VERSION "created by canmatrix"

NS_ :

BS_:

BU_:

BO_ 2649702903 ParameterResponse: 8 Vector__XXX
 SG_ ParameterResponse_MUX M : 0|11@1- (1,0) [-1024|1023] "" Vector__XXX
 SG_ Meta1028 m1479 : 11|3@1+ (1,0) [0|7] "" Vector__XXX
 SG_ ReadParam_status1028 m1479 : 14|2@1+ (1,0) [0|1] "" Vector__XXX
 SG_ TempInvCurrent m1479 : 16|16@1+ (1,0) [0|3000] "A" Vector__XXX
 SG_ Meta1029 m1480 : 11|3@1+ (1,0) [0|7] "" Vector__XXX
 SG_ ReadParam_status1029 m1480 : 14|2@1+ (1,0) [0|1] "" Vector__XXX
 SG_ Mx1CycleLimit m1480 : 32|32@1+ (1,0) [0|4294967295] "" Vector__XXX
 SG_ Meta1030 m1481 : 11|3@1+ (1,0) [0|7] "" Vector__XXX
 SG_ ReadParam_status1030 m1481 : 14|2@1+ (1,0) [0|1] "" Vector__XXX
 SG_ Mx2CyclesLimit m1481 : 32|32@1+ (1,0) [0|4294967295] "" Vector__XXX
 SG_ Meta1031 m1482 : 11|3@1+ (1,0) [0|7] "" Vector__XXX
 SG_ ReadParam_status1031 m1482 : 14|2@1+ (1,0) [0|1] "" Vector__XXX
 SG_ K1CyclesLimit m1482 : 32|32@1+ (1,0) [0|4294967295] "" Vector__XXX
 SG_ Meta1032 m1483 : 11|3@1+ (1,0) [0|7] "" Vector__XXX
 SG_ ReadParam_status1032 m1483 : 14|2@1+ (1,0) [0|1] "" Vector__XXX
 SG_ K2CyclesLimit m1483 : 32|32@1+ (1,0) [0|4294967295] "" Vector__XXX
 SG_ Meta1033 m1484 : 11|3@1+ (1,0) [0|7] "" Vector__XXX
 SG_ ReadParam_status1033 m1484 : 14|2@1+ (1,0) [0|1] "" Vector__XXX
 SG_ MX1CycleCount m1484 : 32|32@1+ (1,0) [0|4294967295] "" Vector__XXX
 SG_ Meta1034 m1485 : 11|3@1+ (1,0) [0|7] "" Vector__XXX
 SG_ ReadParam_status1034 m1485 : 14|2@1+ (1,0) [0|1] "" Vector__XXX
 SG_ MX2CycleCount m1485 : 32|32@1+ (1,0) [0|4294967295] "" Vector__XXX
 SG_ Meta1035 m1486 : 11|3@1+ (1,0) [0|7] "" Vector__XXX
 SG_ ReadParam_status1035 m1486 : 14|2@1+ (1,0) [0|1] "" Vector__XXX
 SG_ K1CycleCount m1486 : 32|32@1+ (1,0) [0|4294967295] "" Vector__XXX
 SG_ Meta1036 m1487 : 11|3@1+ (1,0) [0|7] "" Vector__XXX
 SG_ ReadParam_status1036 m1487 : 14|2@1+ (1,0) [0|1] "" Vector__XXX
 SG_ K2CycleCount m1487 : 32|32@1+ (1,0) [0|4294967295] "" Vector__XXX
 SG_ Meta1037 m1488 : 11|3@1+ (1,0) [0|7] "" Vector__XXX
 SG_ ReadParam_status1037 m1488 : 14|2@1+ (1,0) [0|1] "" Vector__XXX
 SG_ MX1DIIndex m1488 : 16|8@1+ (1,0) [0|200] "" Vector__XXX
 SG_ MX2DIIndex m1488 : 24|8@1+ (1,0) [0|200] "" Vector__XXX
 SG_ K1DIIndex m1488 : 32|8@1+ (1,0) [0|200] "" Vector__XXX
 SG_ K2DIIndex m1488 : 40|8@1+ (1,0) [0|200] "" Vector__XXX
 SG_ Meta1038 m1489 : 11|3@1+ (1,0) [0|7] "" Vector__XXX
 SG_ ReadParam_status1038 m1489 : 14|2@1+ (1,0) [0|1] "" Vector__XXX
 SG_ DO5Command m1489 : 16|2@1+ (1,0) [0|1] "" Vector__XXX
 SG_ DO5Controller m1489 : 18|2@1+ (1,0) [0|1] "" Vector__XXX
 SG_ InvertDI6 m1489 : 20|2@1+ (1,0) [0|1] "" Vector__XXX
 SG_ InvertDI7 m1489 : 22|2@1+ (1,0) [0|1] "" Vector__XXX
 SG_ InvertDI8 m1489 : 24|2@1+ (1,0) [0|1] "" Vector__XXX
 SG_ InvertDI9 m1489 : 26|2@1+ (1,0) [0|1] "" Vector__XXX
 SG_ InvertDO5 m1489 : 28|2@1+ (1,0) [0|1] "" Vector__XXX
 SG_ Meta1039 m1490 : 11|3@1+ (1,0) [0|7] "" Vector__XXX
 SG_ ReadParam_status1039 m1490 : 14|2@1+ (1,0) [1|3] "" Vector__XXX
 SG_ ExternalInhibitFault m1490 : 16|2@1+ (1,0) [0|3] "" Vector__XXX
 SG_ ExternalInhibitState m1490 : 32|16@1+ (1,0) [0|65535] "" Vector__XXX
 SG_ Meta1040 m1491 : 11|3@1+ (1,0) [0|7] "" Vector__XXX
 SG_ ReadParam_status1040 m1491 : 14|2@1+ (1,0) [0|1] "" Vector__XXX
 SG_ enable3 m1491 : 16|2@1+ (1,0) [0|1] "" Vector__XXX
 SG_ forceTime m1491 : 32|16@1- (0.1,0) [0|3270] "ms" Vector__XXX
 SG_ waitTime m1491 : 48|16@1- (0.1,0) [0|3270] "ms" Vector__XXX
 SG_ Meta1041 m1492 : 11|3@1+ (1,0) [0|7] "" Vector__XXX
 SG_ ReadParam_status1041 m1492 : 14|2@1+ (1,0) [0|1] "" Vector__XXX
 SG_ inhibitTime m1492 : 16|16@1- (0.1,0) [0|3270] "ms" Vector__XXX
 SG_ enableAutoSync m1492 : 32|2@1+ (1,0) [0|1] "" Vector__XXX
 SG_ autoSyncTime m1492 : 48|16@1- (0.1,0) [0|3270] "ms" Vector__XXX
 SG_ Meta1042 m1495 : 11|3@1+ (1,0) [0|7] "" Vector__XXX
 SG_ ReadParam_status1042 m1495 : 14|2@1+ (1,0) [0|1] "" Vector__XXX
 SG_ FilterTau m1495 : 16|16@1+ (1,0) [10|15000] "ms" Vector__XXX
 SG_ Meta1043 m1497 : 11|3@1+ (1,0) [0|7] "" Vector__XXX
 SG_ ReadParam_status1043 m1497 : 14|2@1+ (1,0) [0|1] "" Vector__XXX
 SG_ ActiveInterface m1497 : 16|16@1+ (1,0) [0|1] "" Vector__XXX
 SG_ Meta1044 m1500 : 11|3@1+ (1,0) [0|7] "" Vector__XXX
 SG_ ReadParam_status1044 m1500 : 14|2@1+ (1,0) [0|1] "" Vector__XXX
 SG_ MODBUSTimeout m1500 : 16|16@1+ (0.01,0) [0|600.00] "s" Vector__XXX
 SG_ Meta1045 m1501 : 11|3@1+ (1,0) [0|7] "" Vector__XXX
 SG_ ReadParam_status1045 m1501 : 14|2@1+ (1,0) [0|1] "" Vector__XXX
 SG_ stopIRamp m1501 : 16|16@1+ (0.1,0) [0|6000] "A/s" Vector__XXX
 SG_ Meta1046 m1502 : 11|3@1+ (1,0) [0|7] "" Vector__XXX
 SG_ ReadParam_status1046 m1502 : 14|2@1+ (1,0) [0|1] "" Vector__XXX
 SG_ propGain m1502 : 16|16@1+ (0.001,0) [0|50] "V/A" Vector__XXX
 SG_ intGain m1502 : 32|16@1+ (0.001,0) [0|50] "V/A" Vector__XXX
 SG_ antiWupGain m1502 : 48|16@1+ (0.1,0) [0|5000] "V/A" Vector__XXX
 SG_ Meta1047 m1503 : 11|3@1+ (1,0) [0|7] "" Vector__XXX
 SG_ ReadParam_status1047 m1503 : 14|2@1+ (1,0) [0|1] "" Vector__XXX
 SG_ vMeasFilt_Tc m1503 : 16|16@1+ (0.001,0) [0|60] "s" Vector__XXX
 SG_ vRefFilt_Tc m1503 : 32|16@1+ (0.001,0) [0|60] "s" Vector__XXX
 SG_ Meta1048 m1504 : 11|3@1+ (1,0) [0|7] "" Vector__XXX
 SG_ ReadParam_status1048 m1504 : 14|2@1+ (1,0) [0|1] "" Vector__XXX
 SG_ slope0 m1504 : 16|16@1+ (0.1,0) [0|5000] "kVAr/V" Vector__XXX
 SG_ deadband0 m1504 : 32|16@1+ (0.1,0) [0|250] "V" Vector__XXX
 SG_ limit1 m1504 : 48|16@1+ (0.1,0) [0|1400] "kVAr" Vector__XXX
 SG_ Meta1049 m1505 : 11|3@1+ (1,0) [0|7] "" Vector__XXX
 SG_ ReadParam_status1049 m1505 : 14|2@1+ (1,0) [0|1] "" Vector__XXX
 SG_ fMeasFilt_Tc m1505 : 16|16@1+ (0.001,0) [0|60] "s" Vector__XXX
 SG_ fRefFilt_Tc m1505 : 32|16@1+ (0.001,0) [0|60] "ms" Vector__XXX
 SG_ Meta1050 m1506 : 11|3@1+ (1,0) [0|7] "" Vector__XXX
 SG_ ReadParam_status1050 m1506 : 14|2@1+ (1,0) [0|1] "" Vector__XXX
 SG_ slope1 m1506 : 16|16@1+ (0.1,0) [0|5000] "kW/Hz" Vector__XXX
 SG_ deadband1 m1506 : 32|16@1+ (0.001,0) [0|20] "Hz" Vector__XXX
 SG_ limit2 m1506 : 48|16@1+ (0.1,0) [0|1400] "kW" Vector__XXX
 SG_ Meta1051 m1507 : 11|3@1+ (1,0) [0|7] "" Vector__XXX
 SG_ ReadParam_status1051 m1507 : 14|2@1+ (1,0) [0|1] "" Vector__XXX
 SG_ fMeasDerFilt_Tc m1507 : 16|16@1+ (0.001,0) [0|60] "s" Vector__XXX
 SG_ Meta1052 m1508 : 11|3@1+ (1,0) [0|7] "" Vector__XXX
 SG_ ReadParam_status1052 m1508 : 14|2@1+ (1,0) [0|1] "" Vector__XXX
 SG_ gain m1508 : 16|16@1+ (0.01,0) [0|500] "kW/Hz/s" Vector__XXX
 SG_ deadband2 m1508 : 32|16@1+ (0.1,0) [0|5000] "Hz/s" Vector__XXX
 SG_ Meta1053 m1509 : 11|3@1+ (1,0) [0|7] "" Vector__XXX
 SG_ ReadParam_status1053 m1509 : 14|2@1+ (1,0) [0|1] "" Vector__XXX
 SG_ VI_comp_enable m1509 : 16|2@1+ (1,0) [0|1] "" Vector__XXX
 SG_ blackStartVRamp m1509 : 32|16@1+ (0.1,0) [0|5000] "V/s" Vector__XXX
 SG_ Meta1054 m1510 : 11|3@1+ (1,0) [0|7] "" Vector__XXX
 SG_ ReadParam_status1054 m1510 : 14|2@1+ (1,0) [0|1] "" Vector__XXX
 SG_ vLimMax m1510 : 16|16@1+ (0.1,0) [0|1000] "V" Vector__XXX
 SG_ vLimMin m1510 : 32|16@1+ (0.1,0) [0|1000] "V" Vector__XXX
 SG_ Meta1055 m1511 : 11|3@1+ (1,0) [0|7] "" Vector__XXX
 SG_ ReadParam_status1055 m1511 : 14|2@1+ (1,0) [0|1] "" Vector__XXX
 SG_ fLimMax m1511 : 16|16@1+ (0.01,0) [0|120] "Hz" Vector__XXX
 SG_ fLimMin m1511 : 32|16@1+ (0.01,0) [0|120] "Hz" Vector__XXX
 SG_ Meta1056 m1512 : 11|3@1+ (1,0) [0|7] "" Vector__XXX
 SG_ ReadParam_status1056 m1512 : 14|2@1+ (1,0) [0|1] "" Vector__XXX
 SG_ vDroop m1512 : 16|16@1+ (0.01,0) [0|100] "%" Vector__XXX
 SG_ fDroop m1512 : 32|16@1+ (0.01,0) [0|100] "%" Vector__XXX
 SG_ Meta1057 m1513 : 11|3@1+ (1,0) [0|7] "" Vector__XXX
 SG_ ReadParam_status1057 m1513 : 14|2@1+ (1,0) [0|1] "" Vector__XXX
 SG_ vDeadband m1513 : 16|16@1+ (0.1,0) [0|200] "V" Vector__XXX
 SG_ fDeadband m1513 : 32|16@1+ (0.001,0) [0|20] "Hz" Vector__XXX
 SG_ Meta1058 m1514 : 11|3@1+ (1,0) [0|7] "" Vector__XXX
 SG_ ReadParam_status1058 m1514 : 14|2@1+ (1,0) [0|1] "" Vector__XXX
 SG_ avr_propGain m1514 : 16|16@1+ (0.1,0) [0|500] "" Vector__XXX
 SG_ avr_intGain m1514 : 32|16@1+ (0.001,0) [0|50] "" Vector__XXX
 SG_ avr_antiWupGain m1514 : 48|16@1+ (0.1,0) [0.000|6500.000] "" Vector__XXX
 SG_ Meta1059 m1515 : 11|3@1+ (1,0) [0|7] "" Vector__XXX
 SG_ ReadParam_status1059 m1515 : 14|2@1+ (1,0) [0|1] "" Vector__XXX
 SG_ gov_propGain m1515 : 16|16@1+ (0.1,0) [0|500] "" Vector__XXX
 SG_ gov_intGain m1515 : 32|16@1+ (0.001,0) [0|50] "" Vector__XXX
 SG_ gov_antiWupGain m1515 : 48|16@1+ (0.1,0) [0.000|6500.000] "" Vector__XXX
 SG_ Meta1060 m1516 : 11|3@1+ (1,0) [0|7] "" Vector__XXX
 SG_ ReadParam_status1060 m1516 : 14|2@1+ (1,0) [0|1] "" Vector__XXX
 SG_ var_propGain m1516 : 16|16@1+ (0.001,0) [0|10] "" Vector__XXX
 SG_ var_intGain m1516 : 32|16@1+ (0.001,0) [0|50] "" Vector__XXX
 SG_ var_antiWupGain m1516 : 48|16@1+ (0.1,0) [0.000|6500.000] "" Vector__XXX
 SG_ Meta1061 m1517 : 11|3@1+ (1,0) [0|7] "" Vector__XXX
 SG_ ReadParam_status1061 m1517 : 14|2@1+ (1,0) [0|1] "" Vector__XXX
 SG_ vin_damp m1517 : 16|16@1+ (0.001,0) [0|10] "" Vector__XXX
 SG_ vin_H_sec m1517 : 32|16@1+ (0.001,0) [0.001|60] "" Vector__XXX
 SG_ vin_antiWupGain m1517 : 48|16@1+ (0.1,0) [0.000|6500.000] "" Vector__XXX
 SG_ Meta1062 m1518 : 11|3@1+ (1,0) [0|7] "" Vector__XXX
 SG_ ReadParam_status1062 m1518 : 14|2@1+ (1,0) [0|1] "" Vector__XXX
 SG_ block_vErr_pct m1518 : 16|16@1+ (0.01,0) [0.000|200.000] "" Vector__XXX
 SG_ block_qErr_pct m1518 : 32|16@1+ (0.01,0) [0.000|200.000] "" Vector__XXX
 SG_ block_onDelay_ms m1518 : 48|16@1+ (0.1,0) [0.000|6000.000] "" Vector__XXX
 SG_ Meta1063 m1519 : 11|3@1+ (1,0) [0|7] "" Vector__XXX
 SG_ ReadParam_status1063 m1519 : 14|2@1+ (1,0) [0|1] "" Vector__XXX
 SG_ ramp_power0 m1519 : 16|16@1+ (0.1,0) [0|5000] "kW" Vector__XXX
 SG_ ramp_time0 m1519 : 32|16@1+ (0.001,0) [0|60] "s" Vector__XXX
 SG_ Meta1064 m1520 : 11|3@1+ (1,0) [0|7] "" Vector__XXX
 SG_ ReadParam_status1064 m1520 : 14|2@1+ (1,0) [0|1] "" Vector__XXX
 SG_ ramp_power1 m1520 : 16|16@1+ (0.1,0) [0|5000] "kW" Vector__XXX
 SG_ ramp_time1 m1520 : 32|16@1+ (0.001,0) [0|60] "s" Vector__XXX
 SG_ Meta1065 m1521 : 11|3@1+ (1,0) [0|7] "" Vector__XXX
 SG_ ReadParam_status1065 m1521 : 14|2@1+ (1,0) [0|1] "" Vector__XXX
 SG_ vFilterTrPa m1521 : 16|16@1+ (0.001,0) [0|60] "s" Vector__XXX
 SG_ Meta1066 m1522 : 11|3@1+ (1,0) [0|7] "" Vector__XXX
 SG_ ReadParam_status1066 m1522 : 14|2@1+ (1,0) [0|1] "" Vector__XXX
 SG_ NumActivePoints24 m1522 : 48|16@1+ (1,0) [0|20] "" Vector__XXX
 SG_ Meta1067 m1523 : 11|3@1+ (1,0) [0|7] "" Vector__XXX
 SG_ ReadParam_status1067 m1523 : 14|2@1+ (1,0) [0|1] "" Vector__XXX
 SG_ _0148 m1523 : 16|16@1- (0.1,0) [-3276.8|3276.7] "% nominal Power" Vector__XXX
 SG_ _0248 m1523 : 32|16@1- (0.1,0) [-3276.8|3276.7] "% nominal Power" Vector__XXX
 SG_ _0348 m1523 : 48|16@1- (0.1,0) [-3276.8|3276.7] "% nominal Power" Vector__XXX
 SG_ Meta1068 m1524 : 11|3@1+ (1,0) [0|7] "" Vector__XXX
 SG_ ReadParam_status1068 m1524 : 14|2@1+ (1,0) [0|1] "" Vector__XXX
 SG_ _0448 m1524 : 16|16@1- (0.1,0) [-3276.8|3276.7] "% nominal Power" Vector__XXX
 SG_ _0548 m1524 : 32|16@1- (0.1,0) [-3276.8|3276.7] "% nominal Power" Vector__XXX
 SG_ _0648 m1524 : 48|16@1- (0.1,0) [-3276.8|3276.7] "% nominal Power" Vector__XXX
 SG_ Meta1069 m1525 : 11|3@1+ (1,0) [0|7] "" Vector__XXX
 SG_ ReadParam_status1069 m1525 : 14|2@1+ (1,0) [0|1] "" Vector__XXX
 SG_ _0748 m1525 : 16|16@1- (0.1,0) [-3276.8|3276.7] "% nominal Power" Vector__XXX
 SG_ _0848 m1525 : 32|16@1- (0.1,0) [-3276.8|3276.7] "% nominal Power" Vector__XXX
 SG_ _0948 m1525 : 48|16@1- (0.1,0) [-3276.8|3276.7] "% nominal Power" Vector__XXX
 SG_ Meta1070 m1526 : 11|3@1+ (1,0) [0|7] "" Vector__XXX
 SG_ ReadParam_status1070 m1526 : 14|2@1+ (1,0) [0|1] "" Vector__XXX
 SG_ _1048 m1526 : 16|16@1- (0.1,0) [-3276.8|3276.7] "% nominal Power" Vector__XXX
 SG_ _1148 m1526 : 32|16@1- (0.1,0) [-3276.8|3276.7] "% nominal Power" Vector__XXX
 SG_ _1248 m1526 : 48|16@1- (0.1,0) [-3276.8|3276.7] "% nominal Power" Vector__XXX
 SG_ Meta1071 m1527 : 11|3@1+ (1,0) [0|7] "" Vector__XXX
 SG_ ReadParam_status1071 m1527 : 14|2@1+ (1,0) [0|1] "" Vector__XXX
 SG_ _1348 m1527 : 16|16@1- (0.1,0) [-3276.8|3276.7] "% nominal Power" Vector__XXX
 SG_ _1448 m1527 : 32|16@1- (0.1,0) [-3276.8|3276.7] "% nominal Power" Vector__XXX
 SG_ _1548 m1527 : 48|16@1- (0.1,0) [-3276.8|3276.7] "% nominal Power" Vector__XXX
 SG_ Meta1072 m1528 : 11|3@1+ (1,0) [0|7] "" Vector__XXX
 SG_ ReadParam_status1072 m1528 : 14|2@1+ (1,0) [0|1] "" Vector__XXX
 SG_ _1648 m1528 : 16|16@1- (0.1,0) [-3276.8|3276.7] "% nominal Power" Vector__XXX
 SG_ _1748 m1528 : 32|16@1- (0.1,0) [-3276.8|3276.7] "% nominal Power" Vector__XXX
 SG_ _1848 m1528 : 48|16@1- (0.1,0) [-3276.8|3276.7] "% nominal Power" Vector__XXX
 SG_ Meta1073 m1529 : 11|3@1+ (1,0) [0|7] "" Vector__XXX
 SG_ ReadParam_status1073 m1529 : 14|2@1+ (1,0) [0|1] "" Vector__XXX
 SG_ _1948 m1529 : 16|16@1- (0.1,0) [-3276.8|3276.7] "% nominal Power" Vector__XXX
 SG_ _2048 m1529 : 32|16@1- (0.1,0) [-3276.8|3276.7] "% nominal Power" Vector__XXX
 SG_ Meta1074 m1530 : 11|3@1+ (1,0) [0|7] "" Vector__XXX
 SG_ ReadParam_status1074 m1530 : 14|2@1+ (1,0) [0|1] "" Vector__XXX
 SG_ _0149 m1530 : 16|16@1- (0.1,0) [-3276.8|3276.7] "% nominal VAr" Vector__XXX
 SG_ _0249 m1530 : 32|16@1- (0.1,0) [-3276.8|3276.7] "% nominal VAr" Vector__XXX
 SG_ _0349 m1530 : 48|16@1- (0.1,0) [-3276.8|3276.7] "% nominal VAr" Vector__XXX
 SG_ Meta1075 m1531 : 11|3@1+ (1,0) [0|7] "" Vector__XXX
 SG_ ReadParam_status1075 m1531 : 14|2@1+ (1,0) [0|1] "" Vector__XXX
 SG_ _0449 m1531 : 16|16@1- (0.1,0) [-3276.8|3276.7] "% nominal VAr" Vector__XXX
 SG_ _0549 m1531 : 32|16@1- (0.1,0) [-3276.8|3276.7] "% nominal VAr" Vector__XXX
 SG_ _0649 m1531 : 48|16@1- (0.1,0) [-3276.8|3276.7] "% nominal VAr" Vector__XXX
 SG_ Meta1076 m1532 : 11|3@1+ (1,0) [0|7] "" Vector__XXX
 SG_ ReadParam_status1076 m1532 : 14|2@1+ (1,0) [0|1] "" Vector__XXX
 SG_ _0749 m1532 : 16|16@1- (0.1,0) [-3276.8|3276.7] "% nominal VAr" Vector__XXX
 SG_ _0849 m1532 : 32|16@1- (0.1,0) [-3276.8|3276.7] "% nominal VAr" Vector__XXX
 SG_ _0949 m1532 : 48|16@1- (0.1,0) [-3276.8|3276.7] "% nominal VAr" Vector__XXX
 SG_ Meta1077 m1533 : 11|3@1+ (1,0) [0|7] "" Vector__XXX
 SG_ ReadParam_status1077 m1533 : 14|2@1+ (1,0) [0|1] "" Vector__XXX
 SG_ _1049 m1533 : 16|16@1- (0.1,0) [-3276.8|3276.7] "% nominal VAr" Vector__XXX
 SG_ _1149 m1533 : 32|16@1- (0.1,0) [-3276.8|3276.7] "% nominal VAr" Vector__XXX
 SG_ _1249 m1533 : 48|16@1- (0.1,0) [-3276.8|3276.7] "% nominal VAr" Vector__XXX
 SG_ Meta1078 m1534 : 11|3@1+ (1,0) [0|7] "" Vector__XXX
 SG_ ReadParam_status1078 m1534 : 14|2@1+ (1,0) [0|1] "" Vector__XXX
 SG_ _1349 m1534 : 16|16@1- (0.1,0) [-3276.8|3276.7] "% nominal VAr" Vector__XXX
 SG_ _1449 m1534 : 32|16@1- (0.1,0) [-3276.8|3276.7] "% nominal VAr" Vector__XXX
 SG_ _1549 m1534 : 48|16@1- (0.1,0) [-3276.8|3276.7] "% nominal VAr" Vector__XXX
 SG_ Meta1079 m1535 : 11|3@1+ (1,0) [0|7] "" Vector__XXX
 SG_ ReadParam_status1079 m1535 : 14|2@1+ (1,0) [0|1] "" Vector__XXX
 SG_ _1649 m1535 : 16|16@1- (0.1,0) [-3276.8|3276.7] "% nominal VAr" Vector__XXX
 SG_ _1749 m1535 : 32|16@1- (0.1,0) [-3276.8|3276.7] "% nominal VAr" Vector__XXX
 SG_ _1849 m1535 : 48|16@1- (0.1,0) [-3276.8|3276.7] "% nominal VAr" Vector__XXX
 SG_ Meta1080 m1536 : 11|3@1+ (1,0) [0|7] "" Vector__XXX
 SG_ ReadParam_status1080 m1536 : 14|2@1+ (1,0) [0|1] "" Vector__XXX
 SG_ _1949 m1536 : 16|16@1- (0.1,0) [-3276.8|3276.7] "% nominal VAr" Vector__XXX
 SG_ _2049 m1536 : 32|16@1- (0.1,0) [-3276.8|3276.7] "% nominal VAr" Vector__XXX
 SG_ Meta1081 m1537 : 11|3@1+ (1,0) [0|7] "" Vector__XXX
 SG_ ReadParam_status1081 m1537 : 14|2@1+ (1,0) [0|1] "" Vector__XXX
 SG_ RampRateDecrement8 m1537 : 32|16@1+ (1,0) [0|65535] "%/minute" Vector__XXX
 SG_ RampRateIncrement8 m1537 : 48|16@1+ (1,0) [0|65535] "%/minute" Vector__XXX
 SG_ Meta1082 m1538 : 11|3@1+ (1,0) [0|7] "" Vector__XXX
 SG_ ReadParam_status1082 m1538 : 14|2@1+ (1,0) [0|1] "" Vector__XXX
 SG_ NumActivePoints25 m1538 : 48|16@1+ (1,0) [0|20] "" Vector__XXX
 SG_ Meta1083 m1539 : 11|3@1+ (1,0) [0|7] "" Vector__XXX
 SG_ ReadParam_status1083 m1539 : 14|2@1+ (1,0) [0|1] "" Vector__XXX
 SG_ _0150 m1539 : 16|16@1- (0.1,0) [-3276.8|3276.7] "% nominal Power" Vector__XXX
 SG_ _0250 m1539 : 32|16@1- (0.1,0) [-3276.8|3276.7] "% nominal Power" Vector__XXX
 SG_ _0350 m1539 : 48|16@1- (0.1,0) [-3276.8|3276.7] "% nominal Power" Vector__XXX
 SG_ Meta1084 m1540 : 11|3@1+ (1,0) [0|7] "" Vector__XXX
 SG_ ReadParam_status1084 m1540 : 14|2@1+ (1,0) [0|1] "" Vector__XXX
 SG_ _0450 m1540 : 16|16@1- (0.1,0) [-3276.8|3276.7] "% nominal Power" Vector__XXX
 SG_ _0550 m1540 : 32|16@1- (0.1,0) [-3276.8|3276.7] "% nominal Power" Vector__XXX
 SG_ _0650 m1540 : 48|16@1- (0.1,0) [-3276.8|3276.7] "% nominal Power" Vector__XXX
 SG_ Meta1085 m1541 : 11|3@1+ (1,0) [0|7] "" Vector__XXX
 SG_ ReadParam_status1085 m1541 : 14|2@1+ (1,0) [0|1] "" Vector__XXX
 SG_ _0750 m1541 : 16|16@1- (0.1,0) [-3276.8|3276.7] "% nominal Power" Vector__XXX
 SG_ _0850 m1541 : 32|16@1- (0.1,0) [-3276.8|3276.7] "% nominal Power" Vector__XXX
 SG_ _0950 m1541 : 48|16@1- (0.1,0) [-3276.8|3276.7] "% nominal Power" Vector__XXX
 SG_ Meta1086 m1542 : 11|3@1+ (1,0) [0|7] "" Vector__XXX
 SG_ ReadParam_status1086 m1542 : 14|2@1+ (1,0) [0|1] "" Vector__XXX
 SG_ _1050 m1542 : 16|16@1- (0.1,0) [-3276.8|3276.7] "% nominal Power" Vector__XXX
 SG_ _1150 m1542 : 32|16@1- (0.1,0) [-3276.8|3276.7] "% nominal Power" Vector__XXX
 SG_ _1250 m1542 : 48|16@1- (0.1,0) [-3276.8|3276.7] "% nominal Power" Vector__XXX
 SG_ Meta1087 m1543 : 11|3@1+ (1,0) [0|7] "" Vector__XXX
 SG_ ReadParam_status1087 m1543 : 14|2@1+ (1,0) [0|1] "" Vector__XXX
 SG_ _1350 m1543 : 16|16@1- (0.1,0) [-3276.8|3276.7] "% nominal Power" Vector__XXX
 SG_ _1450 m1543 : 32|16@1- (0.1,0) [-3276.8|3276.7] "% nominal Power" Vector__XXX
 SG_ _1550 m1543 : 48|16@1- (0.1,0) [-3276.8|3276.7] "% nominal Power" Vector__XXX
 SG_ Meta1088 m1544 : 11|3@1+ (1,0) [0|7] "" Vector__XXX
 SG_ ReadParam_status1088 m1544 : 14|2@1+ (1,0) [0|1] "" Vector__XXX
 SG_ _1650 m1544 : 16|16@1- (0.1,0) [-3276.8|3276.7] "% nominal Power" Vector__XXX
 SG_ _1750 m1544 : 32|16@1- (0.1,0) [-3276.8|3276.7] "% nominal Power" Vector__XXX
 SG_ _1850 m1544 : 48|16@1- (0.1,0) [-3276.8|3276.7] "% nominal Power" Vector__XXX
 SG_ Meta1089 m1545 : 11|3@1+ (1,0) [0|7] "" Vector__XXX
 SG_ ReadParam_status1089 m1545 : 14|2@1+ (1,0) [0|1] "" Vector__XXX
 SG_ _1950 m1545 : 16|16@1- (0.1,0) [-3276.8|3276.7] "% nominal Power" Vector__XXX
 SG_ _2050 m1545 : 32|16@1- (0.1,0) [-3276.8|3276.7] "% nominal Power" Vector__XXX
 SG_ Meta1090 m1546 : 11|3@1+ (1,0) [0|7] "" Vector__XXX
 SG_ ReadParam_status1090 m1546 : 14|2@1+ (1,0) [0|1] "" Vector__XXX
 SG_ _0151 m1546 : 16|16@1- (0.1,0) [-3276.8|3276.7] "% nominal VAr" Vector__XXX
 SG_ _0251 m1546 : 32|16@1- (0.1,0) [-3276.8|3276.7] "% nominal VAr" Vector__XXX
 SG_ _0351 m1546 : 48|16@1- (0.1,0) [-3276.8|3276.7] "% nominal VAr" Vector__XXX
 SG_ Meta1091 m1547 : 11|3@1+ (1,0) [0|7] "" Vector__XXX
 SG_ ReadParam_status1091 m1547 : 14|2@1+ (1,0) [0|1] "" Vector__XXX
 SG_ _0451 m1547 : 16|16@1- (0.1,0) [-3276.8|3276.7] "% nominal VAr" Vector__XXX
 SG_ _0551 m1547 : 32|16@1- (0.1,0) [-3276.8|3276.7] "% nominal VAr" Vector__XXX
 SG_ _0651 m1547 : 48|16@1- (0.1,0) [-3276.8|3276.7] "% nominal VAr" Vector__XXX
 SG_ Meta1092 m1548 : 11|3@1+ (1,0) [0|7] "" Vector__XXX
 SG_ ReadParam_status1092 m1548 : 14|2@1+ (1,0) [0|1] "" Vector__XXX
 SG_ _0751 m1548 : 16|16@1- (0.1,0) [-3276.8|3276.7] "% nominal VAr" Vector__XXX
 SG_ _0851 m1548 : 32|16@1- (0.1,0) [-3276.8|3276.7] "% nominal VAr" Vector__XXX
 SG_ _0951 m1548 : 48|16@1- (0.1,0) [-3276.8|3276.7] "% nominal VAr" Vector__XXX
 SG_ Meta1093 m1549 : 11|3@1+ (1,0) [0|7] "" Vector__XXX
 SG_ ReadParam_status1093 m1549 : 14|2@1+ (1,0) [0|1] "" Vector__XXX
 SG_ _1051 m1549 : 16|16@1- (0.1,0) [-3276.8|3276.7] "% nominal VAr" Vector__XXX
 SG_ _1151 m1549 : 32|16@1- (0.1,0) [-3276.8|3276.7] "% nominal VAr" Vector__XXX
 SG_ _1251 m1549 : 48|16@1- (0.1,0) [-3276.8|3276.7] "% nominal VAr" Vector__XXX
 SG_ Meta1094 m1550 : 11|3@1+ (1,0) [0|7] "" Vector__XXX
 SG_ ReadParam_status1094 m1550 : 14|2@1+ (1,0) [0|1] "" Vector__XXX
 SG_ _1351 m1550 : 16|16@1- (0.1,0) [-3276.8|3276.7] "% nominal VAr" Vector__XXX
 SG_ _1451 m1550 : 32|16@1- (0.1,0) [-3276.8|3276.7] "% nominal VAr" Vector__XXX
 SG_ _1551 m1550 : 48|16@1- (0.1,0) [-3276.8|3276.7] "% nominal VAr" Vector__XXX
 SG_ Meta1095 m1551 : 11|3@1+ (1,0) [0|7] "" Vector__XXX
 SG_ ReadParam_status1095 m1551 : 14|2@1+ (1,0) [0|1] "" Vector__XXX
 SG_ _1651 m1551 : 16|16@1- (0.1,0) [-3276.8|3276.7] "% nominal VAr" Vector__XXX
 SG_ _1751 m1551 : 32|16@1- (0.1,0) [-3276.8|3276.7] "% nominal VAr" Vector__XXX
 SG_ _1851 m1551 : 48|16@1- (0.1,0) [-3276.8|3276.7] "% nominal VAr" Vector__XXX
 SG_ Meta1096 m1552 : 11|3@1+ (1,0) [0|7] "" Vector__XXX
 SG_ ReadParam_status1096 m1552 : 14|2@1+ (1,0) [0|1] "" Vector__XXX
 SG_ _1951 m1552 : 16|16@1- (0.1,0) [-3276.8|3276.7] "% nominal VAr" Vector__XXX
 SG_ _2051 m1552 : 32|16@1- (0.1,0) [-3276.8|3276.7] "% nominal VAr" Vector__XXX
 SG_ Meta1097 m1553 : 11|3@1+ (1,0) [0|7] "" Vector__XXX
 SG_ ReadParam_status1097 m1553 : 14|2@1+ (1,0) [0|1] "" Vector__XXX
 SG_ RampRateDecrement9 m1553 : 32|16@1+ (1,0) [0|65535] "%/minute" Vector__XXX
 SG_ RampRateIncrement9 m1553 : 48|16@1+ (1,0) [0|65535] "%/minute" Vector__XXX
 SG_ Meta1098 m1586 : 11|3@1+ (1,0) [0|7] "" Vector__XXX
 SG_ ReadParam_status1098 m1586 : 14|2@1+ (1,0) [0|1] "" Vector__XXX
 SG_ phiAbs3 m1586 : 16|16@1+ (0.01,0) [0|360] "deg" Vector__XXX
 SG_ Meta1099 m1587 : 11|3@1+ (1,0) [0|7] "" Vector__XXX
 SG_ ReadParam_status1099 m1587 : 14|2@1+ (1,0) [0|1] "" Vector__XXX
 SG_ phiAbs4 m1587 : 16|16@1+ (0.01,0) [0|360] "deg" Vector__XXX
 SG_ Meta1100 m1588 : 11|3@1+ (1,0) [0|7] "" Vector__XXX
 SG_ ReadParam_status1100 m1588 : 14|2@1+ (1,0) [0|1] "" Vector__XXX
 SG_ phiAbs5 m1588 : 16|16@1+ (0.01,0) [0|360] "deg" Vector__XXX
 SG_ Meta1101 m1589 : 11|3@1+ (1,0) [0|7] "" Vector__XXX
 SG_ ReadParam_status1101 m1589 : 14|2@1+ (1,0) [0|1] "" Vector__XXX
 SG_ Trigger m1589 : 16|2@1+ (1,0) [0|1] "" Vector__XXX
 SG_ allowWPhaseOV m1589 : 18|2@1+ (1,0) [0|1] "" Vector__XXX
 SG_ Delay m1589 : 32|16@1+ (1,0) [0|1000] "ms" Vector__XXX
 SG_ Duration m1589 : 48|16@1+ (1,0) [0|65500] "ms" Vector__XXX
 SG_ Meta1102 m1590 : 11|3@1+ (1,0) [0|7] "" Vector__XXX
 SG_ ReadParam_status1102 m1590 : 14|2@1+ (1,0) [0|1] "" Vector__XXX
 SG_ Enable8 m1590 : 16|2@1+ (1,0) [0|1] "" Vector__XXX
 SG_ fFiltTau m1590 : 32|16@1+ (0.01,0) [0.01|30] "s" Vector__XXX
 SG_ Meta1103 m1591 : 11|3@1+ (1,0) [0|7] "" Vector__XXX
 SG_ ReadParam_status1103 m1591 : 14|2@1+ (1,0) [0|1] "" Vector__XXX
 SG_ db_OF m1591 : 16|16@1+ (0.001,0) [0.01|0.5] "Hz" Vector__XXX
 SG_ db_UF m1591 : 32|16@1+ (0.001,0) [0.01|0.5] "Hz" Vector__XXX
 SG_ Meta1104 m1592 : 11|3@1+ (1,0) [0|7] "" Vector__XXX
 SG_ ReadParam_status1104 m1592 : 14|2@1+ (1,0) [0|1] "" Vector__XXX
 SG_ droop_OF m1592 : 16|16@1+ (0.01,0) [0|1] "" Vector__XXX
 SG_ droop_UF m1592 : 32|16@1+ (0.01,0) [0|1] "" Vector__XXX
 SG_ Meta1105 m1593 : 11|3@1+ (1,0) [0|7] "" Vector__XXX
 SG_ ReadParam_status1105 m1593 : 14|2@1+ (1,0) [0|1] "" Vector__XXX
 SG_ LogDataEnable m1593 : 16|2@1+ (1,0) [0|1] "" Vector__XXX
 SG_ Meta1106 m1596 : 11|3@1+ (1,0) [0|7] "" Vector__XXX
 SG_ ReadParam_status1106 m1596 : 14|2@1+ (1,0) [0|1] "" Vector__XXX
 SG_ RefMode m1596 : 16|16@1+ (1,0) [0|1] "" Vector__XXX
 SG_ AutoVrefFilterTimeConst m1596 : 32|16@1+ (0.1,0) [0.1|5000] "s" Vector__XXX
 SG_ FixedVref m1596 : 48|16@1+ (0.1,0) [50|150] "%" Vector__XXX
 SG_ Meta1107 m1597 : 11|3@1+ (1,0) [0|7] "" Vector__XXX
 SG_ ReadParam_status1107 m1597 : 14|2@1+ (1,0) [0|1] "" Vector__XXX
 SG_ kneePower1 m1597 : 16|16@1- (0.1,0) [-100|100] "%" Vector__XXX
 SG_ kneePower2 m1597 : 32|16@1- (0.1,0) [-100|100] "%" Vector__XXX
 SG_ Meta1108 m1599 : 11|3@1+ (1,0) [0|7] "" Vector__XXX
 SG_ ReadParam_status1108 m1599 : 14|2@1+ (1,0) [0|1] "" Vector__XXX
 SG_ PtoP_gain m1599 : 16|16@1- (0.001,0) [-1|1] "kW/kW" Vector__XXX
 SG_ PtoQ_gain m1599 : 32|16@1- (0.001,0) [-1|1] "kVar/kW" Vector__XXX
 SG_ Meta1109 m1600 : 11|3@1+ (1,0) [0|7] "" Vector__XXX
 SG_ ReadParam_status1109 m1600 : 14|2@1+ (1,0) [0|1] "" Vector__XXX
 SG_ QtoP_gain m1600 : 16|16@1- (0.001,0) [-1|1] "kW/kVar" Vector__XXX
 SG_ QtoQ_gain m1600 : 32|16@1- (0.001,0) [-1|1] "kVar/kVar" Vector__XXX
 SG_ Meta1110 m1601 : 11|3@1+ (1,0) [0|7] "" Vector__XXX
 SG_ ReadParam_status1110 m1601 : 14|2@1+ (1,0) [0|1] "" Vector__XXX
 SG_ Pneg_Qpos0 m1601 : 16|16@1- (0.1,0) [-1000|1000] "kW" Vector__XXX
 SG_ Pneg_Q00 m1601 : 32|16@1- (0.1,0) [-1000|1000] "kW" Vector__XXX
 SG_ Pneg_Qneg0 m1601 : 48|16@1- (0.1,0) [-1000|1000] "kW" Vector__XXX
 SG_ Meta1111 m1602 : 11|3@1+ (1,0) [0|7] "" Vector__XXX
 SG_ ReadParam_status1111 m1602 : 14|2@1+ (1,0) [0|1] "" Vector__XXX
 SG_ P0_Qpos0 m1602 : 16|16@1- (0.1,0) [-1000|1000] "kW" Vector__XXX
 SG_ P0_Qneg0 m1602 : 32|16@1- (0.1,0) [-1000|1000] "kW" Vector__XXX
 SG_ MeaspointPref m1602 : 48|16@1- (0.1,0) [1|2000] "kW" Vector__XXX
 SG_ Meta1112 m1603 : 11|3@1+ (1,0) [0|7] "" Vector__XXX
 SG_ ReadParam_status1112 m1603 : 14|2@1+ (1,0) [0|1] "" Vector__XXX
 SG_ Ppos_Qpos0 m1603 : 16|16@1- (0.1,0) [-1000|1000] "kW" Vector__XXX
 SG_ Ppos_Q00 m1603 : 32|16@1- (0.1,0) [-1000|1000] "kW" Vector__XXX
 SG_ Ppos_Qneg0 m1603 : 48|16@1- (0.1,0) [-1000|1000] "kW" Vector__XXX
 SG_ Meta1113 m1604 : 11|3@1+ (1,0) [0|7] "" Vector__XXX
 SG_ ReadParam_status1113 m1604 : 14|2@1+ (1,0) [0|1] "" Vector__XXX
 SG_ Pneg_Qpos1 m1604 : 16|16@1- (0.1,0) [-1000|1000] "kVar" Vector__XXX
 SG_ Pneg_Q01 m1604 : 32|16@1- (0.1,0) [-1000|1000] "kVar" Vector__XXX
 SG_ Pneg_Qneg1 m1604 : 48|16@1- (0.1,0) [-1000|1000] "kVar" Vector__XXX
 SG_ Meta1114 m1605 : 11|3@1+ (1,0) [0|7] "" Vector__XXX
 SG_ ReadParam_status1114 m1605 : 14|2@1+ (1,0) [0|1] "" Vector__XXX
 SG_ P0_Qpos1 m1605 : 16|16@1- (0.1,0) [-1000|1000] "kVar" Vector__XXX
 SG_ P0_Qneg1 m1605 : 32|16@1- (0.1,0) [-1000|1000] "kVar" Vector__XXX
 SG_ MeaspointQref m1605 : 48|16@1- (0.1,0) [1|2000] "kVar" Vector__XXX
 SG_ Meta1115 m1606 : 11|3@1+ (1,0) [0|7] "" Vector__XXX
 SG_ ReadParam_status1115 m1606 : 14|2@1+ (1,0) [0|1] "" Vector__XXX
 SG_ Ppos_Qpos1 m1606 : 16|16@1- (0.1,0) [-1000|1000] "kVar" Vector__XXX
 SG_ Ppos_Q01 m1606 : 32|16@1- (0.1,0) [-1000|1000] "kVar" Vector__XXX
 SG_ Ppos_Qneg1 m1606 : 48|16@1- (0.1,0) [-1000|1000] "kVar" Vector__XXX

BO_ 2582594039 CCPResponse: 8 Vector__XXX
 SG_ CCPResponse_MUX M : 0|8@1- (1,0) [-128|127] "" Vector__XXX
 SG_ CommandCounter0 m0 : 16|8@1+ (1,0) [0|255] "" Vector__XXX
 SG_ CommandReturnCode0 m0 : 8|8@1+ (1,0) [0|255] "" Vector__XXX
 SG_ CommandCounter1 m1 : 16|8@1+ (1,0) [0|255] "" Vector__XXX
 SG_ CommandReturnCode1 m1 : 8|8@1+ (1,0) [0|255] "" Vector__XXX
 SG_ CommandCounter2 m2 : 16|8@1+ (1,0) [0|255] "" Vector__XXX
 SG_ CommandReturnCode2 m2 : 8|8@1+ (1,0) [0|255] "" Vector__XXX
 SG_ CommandCounter3 m4 : 16|8@1+ (1,0) [0|255] "" Vector__XXX
 SG_ CommandReturnCode3 m4 : 8|8@1+ (1,0) [0|255] "" Vector__XXX
 SG_ Byte0 m4 : 24|8@1+ (1,0) [0|255] "" Vector__XXX
 SG_ Byte1 m4 : 32|8@1+ (1,0) [0|255] "" Vector__XXX
 SG_ Byte2 m4 : 40|8@1+ (1,0) [0|255] "" Vector__XXX
 SG_ Byte3 m4 : 48|8@1+ (1,0) [0|255] "" Vector__XXX
 SG_ Byte4 m4 : 56|8@1+ (1,0) [0|255] "" Vector__XXX
 SG_ CommandCounter4 m7 : 16|8@1+ (1,0) [0|255] "" Vector__XXX
 SG_ CommandReturnCode4 m7 : 8|8@1+ (1,0) [0|255] "" Vector__XXX

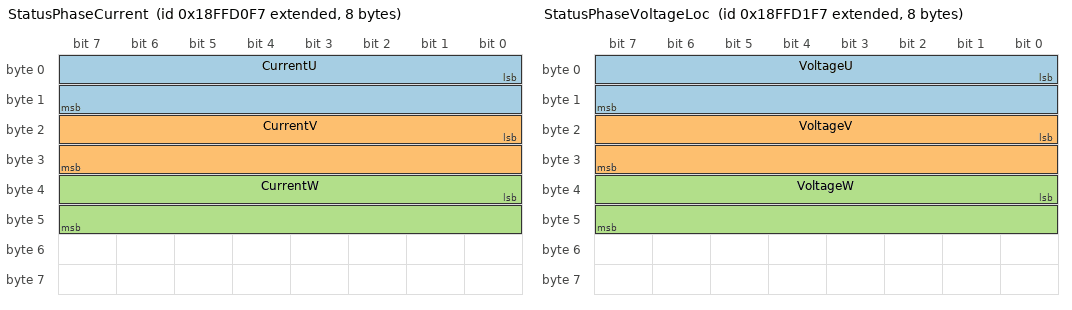
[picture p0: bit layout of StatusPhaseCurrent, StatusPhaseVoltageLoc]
BO_ 2566902007 StatusPhaseCurrent: 8 Vector__XXX
 SG_ CurrentU : 0|16@1+ (1,0) [0|65535] "A" Vector__XXX
 SG_ CurrentV : 16|16@1+ (1,0) [0|65535] "A" Vector__XXX
 SG_ CurrentW : 32|16@1+ (1,0) [0|65535] "A" Vector__XXX

BO_ 2566902263 StatusPhaseVoltageLoc: 8 Vector__XXX
 SG_ VoltageU : 0|16@1+ (0.1,0) [0|6553.5] "V" Vector__XXX
 SG_ VoltageV : 16|16@1+ (0.1,0) [0|6553.5] "V" Vector__XXX
 SG_ VoltageW : 32|16@1+ (0.1,0) [0|6553.5] "V" Vector__XXX

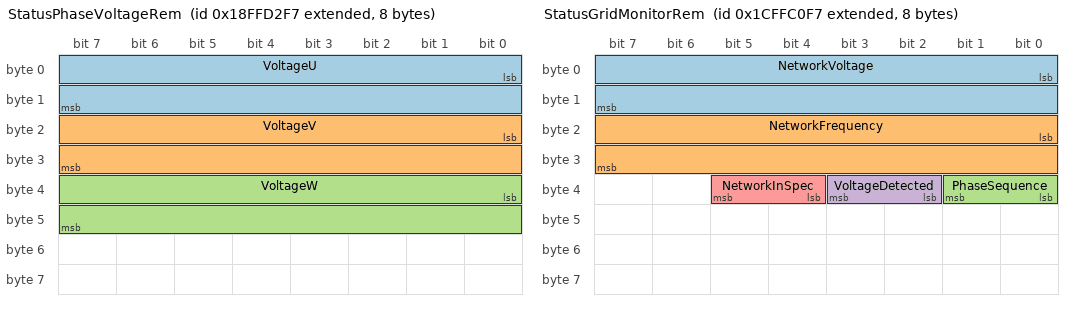
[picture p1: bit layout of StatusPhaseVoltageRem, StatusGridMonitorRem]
BO_ 2566902519 StatusPhaseVoltageRem: 8 Vector__XXX
 SG_ VoltageU : 0|16@1+ (0.1,0) [0|6553.5] "V" Vector__XXX
 SG_ VoltageV : 16|16@1+ (0.1,0) [0|6553.5] "V" Vector__XXX
 SG_ VoltageW : 32|16@1+ (0.1,0) [0|6553.5] "V" Vector__XXX

BO_ 2634006775 StatusGridMonitorRem: 8 Vector__XXX
 SG_ NetworkVoltage : 0|16@1- (0.1,0) [0|1200] "V" Vector__XXX
 SG_ NetworkFrequency : 16|16@1- (0.01,0) [0|1200] "V" Vector__XXX
 SG_ PhaseSequence : 32|2@1+ (1,0) [0|3] "" Vector__XXX
 SG_ VoltageDetected : 34|2@1+ (1,0) [0|1] "" Vector__XXX
 SG_ NetworkInSpec : 36|2@1+ (1,0) [0|3] "" Vector__XXX

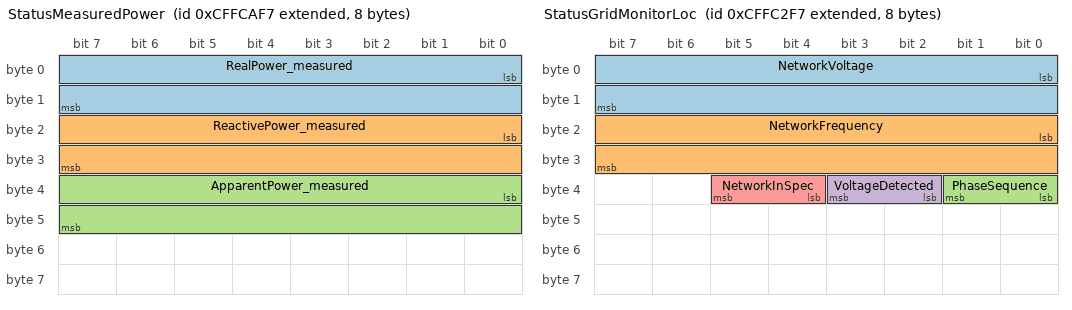
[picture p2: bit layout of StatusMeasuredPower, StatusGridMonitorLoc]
BO_ 2365573879 StatusMeasuredPower: 8 Vector__XXX
 SG_ RealPower_measured : 0|16@1- (0.1,0) [-500|500] "kW" Vector__XXX
 SG_ ReactivePower_measured : 16|16@1- (0.1,0) [-500|500] "kVAr" Vector__XXX
 SG_ ApparentPower_measured : 32|16@1- (0.1,0) [-2000|2000] "kVA" Vector__XXX

BO_ 2566898935 StatusCommandedPower: 8 Vector__XXX
 SG_ RealPower_echo : 0|16@1- (0.1,0) [-500|500] "kW" Vector__XXX
 SG_ ReactivePower_echo : 16|16@1- (0.1,0) [-500|500] "kVAr" Vector__XXX

BO_ 2365572087 StatusBits: 8 Vector__XXX
 SG_ WarningClr_echo : 10|2@1+ (1,0) [0|3] "" Vector__XXX
 SG_ IslandReconnect_echo : 8|2@1+ (1,0) [0|3] "" Vector__XXX
 SG_ ProtBusSequence : 4|4@1+ (1,0) [0|15] "" Vector__XXX
 SG_ FaultClr_echo : 12|2@1+ (1,0) [0|3] "" Vector__XXX
 SG_ Enable_echo : 14|2@1+ (1,0) [0|3] "" Vector__XXX
 SG_ State : 0|4@1+ (1,0) [0|7] "" Vector__XXX
 SG_ PowerCircuitEnabled : 22|2@1+ (1,0) [0|3] "" Vector__XXX
 SG_ PowerAvailDC : 20|2@1+ (1,0) [0|3] "" Vector__XXX
 SG_ Warning : 16|2@1+ (1,0) [0|3] "" Vector__XXX
 SG_ HardwareEnable : 18|2@1+ (1,0) [0|3] "" Vector__XXX
 SG_ K2DCRunPermissive : 24|2@1+ (1,0) [0|3] "" Vector__XXX
 SG_ K1PrechargePermissive : 26|2@1+ (1,0) [0|3] "" Vector__XXX
 SG_ MX2Permissive : 28|2@1+ (1,0) [0|3] "" Vector__XXX
 SG_ MX1Permissive : 30|2@1+ (1,0) [0|3] "" Vector__XXX
 SG_ DI4 : 32|2@1+ (1,0) [0|1] "" Vector__XXX
 SG_ DI3 : 34|2@1+ (1,0) [0|1] "" Vector__XXX
 SG_ DI2 : 36|2@1+ (1,0) [0|1] "" Vector__XXX
 SG_ DI1 : 38|2@1+ (1,0) [0|1] "" Vector__XXX
 SG_ MessageValidPowerCMD : 46|2@1+ (1,0) [0|3] "" Vector__XXX
 SG_ MessageValidModeControl : 44|2@1+ (1,0) [0|3] "" Vector__XXX
 SG_ MessageValidDcControl : 50|2@1+ (1,0) [0|3] "" Vector__XXX
 SG_ MessageValidCurrentCMD : 48|2@1+ (1,0) [0|3] "" Vector__XXX
 SG_ PumpFault : 40|2@1+ (1,0) [0|1] "" Vector__XXX
 SG_ PumpRun : 42|2@1+ (1,0) [0|1] "" Vector__XXX

BO_ 2566893815 StatusTemps: 8 Vector__XXX
 SG_ FanSpeed : 0|8@1+ (1,0) [0|100] "%" Vector__XXX

BO_ 2365571831 StatusGridMonitorLoc: 8 Vector__XXX
 SG_ NetworkVoltage : 0|16@1- (0.1,0) [0|600] "V" Vector__XXX
 SG_ NetworkFrequency : 16|16@1- (0.01,0) [45|65] "Hz" Vector__XXX
 SG_ PhaseSequence : 32|2@1+ (1,0) [0|1] "" Vector__XXX
 SG_ VoltageDetected : 34|2@1+ (1,0) [0|1] "" Vector__XXX
 SG_ NetworkInSpec : 36|2@1+ (1,0) [0|3] "" Vector__XXX

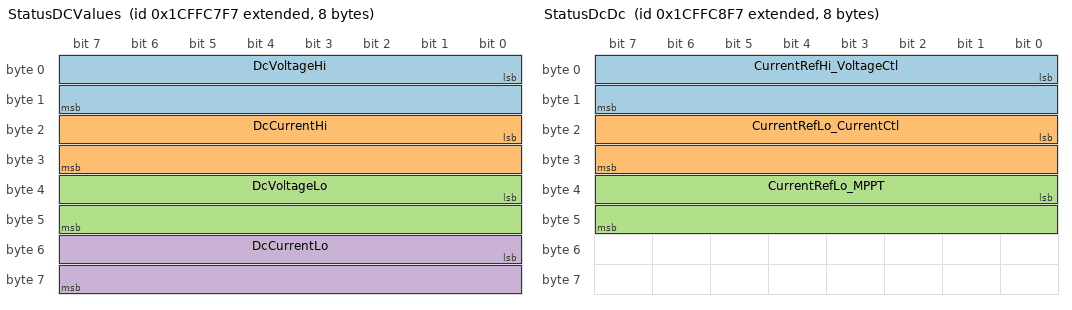
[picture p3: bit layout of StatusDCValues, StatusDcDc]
BO_ 2634008567 StatusDCValues: 8 Vector__XXX
 SG_ DcVoltageHi : 0|16@1- (0.1,0) [0|1500] "V" Vector__XXX
 SG_ DcCurrentHi : 16|16@1- (1,0) [-3000|3000] "A" Vector__XXX
 SG_ DcVoltageLo : 32|16@1- (0.1,0) [0|1500] "V" Vector__XXX
 SG_ DcCurrentLo : 48|16@1- (1,0) [-3000|3000] "A" Vector__XXX

BO_ 2634008823 StatusDcDc: 8 Vector__XXX
 SG_ CurrentRefHi_VoltageCtl : 0|16@1- (0.1,0) [-3000|3000] "A" Vector__XXX
 SG_ CurrentRefLo_CurrentCtl : 16|16@1- (0.1,0) [-3000|3000] "A" Vector__XXX
 SG_ CurrentRefLo_MPPT : 32|16@1- (0.1,0) [-3000|3000] "A" Vector__XXX

BO_ 2634009335 StatusDCVoltage3L: 8 Vector__XXX
 SG_ DcMidpointOffset : 0|16@1- (1,0) [-32768|32767] "V" Vector__XXX
 SG_ DcMidpointRipple : 16|16@1- (1,0) [-32768|32767] "V" Vector__XXX

BO_ 2634009847 StatusCommandedCurrent: 8 Vector__XXX
 SG_ RealCurrent_echo : 0|16@1- (1,0) [-800|800] "A" Vector__XXX
 SG_ ReactiveCurrent_echo : 16|16@1- (1,0) [-800|800] "A" Vector__XXX

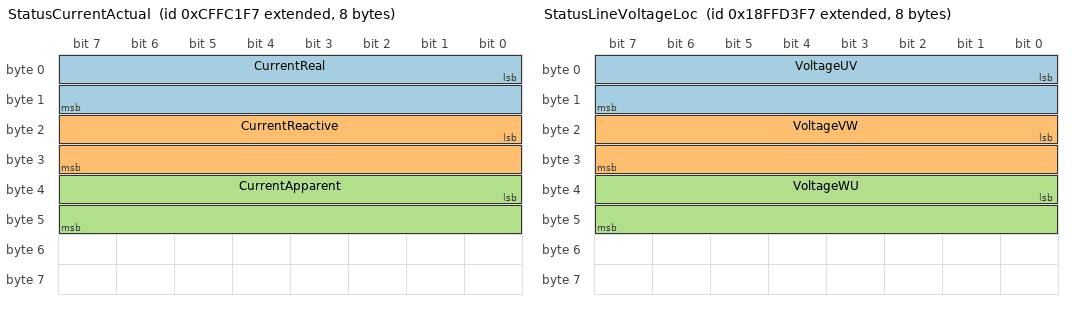
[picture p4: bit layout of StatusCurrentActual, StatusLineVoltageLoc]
BO_ 2365571575 StatusCurrentActual: 8 Vector__XXX
 SG_ CurrentReal : 0|16@1- (1,0) [-1200|1200] "A" Vector__XXX
 SG_ CurrentReactive : 16|16@1- (1,0) [-1200|1200] "A" Vector__XXX
 SG_ CurrentApparent : 32|16@1- (1,0) [-1200|1200] "A" Vector__XXX

BO_ 2566902775 StatusLineVoltageLoc: 8 Vector__XXX
 SG_ VoltageUV : 0|16@1+ (0.1,0) [0|6553.5] "V" Vector__XXX
 SG_ VoltageVW : 16|16@1+ (0.1,0) [0|6553.5] "V" Vector__XXX
 SG_ VoltageWU : 32|16@1+ (0.1,0) [0|6553.5] "V" Vector__XXX

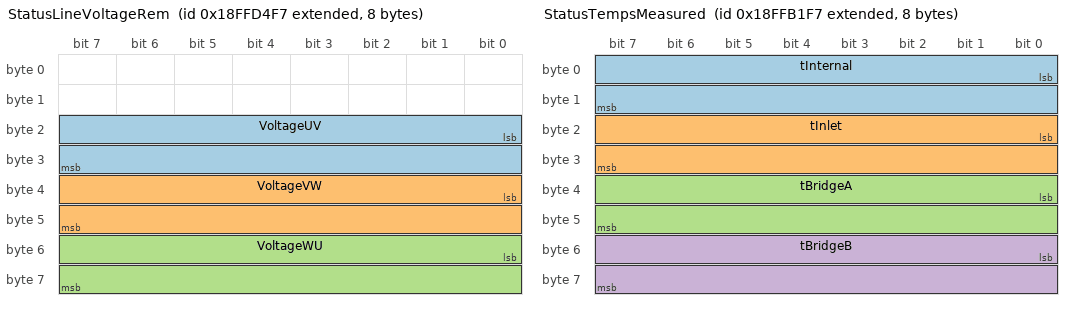
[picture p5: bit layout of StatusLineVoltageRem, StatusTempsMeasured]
BO_ 2566903031 StatusLineVoltageRem: 8 Vector__XXX
 SG_ VoltageUV : 16|16@1+ (0.1,0) [0|6553.5] "V" Vector__XXX
 SG_ VoltageVW : 32|16@1+ (0.1,0) [0|6553.5] "V" Vector__XXX
 SG_ VoltageWU : 48|16@1+ (0.1,0) [0|6553.5] "V" Vector__XXX

BO_ 2566903287 StatusCommandedDcControl: 8 Vector__XXX
 SG_ dcVoltageLimit_echo : 16|16@1+ (1,0) [0|1500] "V" Vector__XXX

BO_ 2566894071 StatusTempsMeasured: 8 Vector__XXX
 SG_ tInternal : 0|16@1- (0.1,0) [-40|100] "C" Vector__XXX
 SG_ tInlet : 16|16@1- (0.1,0) [-40|100] "C" Vector__XXX
 SG_ tBridgeA : 32|16@1- (0.1,0) [-40|200] "C" Vector__XXX
 SG_ tBridgeB : 48|16@1- (0.1,0) [-40|200] "C" Vector__XXX

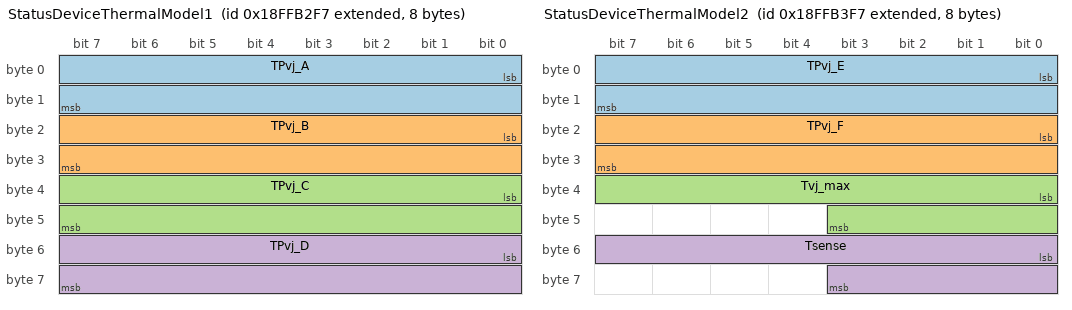
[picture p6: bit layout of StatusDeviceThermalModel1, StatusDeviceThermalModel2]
BO_ 2566894327 StatusDeviceThermalModel1: 8 Vector__XXX
 SG_ TPvj_A : 0|16@1- (0.1,0) [-40|10000] "C|W" Vector__XXX
 SG_ TPvj_B : 16|16@1- (0.1,0) [-40|10000] "C|W" Vector__XXX
 SG_ TPvj_C : 32|16@1- (0.1,0) [-40|10000] "C|W" Vector__XXX
 SG_ TPvj_D : 48|16@1- (0.1,0) [-40|10000] "C|W" Vector__XXX

BO_ 2566894583 StatusDeviceThermalModel2: 8 Vector__XXX
 SG_ TPvj_E : 0|16@1- (0.1,0) [-40|10000] "C|W" Vector__XXX
 SG_ TPvj_F : 16|16@1- (0.1,0) [-40|10000] "C|W" Vector__XXX
 SG_ Tvj_max : 32|12@1- (0.1,0) [-40|200] "C" Vector__XXX
 SG_ Tsense : 48|12@1- (0.1,0) [-40|200] "C" Vector__XXX

BO_ 2566894839 StatusDeviceThermalModel3: 8 Vector__XXX
 SG_ Pl_tot : 0|16@1+ (1,0) [0|65000] "W" Vector__XXX

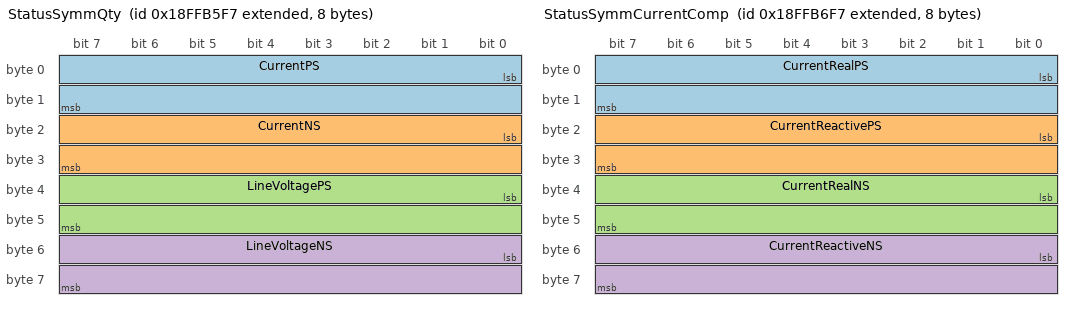
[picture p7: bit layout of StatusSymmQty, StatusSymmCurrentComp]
BO_ 2566895095 StatusSymmQty: 8 Vector__XXX
 SG_ CurrentPS : 0|16@1- (0.1,0) [-3276.8|3276.7] "A" Vector__XXX
 SG_ CurrentNS : 16|16@1- (0.1,0) [-3276.8|3276.7] "A" Vector__XXX
 SG_ LineVoltagePS : 32|16@1+ (0.1,0) [0|6553.5] "V" Vector__XXX
 SG_ LineVoltageNS : 48|16@1+ (0.1,0) [0|6553.5] "V" Vector__XXX

BO_ 2566895351 StatusSymmCurrentComp: 8 Vector__XXX
 SG_ CurrentRealPS : 0|16@1- (0.1,0) [-3276.8|3276.7] "A" Vector__XXX
 SG_ CurrentReactivePS : 16|16@1- (0.1,0) [-3276.8|3276.7] "A" Vector__XXX
 SG_ CurrentRealNS : 32|16@1- (0.1,0) [-3276.8|3276.7] "A" Vector__XXX
 SG_ CurrentReactiveNS : 48|16@1- (0.1,0) [-3276.8|3276.7] "A" Vector__XXX

BO_ 2566895607 StatusCommandedMpptPowerDcdc: 8 Vector__XXX
 SG_ Power : 16|16@1+ (0.1,0) [1000|6553.5] "kW" Vector__XXX

CM_ BO_ 2566902007  "Measured phase currents.";
CM_ BO_ 2566902263  "Measured phase voltages.";
CM_ BO_ 2566902519  "Measured remote phase voltages.";
CM_ BO_ 2634006775  "Status of the remote network grid monitor.";
CM_ BO_ 2365573879  "Returns the actual power.";
CM_ BO_ 2566898935  "Echoes the commanded power (P&Q) as received in CommandPower.";
CM_ BO_ 2365572087  "Bits representing the status of the power module.";
CM_ BO_ 2365571831  "Status of the local network grid monitor.";
CM_ BO_ 2634008567  "Measured DC values.";
CM_ BO_ 2634008823  "battery/solar voltage/current.";
CM_ BO_ 2634009335  "DC midpoint information, relevant to 3L topology power stages.";
CM_ BO_ 2634009847  "Echo of reference currents.";
CM_ BO_ 2365571575  "Actual synchronous currents.";
CM_ BO_ 2566902775  "Measured local line voltages.";
CM_ BO_ 2566903031  "Measured remote line voltages.";
CM_ BO_ 2566903287  "DC control command echos.";
CM_ SG_ 2649702903 Meta1028 "<rw:1:1>  <uuid:3bd185b1-eaeb-4893-afa4-e985c553853f>";
CM_ SG_ 2649702903 ReadParam_status1028 "<rw:1:1>  <uuid:a1904f40-bb8e-47a9-aa08-6dedc474e23a>";
CM_ SG_ 2649702903 TempInvCurrent "Inverter side inductor RMS current limit that is temporarily allowed <rw:1:1>  <InterfaceItem:interfaceItem_e25da5b6_8470_4d4d_9449_9e9b251e90a7:items_getMeta:items_setMeta:>  <uuid:e25da5b6-8470-4d4d-9449-9e9b251e90a7>";
CM_ SG_ 2649702903 Meta1029 "<rw:1:1>  <uuid:3bd185b1-eaeb-4893-afa4-e985c553853f>";
CM_ SG_ 2649702903 ReadParam_status1029 "<rw:1:1>  <uuid:a1904f40-bb8e-47a9-aa08-6dedc474e23a>";
CM_ SG_ 2649702903 Mx1CycleLimit "Cycle count limit.  If exceeded, maintenance warning will occur.  0 disables warning. <rw:1:1>  <InterfaceItem:interfaceItem_bcd97b22_5319_4f8d_bdc1_8f864f419e8f:items_getMeta:items_setMeta:>  <uuid:bcd97b22-5319-4f8d-bdc1-8f864f419e8f>";
CM_ SG_ 2649702903 Meta1030 "<rw:1:1>  <uuid:3bd185b1-eaeb-4893-afa4-e985c553853f>";
CM_ SG_ 2649702903 ReadParam_status1030 "<rw:1:1>  <uuid:a1904f40-bb8e-47a9-aa08-6dedc474e23a>";
CM_ SG_ 2649702903 Mx2CyclesLimit "Cycle count limit.  If exceeded, maintenance warning will occur.  0 disables warning. <rw:1:1>  <InterfaceItem:interfaceItem_4874764a_e8dc_427e_a0b4_260983c6d89e:items_getMeta:items_setMeta:>  <uuid:4874764a-e8dc-427e-a0b4-260983c6d89e>";
CM_ SG_ 2649702903 Meta1031 "<rw:1:1>  <uuid:3bd185b1-eaeb-4893-afa4-e985c553853f>";
CM_ SG_ 2649702903 ReadParam_status1031 "<rw:1:1>  <uuid:a1904f40-bb8e-47a9-aa08-6dedc474e23a>";
CM_ SG_ 2649702903 K1CyclesLimit "Cycle count limit.  If exceeded, maintenance warning will occur.  0 disables warning. <rw:1:1>  <InterfaceItem:interfaceItem_971a0fb6_f539_4656_ad1d_f90caf73c067:items_getMeta:items_setMeta:>  <uuid:971a0fb6-f539-4656-ad1d-f90caf73c067>";
CM_ SG_ 2649702903 Meta1032 "<rw:1:1>  <uuid:3bd185b1-eaeb-4893-afa4-e985c553853f>";
CM_ SG_ 2649702903 ReadParam_status1032 "<rw:1:1>  <uuid:a1904f40-bb8e-47a9-aa08-6dedc474e23a>";
CM_ SG_ 2649702903 K2CyclesLimit "Cycle count limit.  If exceeded, maintenance warning will occur.  0 disables warning. <rw:1:1>  <InterfaceItem:interfaceItem_8ca0297b_d46f_4e64_8963_a2e6a86174da:items_getMeta:items_setMeta:>  <uuid:8ca0297b-d46f-4e64-8963-a2e6a86174da>";
CM_ SG_ 2649702903 Meta1033 "<rw:1:1>  <uuid:3bd185b1-eaeb-4893-afa4-e985c553853f>";
CM_ SG_ 2649702903 ReadParam_status1033 "<rw:1:1>  <uuid:a1904f40-bb8e-47a9-aa08-6dedc474e23a>";
CM_ SG_ 2649702903 MX1CycleCount "Number of MX1 relay close-open cycles <rw:1:1>  <InterfaceItem:interfaceItem_c6dad2e4_6534_422c_a66e_e72e96dcf9ba:items_getMeta:items_setMeta:>  <uuid:c6dad2e4-6534-422c-a66e-e72e96dcf9ba>";
CM_ SG_ 2649702903 Meta1034 "<rw:1:1>  <uuid:3bd185b1-eaeb-4893-afa4-e985c553853f>";
CM_ SG_ 2649702903 ReadParam_status1034 "<rw:1:1>  <uuid:a1904f40-bb8e-47a9-aa08-6dedc474e23a>";
CM_ SG_ 2649702903 MX2CycleCount "Number of MX2 relay close-open cycles <rw:1:1>  <InterfaceItem:interfaceItem_62235ed5_083a_4edd_86eb_3f606816a942:items_getMeta:items_setMeta:>  <uuid:62235ed5-083a-4edd-86eb-3f606816a942>";
CM_ SG_ 2649702903 Meta1035 "<rw:1:1>  <uuid:3bd185b1-eaeb-4893-afa4-e985c553853f>";
CM_ SG_ 2649702903 ReadParam_status1035 "<rw:1:1>  <uuid:a1904f40-bb8e-47a9-aa08-6dedc474e23a>";
CM_ SG_ 2649702903 K1CycleCount "Number of K1 relay close-open cycles <rw:1:1>  <InterfaceItem:interfaceItem_bc755d81_8f33_499d_b80e_b329b84ab4fc:items_getMeta:items_setMeta:>  <uuid:bc755d81-8f33-499d-b80e-b329b84ab4fc>";
CM_ SG_ 2649702903 Meta1036 "<rw:1:1>  <uuid:3bd185b1-eaeb-4893-afa4-e985c553853f>";
CM_ SG_ 2649702903 ReadParam_status1036 "<rw:1:1>  <uuid:a1904f40-bb8e-47a9-aa08-6dedc474e23a>";
CM_ SG_ 2649702903 K2CycleCount "Number of K2 relay close-open cycles <rw:1:1>  <InterfaceItem:interfaceItem_b1c94eb4_9d25_4488_acef_6e7cc6d30eed:items_getMeta:items_setMeta:>  <uuid:b1c94eb4-9d25-4488-acef-6e7cc6d30eed>";
CM_ SG_ 2649702903 Meta1037 "<rw:1:1>  <uuid:3bd185b1-eaeb-4893-afa4-e985c553853f>";
CM_ SG_ 2649702903 ReadParam_status1037 "<rw:1:1>  <uuid:a1904f40-bb8e-47a9-aa08-6dedc474e23a>";
CM_ SG_ 2649702903 MX1DIIndex "Digital Input feedback source for MX1 (e.g. 1 for DI1) <rw:1:1>  <InterfaceItem:interfaceItem_dff56a1d_7041_4a5e_a96b_f5cadfd57b0f:items_getMeta:items_setMeta:>  <uuid:dff56a1d-7041-4a5e-a96b-f5cadfd57b0f>";
CM_ SG_ 2649702903 MX2DIIndex "Digital Input feedback source for MX2 (e.g. 1 for DI1) <rw:1:1>  <InterfaceItem:interfaceItem_7594bb5d_77a4_4330_aadb_8010e31218a4:items_getMeta:items_setMeta:>  <uuid:7594bb5d-77a4-4330-aadb-8010e31218a4>";
CM_ SG_ 2649702903 K1DIIndex "Digital Input feedback source for K1 (e.g. 1 for DI1) <rw:1:1>  <InterfaceItem:interfaceItem_2be4cbd3_e057_4faf_a257_cb8083acff30:items_getMeta:items_setMeta:>  <uuid:2be4cbd3-e057-4faf-a257-cb8083acff30>";
CM_ SG_ 2649702903 K2DIIndex "Digital Input feedback source for K2 (e.g. 1 for DI1) <rw:1:1>  <InterfaceItem:interfaceItem_5a07af66_d0c9_4822_a14f_bc063b637c9b:items_getMeta:items_setMeta:>  <uuid:5a07af66-d0c9-4822-a14f-bc063b637c9b>";
CM_ SG_ 2649702903 Meta1038 "<rw:1:1>  <uuid:3bd185b1-eaeb-4893-afa4-e985c553853f>";
CM_ SG_ 2649702903 ReadParam_status1038 "<rw:1:1>  <uuid:a1904f40-bb8e-47a9-aa08-6dedc474e23a>";
CM_ SG_ 2649702903 DO5Command "Output command for DO5 if CAN is selected as controller <rw:1:1>  <InterfaceItem:interfaceItem_70d295e5_22d2_4946_ac23_7a4c6e4dce5b:items_getMeta:items_setMeta:>  <uuid:70d295e5-22d2-4946-ac23-7a4c6e4dce5b>";
CM_ SG_ 2649702903 DO5Controller "control source for DO5 <rw:1:1>  <InterfaceItem:interfaceItem_5f7b77eb_7a5f_4377_80b2_06d28b05e0dd:items_getMeta:items_setMeta:>  <uuid:5f7b77eb-7a5f-4377-80b2-06d28b05e0dd>";
CM_ SG_ 2649702903 InvertDI6 "Invert DI6 polarity <rw:1:1>  <InterfaceItem:interfaceItem_ab3e210d_71bd_4a4b_acef_84362f62c3e0:items_getMeta:items_setMeta:>  <uuid:ab3e210d-71bd-4a4b-acef-84362f62c3e0>";
CM_ SG_ 2649702903 InvertDI7 "Invert DI7 polarity <rw:1:1>  <InterfaceItem:interfaceItem_ea6573dd_9e30_43de_8519_b730981c7313:items_getMeta:items_setMeta:>  <uuid:ea6573dd-9e30-43de-8519-b730981c7313>";
CM_ SG_ 2649702903 InvertDI8 "Invert DI8 polarity <rw:1:1>  <InterfaceItem:interfaceItem_46ea6012_0c45_4944_8c1b_58415e2c1de6:items_getMeta:items_setMeta:>  <uuid:46ea6012-0c45-4944-8c1b-58415e2c1de6>";
CM_ SG_ 2649702903 InvertDI9 "Invert DI9 polarity <rw:1:1>  <InterfaceItem:interfaceItem_038b2081_5a31_4e68_a3ca_3ce5afc299c2:items_getMeta:items_setMeta:>  <uuid:038b2081-5a31-4e68-a3ca-3ce5afc299c2>";
CM_ SG_ 2649702903 InvertDO5 "Invert DO5 polarity <rw:1:1>  <InterfaceItem:interfaceItem_51a1f9a8_b6f0_43b3_ac0f_6dc9c105cb6d:items_getMeta:items_setMeta:>  <uuid:51a1f9a8-b6f0-43b3-ac0f-6dc9c105cb6d>";
CM_ SG_ 2649702903 Meta1039 "<rw:1:1>  <uuid:3bd185b1-eaeb-4893-afa4-e985c553853f>";
CM_ SG_ 2649702903 ReadParam_status1039 "<rw:1:1>  <uuid:a1904f40-bb8e-47a9-aa08-6dedc474e23a>";
CM_ SG_ 2649702903 ExternalInhibitFault "Indicates of external inhibit occured. <rw:1:0>  <InterfaceItem:interfaceItem_e1ad4324_4466_4583_9cec_22706b920d20:items_getMeta:items_setMeta:>  <uuid:e1ad4324-4466-4583-9cec-22706b920d20>";
CM_ SG_ 2649702903 ExternalInhibitState "State of external inhibit state machine. <rw:1:0>  <InterfaceItem:interfaceItem_f2e310a4_9621_4abe_977a_f90d264ba191:items_getMeta:items_setMeta:>  <uuid:f2e310a4-9621-4abe-977a-f90d264ba191>";
CM_ SG_ 2649702903 Meta1040 "<rw:1:1>  <uuid:3bd185b1-eaeb-4893-afa4-e985c553853f>";
CM_ SG_ 2649702903 ReadParam_status1040 "<rw:1:1>  <uuid:a1904f40-bb8e-47a9-aa08-6dedc474e23a>";
CM_ SG_ 2649702903 enable3 "When external inhibit is enabled, inverter will propigate high [enable] signal from neighboring inverter, and stop modulating when signal is lost [inhibit]. <rw:1:1>  <InterfaceItem:interfaceItem_4e730708_03f0_49ef_8121_bfd81a9a4c83:items_getMeta:items_setMeta:>  <uuid:4e730708-03f0-49ef-8121-bfd81a9a4c83>";
CM_ SG_ 2649702903 forceTime "Time to set enable/inhibit output high when starting. <rw:1:1>  <InterfaceItem:interfaceItem_e494bfbf_47eb_48a1_bdc9_fffce70f2f96:items_getMeta:items_setMeta:>  <uuid:e494bfbf-47eb-48a1-bdc9-fffce70f2f96>";
CM_ SG_ 2649702903 waitTime "Time to wait after a high enable/inhibit signal is received before enabling <rw:1:1>  <InterfaceItem:interfaceItem_846e1805_980a_45a7_bb62_55f6885c1d75:items_getMeta:items_setMeta:>  <uuid:846e1805-980a-45a7-bb62-55f6885c1d75>";
CM_ SG_ 2649702903 Meta1041 "<rw:1:1>  <uuid:3bd185b1-eaeb-4893-afa4-e985c553853f>";
CM_ SG_ 2649702903 ReadParam_status1041 "<rw:1:1>  <uuid:a1904f40-bb8e-47a9-aa08-6dedc474e23a>";
CM_ SG_ 2649702903 inhibitTime "Time to wait after a fault occurs to resync enable/inhibit signal [by forcing enable/inhibit high]. <rw:1:1>  <InterfaceItem:interfaceItem_77932eed_8c50_452b_88fe_60865af948e6:items_getMeta:items_setMeta:>  <uuid:77932eed-8c50-452b-88fe-60865af948e6>";
CM_ SG_ 2649702903 enableAutoSync "When enabled, the inverter with attempt to synchronize periodically based on the auto sync time parameter. <rw:1:1>  <InterfaceItem:interfaceItem_31cdf1d4_0dc6_4223_8d4d_930aa0f27e45:items_getMeta:items_setMeta:>  <uuid:31cdf1d4-0dc6-4223-8d4d-930aa0f27e45>";
CM_ SG_ 2649702903 autoSyncTime "Time between attempted auto sync tries. Only used when auto synchronize is enabled. <rw:1:1>  <InterfaceItem:interfaceItem_f98bf3dd_1343_41d4_8eda_2fe7420a06da:items_getMeta:items_setMeta:>  <uuid:f98bf3dd-1343-41d4-8eda-2fe7420a06da>";
CM_ SG_ 2649702903 Meta1042 "<rw:1:1>  <uuid:3bd185b1-eaeb-4893-afa4-e985c553853f>";
CM_ SG_ 2649702903 ReadParam_status1042 "<rw:1:1>  <uuid:a1904f40-bb8e-47a9-aa08-6dedc474e23a>";
CM_ SG_ 2649702903 FilterTau "Filter time constant for watt-var measured real power <rw:1:1>  <InterfaceItem:interfaceItem_838b54ce_b6e7_434f_a3bf_2696cf796e57:items_getMeta:items_setMeta:>  <uuid:838b54ce-b6e7-434f-a3bf-2696cf796e57>";
CM_ SG_ 2649702903 Meta1043 "<rw:1:1>  <uuid:3bd185b1-eaeb-4893-afa4-e985c553853f>";
CM_ SG_ 2649702903 ReadParam_status1043 "<rw:1:1>  <uuid:a1904f40-bb8e-47a9-aa08-6dedc474e23a>";
CM_ SG_ 2649702903 ActiveInterface "Select which SunSpec interface is discoverable by scanning tools.: sunspec1 (with 100 series models) or sunspec2 (with 700 series models). <rw:1:1>  <InterfaceItem:interfaceItem_f4899259_e256_43c8_b1d6_1eedfb8d50fa:items_getMeta:items_setMeta:>  <uuid:f4899259-e256-43c8-b1d6-1eedfb8d50fa>";
CM_ SG_ 2649702903 Meta1044 "<rw:1:1>  <uuid:3bd185b1-eaeb-4893-afa4-e985c553853f>";
CM_ SG_ 2649702903 ReadParam_status1044 "<rw:1:1>  <uuid:a1904f40-bb8e-47a9-aa08-6dedc474e23a>";
CM_ SG_ 2649702903 MODBUSTimeout "<rw:1:1>  <InterfaceItem:interfaceItem_96518e2d_ba23_4f80_970c_606e0ff9274e:items_getMeta:items_setMeta:>  <uuid:96518e2d-ba23-4f80-970c-606e0ff9274e>";
CM_ SG_ 2649702903 Meta1045 "<rw:1:1>  <uuid:3bd185b1-eaeb-4893-afa4-e985c553853f>";
CM_ SG_ 2649702903 ReadParam_status1045 "<rw:1:1>  <uuid:a1904f40-bb8e-47a9-aa08-6dedc474e23a>";
CM_ SG_ 2649702903 stopIRamp "<rw:1:1>  <InterfaceItem:interfaceItem_e44723bc_194f_40df_83e1_30c0f8b245ec:items_getMeta:items_setMeta:>  <uuid:e44723bc-194f-40df-83e1-30c0f8b245ec>";
CM_ SG_ 2649702903 Meta1046 "<rw:1:1>  <uuid:3bd185b1-eaeb-4893-afa4-e985c553853f>";
CM_ SG_ 2649702903 ReadParam_status1046 "<rw:1:1>  <uuid:a1904f40-bb8e-47a9-aa08-6dedc474e23a>";
CM_ SG_ 2649702903 propGain "<rw:1:1>  <InterfaceItem:interfaceItem_8e7e3389_375b_4b36_a2bf_475173532a63:items_getMeta:items_setMeta:>  <uuid:8e7e3389-375b-4b36-a2bf-475173532a63>";
CM_ SG_ 2649702903 intGain "<rw:1:1>  <InterfaceItem:interfaceItem_575e89f4_8c76_45e9_be8a_d4094711c39f:items_getMeta:items_setMeta:>  <uuid:575e89f4-8c76-45e9-be8a-d4094711c39f>";
CM_ SG_ 2649702903 antiWupGain "<rw:1:1>  <InterfaceItem:interfaceItem_07f24d10_0ec3_4ac1_a4f4_d927e04a0127:items_getMeta:items_setMeta:>  <uuid:07f24d10-0ec3-4ac1-a4f4-d927e04a0127>";
CM_ SG_ 2649702903 Meta1047 "<rw:1:1>  <uuid:3bd185b1-eaeb-4893-afa4-e985c553853f>";
CM_ SG_ 2649702903 ReadParam_status1047 "<rw:1:1>  <uuid:a1904f40-bb8e-47a9-aa08-6dedc474e23a>";
CM_ SG_ 2649702903 vMeasFilt_Tc "<rw:1:1>  <InterfaceItem:interfaceItem_099a7511_ea5e_4d33_8514_d4a828a5d2ce:items_getMeta:items_setMeta:>  <uuid:099a7511-ea5e-4d33-8514-d4a828a5d2ce>";
CM_ SG_ 2649702903 vRefFilt_Tc "<rw:1:1>  <InterfaceItem:interfaceItem_480b9f4e_f844_4030_80fb_f72c857afd29:items_getMeta:items_setMeta:>  <uuid:480b9f4e-f844-4030-80fb-f72c857afd29>";
CM_ SG_ 2649702903 Meta1048 "<rw:1:1>  <uuid:3bd185b1-eaeb-4893-afa4-e985c553853f>";
CM_ SG_ 2649702903 ReadParam_status1048 "<rw:1:1>  <uuid:a1904f40-bb8e-47a9-aa08-6dedc474e23a>";
CM_ SG_ 2649702903 slope0 "<rw:1:1>  <InterfaceItem:interfaceItem_d8b02c5d_49fa_4361_a656_07a1fb0fca17:items_getMeta:items_setMeta:>  <uuid:d8b02c5d-49fa-4361-a656-07a1fb0fca17>";
CM_ SG_ 2649702903 deadband0 "<rw:1:1>  <InterfaceItem:interfaceItem_48a55f0f_62dd_48bf_9135_0582c880d116:items_getMeta:items_setMeta:>  <uuid:48a55f0f-62dd-48bf-9135-0582c880d116>";
CM_ SG_ 2649702903 limit1 "<rw:1:1>  <InterfaceItem:interfaceItem_a23e18d7_3ad5_4f55_bc59_79a7f63df5f9:items_getMeta:items_setMeta:>  <uuid:a23e18d7-3ad5-4f55-bc59-79a7f63df5f9>";
CM_ SG_ 2649702903 Meta1049 "<rw:1:1>  <uuid:3bd185b1-eaeb-4893-afa4-e985c553853f>";
CM_ SG_ 2649702903 ReadParam_status1049 "<rw:1:1>  <uuid:a1904f40-bb8e-47a9-aa08-6dedc474e23a>";
CM_ SG_ 2649702903 fMeasFilt_Tc "<rw:1:1>  <InterfaceItem:interfaceItem_3a621ade_4d46_4674_ab3d_6d61cc60f7a1:items_getMeta:items_setMeta:>  <uuid:3a621ade-4d46-4674-ab3d-6d61cc60f7a1>";
CM_ SG_ 2649702903 fRefFilt_Tc "<rw:1:1>  <InterfaceItem:interfaceItem_79e0bf18_0efb_4e16_8bfa_777d9762b31f:items_getMeta:items_setMeta:>  <uuid:79e0bf18-0efb-4e16-8bfa-777d9762b31f>";
CM_ SG_ 2649702903 Meta1050 "<rw:1:1>  <uuid:3bd185b1-eaeb-4893-afa4-e985c553853f>";
CM_ SG_ 2649702903 ReadParam_status1050 "<rw:1:1>  <uuid:a1904f40-bb8e-47a9-aa08-6dedc474e23a>";
CM_ SG_ 2649702903 slope1 "<rw:1:1>  <InterfaceItem:interfaceItem_02995897_3356_4696_b263_f079c420cd33:items_getMeta:items_setMeta:>  <uuid:02995897-3356-4696-b263-f079c420cd33>";
CM_ SG_ 2649702903 deadband1 "<rw:1:1>  <InterfaceItem:interfaceItem_b9f450e9_331d_4058_96cc_27d58cfd3004:items_getMeta:items_setMeta:>  <uuid:b9f450e9-331d-4058-96cc-27d58cfd3004>";
CM_ SG_ 2649702903 limit2 "<rw:1:1>  <InterfaceItem:interfaceItem_e4f072bb_e4ff_4a0c_97bf_68b0287e88a4:items_getMeta:items_setMeta:>  <uuid:e4f072bb-e4ff-4a0c-97bf-68b0287e88a4>";
CM_ SG_ 2649702903 Meta1051 "<rw:1:1>  <uuid:3bd185b1-eaeb-4893-afa4-e985c553853f>";
CM_ SG_ 2649702903 ReadParam_status1051 "<rw:1:1>  <uuid:a1904f40-bb8e-47a9-aa08-6dedc474e23a>";
CM_ SG_ 2649702903 fMeasDerFilt_Tc "<rw:1:1>  <InterfaceItem:interfaceItem_37b51558_7cda_4a42_926c_2ce8af3bf6be:items_getMeta:items_setMeta:>  <uuid:37b51558-7cda-4a42-926c-2ce8af3bf6be>";
CM_ SG_ 2649702903 Meta1052 "<rw:1:1>  <uuid:3bd185b1-eaeb-4893-afa4-e985c553853f>";
CM_ SG_ 2649702903 ReadParam_status1052 "<rw:1:1>  <uuid:a1904f40-bb8e-47a9-aa08-6dedc474e23a>";
CM_ SG_ 2649702903 gain "<rw:1:1>  <InterfaceItem:interfaceItem_30111a60_fdb2_4cd0_91db_e6f773c6032b:items_getMeta:items_setMeta:>  <uuid:30111a60-fdb2-4cd0-91db-e6f773c6032b>";
CM_ SG_ 2649702903 deadband2 "<rw:1:1>  <InterfaceItem:interfaceItem_a7309eba_1250_4860_8953_f5283ed8c103:items_getMeta:items_setMeta:>  <uuid:a7309eba-1250-4860-8953-f5283ed8c103>";
CM_ SG_ 2649702903 Meta1053 "<rw:1:1>  <uuid:3bd185b1-eaeb-4893-afa4-e985c553853f>";
CM_ SG_ 2649702903 ReadParam_status1053 "<rw:1:1>  <uuid:a1904f40-bb8e-47a9-aa08-6dedc474e23a>";
CM_ SG_ 2649702903 VI_comp_enable "<rw:1:1>  <InterfaceItem:interfaceItem_0cec4d62_6497_4db4_a0c7_af48e60ac4e8:items_getMeta:items_setMeta:>  <uuid:0cec4d62-6497-4db4-a0c7-af48e60ac4e8>";
CM_ SG_ 2649702903 blackStartVRamp "<rw:1:1>  <InterfaceItem:interfaceItem_ea52774c_aefe_44cc_bc2e_1460cbb6a04b:items_getMeta:items_setMeta:>  <uuid:ea52774c-aefe-44cc-bc2e-1460cbb6a04b>";
CM_ SG_ 2649702903 Meta1054 "<rw:1:1>  <uuid:3bd185b1-eaeb-4893-afa4-e985c553853f>";
CM_ SG_ 2649702903 ReadParam_status1054 "<rw:1:1>  <uuid:a1904f40-bb8e-47a9-aa08-6dedc474e23a>";
CM_ SG_ 2649702903 vLimMax "<rw:1:1>  <InterfaceItem:interfaceItem_ae99ab35_eaed_451f_b7f0_392dce697ad9:items_getMeta:items_setMeta:>  <uuid:ae99ab35-eaed-451f-b7f0-392dce697ad9>";
CM_ SG_ 2649702903 vLimMin "<rw:1:1>  <InterfaceItem:interfaceItem_fafa3280_6d5a_4a5b_a641_debcefafc5ed:items_getMeta:items_setMeta:>  <uuid:fafa3280-6d5a-4a5b-a641-debcefafc5ed>";
CM_ SG_ 2649702903 Meta1055 "<rw:1:1>  <uuid:3bd185b1-eaeb-4893-afa4-e985c553853f>";
CM_ SG_ 2649702903 ReadParam_status1055 "<rw:1:1>  <uuid:a1904f40-bb8e-47a9-aa08-6dedc474e23a>";
CM_ SG_ 2649702903 fLimMax "<rw:1:1>  <InterfaceItem:interfaceItem_9307f91d_ce0d_47d7_abbe_2a1989a6010a:items_getMeta:items_setMeta:>  <uuid:9307f91d-ce0d-47d7-abbe-2a1989a6010a>";
CM_ SG_ 2649702903 fLimMin "<rw:1:1>  <InterfaceItem:interfaceItem_1b3a180f_6486_490a_86a6_8de20cd409fe:items_getMeta:items_setMeta:>  <uuid:1b3a180f-6486-490a-86a6-8de20cd409fe>";
CM_ SG_ 2649702903 Meta1056 "<rw:1:1>  <uuid:3bd185b1-eaeb-4893-afa4-e985c553853f>";
CM_ SG_ 2649702903 ReadParam_status1056 "<rw:1:1>  <uuid:a1904f40-bb8e-47a9-aa08-6dedc474e23a>";
CM_ SG_ 2649702903 vDroop "<rw:1:1>  <InterfaceItem:interfaceItem_a93bb3d6_3aa9_41ca_b7a6_0c625eb5df2f:items_getMeta:items_setMeta:>  <uuid:a93bb3d6-3aa9-41ca-b7a6-0c625eb5df2f>";
CM_ SG_ 2649702903 fDroop "<rw:1:1>  <InterfaceItem:interfaceItem_39996620_3809_4e72_9ab6_8f4f7df9f4b7:items_getMeta:items_setMeta:>  <uuid:39996620-3809-4e72-9ab6-8f4f7df9f4b7>";
CM_ SG_ 2649702903 Meta1057 "<rw:1:1>  <uuid:3bd185b1-eaeb-4893-afa4-e985c553853f>";
CM_ SG_ 2649702903 ReadParam_status1057 "<rw:1:1>  <uuid:a1904f40-bb8e-47a9-aa08-6dedc474e23a>";
CM_ SG_ 2649702903 vDeadband "<rw:1:1>  <InterfaceItem:interfaceItem_0c4edc2a_8df2_41f6_848f_96296265dd51:items_getMeta:items_setMeta:>  <uuid:0c4edc2a-8df2-41f6-848f-96296265dd51>";
CM_ SG_ 2649702903 fDeadband "<rw:1:1>  <InterfaceItem:interfaceItem_3bea4b2b_a06e_410b_9102_09fe2a460135:items_getMeta:items_setMeta:>  <uuid:3bea4b2b-a06e-410b-9102-09fe2a460135>";
CM_ SG_ 2649702903 Meta1058 "<rw:1:1>  <uuid:3bd185b1-eaeb-4893-afa4-e985c553853f>";
CM_ SG_ 2649702903 ReadParam_status1058 "<rw:1:1>  <uuid:a1904f40-bb8e-47a9-aa08-6dedc474e23a>";
CM_ SG_ 2649702903 avr_propGain "<rw:1:1>  <InterfaceItem:interfaceItem_cfc12957_9aea_4604_8344_6fe1dd29ef30:items_getMeta:items_setMeta:>  <uuid:cfc12957-9aea-4604-8344-6fe1dd29ef30>";
CM_ SG_ 2649702903 avr_intGain "<rw:1:1>  <InterfaceItem:interfaceItem_5631db4f_475d_4f60_a4c1_31329af9a5b5:items_getMeta:items_setMeta:>  <uuid:5631db4f-475d-4f60-a4c1-31329af9a5b5>";
CM_ SG_ 2649702903 avr_antiWupGain "<rw:1:1>  <InterfaceItem:interfaceItem_2c21cfb2_5545_41ae_a297_2680d9c264e6:items_getMeta:items_setMeta:>  <uuid:2c21cfb2-5545-41ae-a297-2680d9c264e6>";
CM_ SG_ 2649702903 Meta1059 "<rw:1:1>  <uuid:3bd185b1-eaeb-4893-afa4-e985c553853f>";
CM_ SG_ 2649702903 ReadParam_status1059 "<rw:1:1>  <uuid:a1904f40-bb8e-47a9-aa08-6dedc474e23a>";
CM_ SG_ 2649702903 gov_propGain "<rw:1:1>  <InterfaceItem:interfaceItem_d2ea9405_4f18_4c40_8d54_d048bdce27fb:items_getMeta:items_setMeta:>  <uuid:d2ea9405-4f18-4c40-8d54-d048bdce27fb>";
CM_ SG_ 2649702903 gov_intGain "<rw:1:1>  <InterfaceItem:interfaceItem_4db17aa4_5441_4fc6_b35e_096dac997cef:items_getMeta:items_setMeta:>  <uuid:4db17aa4-5441-4fc6-b35e-096dac997cef>";
CM_ SG_ 2649702903 gov_antiWupGain "<rw:1:1>  <InterfaceItem:interfaceItem_65670a70_4805_43f3_8a46_bda57d90fcd7:items_getMeta:items_setMeta:>  <uuid:65670a70-4805-43f3-8a46-bda57d90fcd7>";
CM_ SG_ 2649702903 Meta1060 "<rw:1:1>  <uuid:3bd185b1-eaeb-4893-afa4-e985c553853f>";
CM_ SG_ 2649702903 ReadParam_status1060 "<rw:1:1>  <uuid:a1904f40-bb8e-47a9-aa08-6dedc474e23a>";
CM_ SG_ 2649702903 var_propGain "<rw:1:1>  <InterfaceItem:interfaceItem_39aafd86_c940_4f1c_91ed_61a359a92ee1:items_getMeta:items_setMeta:>  <uuid:39aafd86-c940-4f1c-91ed-61a359a92ee1>";
CM_ SG_ 2649702903 var_intGain "<rw:1:1>  <InterfaceItem:interfaceItem_a807de5b_1ee8_4d32_92fd_c787e8a692e7:items_getMeta:items_setMeta:>  <uuid:a807de5b-1ee8-4d32-92fd-c787e8a692e7>";
CM_ SG_ 2649702903 var_antiWupGain "<rw:1:1>  <InterfaceItem:interfaceItem_f5fe6bee_0e2e_482a_9d6f_513f8ddad9fc:items_getMeta:items_setMeta:>  <uuid:f5fe6bee-0e2e-482a-9d6f-513f8ddad9fc>";
CM_ SG_ 2649702903 Meta1061 "<rw:1:1>  <uuid:3bd185b1-eaeb-4893-afa4-e985c553853f>";
CM_ SG_ 2649702903 ReadParam_status1061 "<rw:1:1>  <uuid:a1904f40-bb8e-47a9-aa08-6dedc474e23a>";
CM_ SG_ 2649702903 vin_damp "<rw:1:1>  <InterfaceItem:interfaceItem_d4d68d6d_369e_40e0_9316_876eea37003b:items_getMeta:items_setMeta:>  <uuid:d4d68d6d-369e-40e0-9316-876eea37003b>";
CM_ SG_ 2649702903 vin_H_sec "<rw:1:1>  <InterfaceItem:interfaceItem_2a6517d7_86b0_4a39_87e6_1598d20c901f:items_getMeta:items_setMeta:>  <uuid:2a6517d7-86b0-4a39-87e6-1598d20c901f>";
CM_ SG_ 2649702903 vin_antiWupGain "<rw:1:1>  <InterfaceItem:interfaceItem_4eb64c24_5a50_422b_914b_437276cbda3d:items_getMeta:items_setMeta:>  <uuid:4eb64c24-5a50-422b-914b-437276cbda3d>";
CM_ SG_ 2649702903 Meta1062 "<rw:1:1>  <uuid:3bd185b1-eaeb-4893-afa4-e985c553853f>";
CM_ SG_ 2649702903 ReadParam_status1062 "<rw:1:1>  <uuid:a1904f40-bb8e-47a9-aa08-6dedc474e23a>";
CM_ SG_ 2649702903 block_vErr_pct "<rw:1:1>  <InterfaceItem:interfaceItem_ab56331e_4d81_4c64_867d_570163008137:items_getMeta:items_setMeta:>  <uuid:ab56331e-4d81-4c64-867d-570163008137>";
CM_ SG_ 2649702903 block_qErr_pct "<rw:1:1>  <InterfaceItem:interfaceItem_a5612a0f_0253_4a5d_b4f9_e23393ddab1f:items_getMeta:items_setMeta:>  <uuid:a5612a0f-0253-4a5d-b4f9-e23393ddab1f>";
CM_ SG_ 2649702903 block_onDelay_ms "<rw:1:1>  <InterfaceItem:interfaceItem_02133c8f_c12a_4d99_bb93_575720c6d7e7:items_getMeta:items_setMeta:>  <uuid:02133c8f-c12a-4d99-bb93-575720c6d7e7>";
CM_ SG_ 2649702903 Meta1063 "<rw:1:1>  <uuid:3bd185b1-eaeb-4893-afa4-e985c553853f>";
CM_ SG_ 2649702903 ReadParam_status1063 "<rw:1:1>  <uuid:a1904f40-bb8e-47a9-aa08-6dedc474e23a>";
CM_ SG_ 2649702903 ramp_power0 "<rw:1:1>  <InterfaceItem:interfaceItem_580acdb9_6882_4903_bec8_0d0117f53e00:items_getMeta:items_setMeta:>  <uuid:580acdb9-6882-4903-bec8-0d0117f53e00>";
CM_ SG_ 2649702903 ramp_time0 "<rw:1:1>  <InterfaceItem:interfaceItem_c5f3771f_1e5a_4e72_ab42_71ceb6552d39:items_getMeta:items_setMeta:>  <uuid:c5f3771f-1e5a-4e72-ab42-71ceb6552d39>";
CM_ SG_ 2649702903 Meta1064 "<rw:1:1>  <uuid:3bd185b1-eaeb-4893-afa4-e985c553853f>";
CM_ SG_ 2649702903 ReadParam_status1064 "<rw:1:1>  <uuid:a1904f40-bb8e-47a9-aa08-6dedc474e23a>";
CM_ SG_ 2649702903 ramp_power1 "<rw:1:1>  <InterfaceItem:interfaceItem_1c6328d5_632c_40af_b19c_dc4ccd943ebc:items_getMeta:items_setMeta:>  <uuid:1c6328d5-632c-40af-b19c-dc4ccd943ebc>";
CM_ SG_ 2649702903 ramp_time1 "<rw:1:1>  <InterfaceItem:interfaceItem_505fe19e_b593_40ab_8c1e_052dc787d175:items_getMeta:items_setMeta:>  <uuid:505fe19e-b593-40ab-8c1e-052dc787d175>";
CM_ SG_ 2649702903 Meta1065 "<rw:1:1>  <uuid:3bd185b1-eaeb-4893-afa4-e985c553853f>";
CM_ SG_ 2649702903 ReadParam_status1065 "<rw:1:1>  <uuid:a1904f40-bb8e-47a9-aa08-6dedc474e23a>";
CM_ SG_ 2649702903 vFilterTrPa "<rw:1:1>  <InterfaceItem:interfaceItem_20f766f0_d6eb_4053_90f3_742b8a385291:items_getMeta:items_setMeta:>  <uuid:20f766f0-d6eb-4053-90f3-742b8a385291>";
CM_ SG_ 2649702903 Meta1066 "<rw:1:1>  <uuid:3bd185b1-eaeb-4893-afa4-e985c553853f>";
CM_ SG_ 2649702903 ReadParam_status1066 "<rw:1:1>  <uuid:a1904f40-bb8e-47a9-aa08-6dedc474e23a>";
CM_ SG_ 2649702903 NumActivePoints24 "Index of active curve. 0=no active curve. <rw:1:1>  <InterfaceItem:interfaceItem_afb66fea_83bc_469c_9ae1_a644078469b2:table_items_getMeta:table_items_setMeta:>  <uuid:afb66fea-83bc-469c-9ae1-a644078469b2>";
CM_ SG_ 2649702903 Meta1067 "<rw:1:1>  <uuid:3bd185b1-eaeb-4893-afa4-e985c553853f>";
CM_ SG_ 2649702903 ReadParam_status1067 "<rw:1:1>  <uuid:a1904f40-bb8e-47a9-aa08-6dedc474e23a>";
CM_ SG_ 2649702903 _0148 "<rw:1:1>  <InterfaceItem:interfaceItem_cd9f6640_74fd_4876_9517_90324bc9a793:table_items_getMeta:table_items_setMeta:>  <uuid:cd9f6640-74fd-4876-9517-90324bc9a793>";
CM_ SG_ 2649702903 _0248 "<rw:1:1>  <InterfaceItem:interfaceItem_7f3b240c_b1a1_4a13_926c_ded73f0b4fc4:table_items_getMeta:table_items_setMeta:>  <uuid:7f3b240c-b1a1-4a13-926c-ded73f0b4fc4>";
CM_ SG_ 2649702903 _0348 "<rw:1:1>  <InterfaceItem:interfaceItem_6719c728_1fc0_4847_a4a9_337b2e2d0931:table_items_getMeta:table_items_setMeta:>  <uuid:6719c728-1fc0-4847-a4a9-337b2e2d0931>";
CM_ SG_ 2649702903 Meta1068 "<rw:1:1>  <uuid:3bd185b1-eaeb-4893-afa4-e985c553853f>";
CM_ SG_ 2649702903 ReadParam_status1068 "<rw:1:1>  <uuid:a1904f40-bb8e-47a9-aa08-6dedc474e23a>";
CM_ SG_ 2649702903 _0448 "<rw:1:1>  <InterfaceItem:interfaceItem_1df36809_81a7_44bd_b4b4_e2004d687296:table_items_getMeta:table_items_setMeta:>  <uuid:1df36809-81a7-44bd-b4b4-e2004d687296>";
CM_ SG_ 2649702903 _0548 "<rw:1:1>  <InterfaceItem:interfaceItem_26df02f6_e603_4cfe_aee7_62f0785037d1:table_items_getMeta:table_items_setMeta:>  <uuid:26df02f6-e603-4cfe-aee7-62f0785037d1>";
CM_ SG_ 2649702903 _0648 "<rw:1:1>  <InterfaceItem:interfaceItem_13411b7f_1a2f_44d6_95d2_7f577beac0d8:table_items_getMeta:table_items_setMeta:>  <uuid:13411b7f-1a2f-44d6-95d2-7f577beac0d8>";
CM_ SG_ 2649702903 Meta1069 "<rw:1:1>  <uuid:3bd185b1-eaeb-4893-afa4-e985c553853f>";
CM_ SG_ 2649702903 ReadParam_status1069 "<rw:1:1>  <uuid:a1904f40-bb8e-47a9-aa08-6dedc474e23a>";
CM_ SG_ 2649702903 _0748 "<rw:1:1>  <InterfaceItem:interfaceItem_653df591_d64f_47ff_b606_cf46321940c7:table_items_getMeta:table_items_setMeta:>  <uuid:653df591-d64f-47ff-b606-cf46321940c7>";
CM_ SG_ 2649702903 _0848 "<rw:1:1>  <InterfaceItem:interfaceItem_714ec706_13cc_4920_a105_7c23518e2b77:table_items_getMeta:table_items_setMeta:>  <uuid:714ec706-13cc-4920-a105-7c23518e2b77>";
CM_ SG_ 2649702903 _0948 "<rw:1:1>  <InterfaceItem:interfaceItem_db053dff_d126_4cfe_86ce_a9090ea2679b:table_items_getMeta:table_items_setMeta:>  <uuid:db053dff-d126-4cfe-86ce-a9090ea2679b>";
CM_ SG_ 2649702903 Meta1070 "<rw:1:1>  <uuid:3bd185b1-eaeb-4893-afa4-e985c553853f>";
CM_ SG_ 2649702903 ReadParam_status1070 "<rw:1:1>  <uuid:a1904f40-bb8e-47a9-aa08-6dedc474e23a>";
CM_ SG_ 2649702903 _1048 "<rw:1:1>  <InterfaceItem:interfaceItem_b2318123_78be_439b_a691_baa57d0a9b52:table_items_getMeta:table_items_setMeta:>  <uuid:b2318123-78be-439b-a691-baa57d0a9b52>";
CM_ SG_ 2649702903 _1148 "<rw:1:1>  <InterfaceItem:interfaceItem_1c898ada_2aaf_4a28_a3e4_16acb83d6483:table_items_getMeta:table_items_setMeta:>  <uuid:1c898ada-2aaf-4a28-a3e4-16acb83d6483>";
CM_ SG_ 2649702903 _1248 "<rw:1:1>  <InterfaceItem:interfaceItem_2c95ed44_b3a1_4538_b417_8007ed1cef62:table_items_getMeta:table_items_setMeta:>  <uuid:2c95ed44-b3a1-4538-b417-8007ed1cef62>";
CM_ SG_ 2649702903 Meta1071 "<rw:1:1>  <uuid:3bd185b1-eaeb-4893-afa4-e985c553853f>";
CM_ SG_ 2649702903 ReadParam_status1071 "<rw:1:1>  <uuid:a1904f40-bb8e-47a9-aa08-6dedc474e23a>";
CM_ SG_ 2649702903 _1348 "<rw:1:1>  <InterfaceItem:interfaceItem_3822c685_d34f_4a28_85fc_060a89523aa0:table_items_getMeta:table_items_setMeta:>  <uuid:3822c685-d34f-4a28-85fc-060a89523aa0>";
CM_ SG_ 2649702903 _1448 "<rw:1:1>  <InterfaceItem:interfaceItem_53585c15_7460_4f40_9aa7_c59784b71d7a:table_items_getMeta:table_items_setMeta:>  <uuid:53585c15-7460-4f40-9aa7-c59784b71d7a>";
CM_ SG_ 2649702903 _1548 "<rw:1:1>  <InterfaceItem:interfaceItem_094847c7_24c2_421f_975b_27c7f86c9794:table_items_getMeta:table_items_setMeta:>  <uuid:094847c7-24c2-421f-975b-27c7f86c9794>";
CM_ SG_ 2649702903 Meta1072 "<rw:1:1>  <uuid:3bd185b1-eaeb-4893-afa4-e985c553853f>";
CM_ SG_ 2649702903 ReadParam_status1072 "<rw:1:1>  <uuid:a1904f40-bb8e-47a9-aa08-6dedc474e23a>";
CM_ SG_ 2649702903 _1648 "<rw:1:1>  <InterfaceItem:interfaceItem_b301e7e5_eb76_4fd3_8cba_e81015bc81ad:table_items_getMeta:table_items_setMeta:>  <uuid:b301e7e5-eb76-4fd3-8cba-e81015bc81ad>";
CM_ SG_ 2649702903 _1748 "<rw:1:1>  <InterfaceItem:interfaceItem_29ed2869_1e42_40f7_aadb_f4bd1cb10e9b:table_items_getMeta:table_items_setMeta:>  <uuid:29ed2869-1e42-40f7-aadb-f4bd1cb10e9b>";
CM_ SG_ 2649702903 _1848 "<rw:1:1>  <InterfaceItem:interfaceItem_beb5cd30_1128_460d_a4c3_b74eb43c2a5d:table_items_getMeta:table_items_setMeta:>  <uuid:beb5cd30-1128-460d-a4c3-b74eb43c2a5d>";
CM_ SG_ 2649702903 Meta1073 "<rw:1:1>  <uuid:3bd185b1-eaeb-4893-afa4-e985c553853f>";
CM_ SG_ 2649702903 ReadParam_status1073 "<rw:1:1>  <uuid:a1904f40-bb8e-47a9-aa08-6dedc474e23a>";
CM_ SG_ 2649702903 _1948 "<rw:1:1>  <InterfaceItem:interfaceItem_fd2460b4_6e10_43b8_9477_04045c97bea8:table_items_getMeta:table_items_setMeta:>  <uuid:fd2460b4-6e10-43b8-9477-04045c97bea8>";
CM_ SG_ 2649702903 _2048 "<rw:1:1>  <InterfaceItem:interfaceItem_1721eb45_839e_4e70_9e2e_fb965eb39a43:table_items_getMeta:table_items_setMeta:>  <uuid:1721eb45-839e-4e70-9e2e-fb965eb39a43>";
CM_ SG_ 2649702903 Meta1074 "<rw:1:1>  <uuid:3bd185b1-eaeb-4893-afa4-e985c553853f>";
CM_ SG_ 2649702903 ReadParam_status1074 "<rw:1:1>  <uuid:a1904f40-bb8e-47a9-aa08-6dedc474e23a>";
CM_ SG_ 2649702903 _0149 "<rw:1:1>  <InterfaceItem:interfaceItem_96274405_2ed8_4d10_91dd_a9563f36233c:table_items_getMeta:table_items_setMeta:>  <uuid:96274405-2ed8-4d10-91dd-a9563f36233c>";
CM_ SG_ 2649702903 _0249 "<rw:1:1>  <InterfaceItem:interfaceItem_257bb576_bb20_4fe3_8c96_040996d01f1d:table_items_getMeta:table_items_setMeta:>  <uuid:257bb576-bb20-4fe3-8c96-040996d01f1d>";
CM_ SG_ 2649702903 _0349 "<rw:1:1>  <InterfaceItem:interfaceItem_632e8464_1b93_48f1_99a8_598e3caa58b5:table_items_getMeta:table_items_setMeta:>  <uuid:632e8464-1b93-48f1-99a8-598e3caa58b5>";
CM_ SG_ 2649702903 Meta1075 "<rw:1:1>  <uuid:3bd185b1-eaeb-4893-afa4-e985c553853f>";
CM_ SG_ 2649702903 ReadParam_status1075 "<rw:1:1>  <uuid:a1904f40-bb8e-47a9-aa08-6dedc474e23a>";
CM_ SG_ 2649702903 _0449 "<rw:1:1>  <InterfaceItem:interfaceItem_941cdf74_42cb_4e6b_8748_bd3bb394b014:table_items_getMeta:table_items_setMeta:>  <uuid:941cdf74-42cb-4e6b-8748-bd3bb394b014>";
CM_ SG_ 2649702903 _0549 "<rw:1:1>  <InterfaceItem:interfaceItem_f56969ed_dbb8_4e72_8130_abb5e0ae6f4b:table_items_getMeta:table_items_setMeta:>  <uuid:f56969ed-dbb8-4e72-8130-abb5e0ae6f4b>";
CM_ SG_ 2649702903 _0649 "<rw:1:1>  <InterfaceItem:interfaceItem_f8023281_3371_4462_a259_c85c89e3a296:table_items_getMeta:table_items_setMeta:>  <uuid:f8023281-3371-4462-a259-c85c89e3a296>";
CM_ SG_ 2649702903 Meta1076 "<rw:1:1>  <uuid:3bd185b1-eaeb-4893-afa4-e985c553853f>";
CM_ SG_ 2649702903 ReadParam_status1076 "<rw:1:1>  <uuid:a1904f40-bb8e-47a9-aa08-6dedc474e23a>";
CM_ SG_ 2649702903 _0749 "<rw:1:1>  <InterfaceItem:interfaceItem_c0521116_91b9_4a07_b3e2_98955d8b1955:table_items_getMeta:table_items_setMeta:>  <uuid:c0521116-91b9-4a07-b3e2-98955d8b1955>";
CM_ SG_ 2649702903 _0849 "<rw:1:1>  <InterfaceItem:interfaceItem_41725d35_3a8f_4a20_9985_b1dc70cc35a7:table_items_getMeta:table_items_setMeta:>  <uuid:41725d35-3a8f-4a20-9985-b1dc70cc35a7>";
CM_ SG_ 2649702903 _0949 "<rw:1:1>  <InterfaceItem:interfaceItem_8286c390_0aa6_483d_b93f_cfab20a12b8f:table_items_getMeta:table_items_setMeta:>  <uuid:8286c390-0aa6-483d-b93f-cfab20a12b8f>";
CM_ SG_ 2649702903 Meta1077 "<rw:1:1>  <uuid:3bd185b1-eaeb-4893-afa4-e985c553853f>";
CM_ SG_ 2649702903 ReadParam_status1077 "<rw:1:1>  <uuid:a1904f40-bb8e-47a9-aa08-6dedc474e23a>";
CM_ SG_ 2649702903 _1049 "<rw:1:1>  <InterfaceItem:interfaceItem_d637ebe4_b907_4617_bf09_9c78c7b3cf88:table_items_getMeta:table_items_setMeta:>  <uuid:d637ebe4-b907-4617-bf09-9c78c7b3cf88>";
CM_ SG_ 2649702903 _1149 "<rw:1:1>  <InterfaceItem:interfaceItem_fd5fb453_ee2a_4d45_834e_0958e2407e58:table_items_getMeta:table_items_setMeta:>  <uuid:fd5fb453-ee2a-4d45-834e-0958e2407e58>";
CM_ SG_ 2649702903 _1249 "<rw:1:1>  <InterfaceItem:interfaceItem_d3b1c7c1_a6fb_4276_9617_1086c23e6494:table_items_getMeta:table_items_setMeta:>  <uuid:d3b1c7c1-a6fb-4276-9617-1086c23e6494>";
CM_ SG_ 2649702903 Meta1078 "<rw:1:1>  <uuid:3bd185b1-eaeb-4893-afa4-e985c553853f>";
CM_ SG_ 2649702903 ReadParam_status1078 "<rw:1:1>  <uuid:a1904f40-bb8e-47a9-aa08-6dedc474e23a>";
CM_ SG_ 2649702903 _1349 "<rw:1:1>  <InterfaceItem:interfaceItem_f8e2c0fe_0523_4c6a_bf2c_c245a4f9b065:table_items_getMeta:table_items_setMeta:>  <uuid:f8e2c0fe-0523-4c6a-bf2c-c245a4f9b065>";
CM_ SG_ 2649702903 _1449 "<rw:1:1>  <InterfaceItem:interfaceItem_0b6a5921_e5af_4a28_b907_525d4ff5be96:table_items_getMeta:table_items_setMeta:>  <uuid:0b6a5921-e5af-4a28-b907-525d4ff5be96>";
CM_ SG_ 2649702903 _1549 "<rw:1:1>  <InterfaceItem:interfaceItem_e0205643_38b5_489f_bdc9_751a58a59ea7:table_items_getMeta:table_items_setMeta:>  <uuid:e0205643-38b5-489f-bdc9-751a58a59ea7>";
CM_ SG_ 2649702903 Meta1079 "<rw:1:1>  <uuid:3bd185b1-eaeb-4893-afa4-e985c553853f>";
CM_ SG_ 2649702903 ReadParam_status1079 "<rw:1:1>  <uuid:a1904f40-bb8e-47a9-aa08-6dedc474e23a>";
CM_ SG_ 2649702903 _1649 "<rw:1:1>  <InterfaceItem:interfaceItem_4b39c164_e441_4107_9be2_99191aef75e3:table_items_getMeta:table_items_setMeta:>  <uuid:4b39c164-e441-4107-9be2-99191aef75e3>";
CM_ SG_ 2649702903 _1749 "<rw:1:1>  <InterfaceItem:interfaceItem_2f01b66d_b068_4c55_8a4d_04b19021be50:table_items_getMeta:table_items_setMeta:>  <uuid:2f01b66d-b068-4c55-8a4d-04b19021be50>";
CM_ SG_ 2649702903 _1849 "<rw:1:1>  <InterfaceItem:interfaceItem_219c44ee_461d_4dd4_ba5d_0d89a0260a96:table_items_getMeta:table_items_setMeta:>  <uuid:219c44ee-461d-4dd4-ba5d-0d89a0260a96>";
CM_ SG_ 2649702903 Meta1080 "<rw:1:1>  <uuid:3bd185b1-eaeb-4893-afa4-e985c553853f>";
CM_ SG_ 2649702903 ReadParam_status1080 "<rw:1:1>  <uuid:a1904f40-bb8e-47a9-aa08-6dedc474e23a>";
CM_ SG_ 2649702903 _1949 "<rw:1:1>  <InterfaceItem:interfaceItem_ceedf8e7_7319_4344_930e_29bb3bc38f57:table_items_getMeta:table_items_setMeta:>  <uuid:ceedf8e7-7319-4344-930e-29bb3bc38f57>";
CM_ SG_ 2649702903 _2049 "<rw:1:1>  <InterfaceItem:interfaceItem_7a407979_c133_4fbb_ba80_0bd01ba459e8:table_items_getMeta:table_items_setMeta:>  <uuid:7a407979-c133-4fbb-ba80-0bd01ba459e8>";
CM_ SG_ 2649702903 Meta1081 "<rw:1:1>  <uuid:3bd185b1-eaeb-4893-afa4-e985c553853f>";
CM_ SG_ 2649702903 ReadParam_status1081 "<rw:1:1>  <uuid:a1904f40-bb8e-47a9-aa08-6dedc474e23a>";
CM_ SG_ 2649702903 RampRateDecrement8 "<rw:1:1>  <InterfaceItem:interfaceItem_cfaaa0bc_ddaa_4192_bfc0_b0c91cbc0c63:table_items_getMeta:table_items_setMeta:>  <uuid:cfaaa0bc-ddaa-4192-bfc0-b0c91cbc0c63>";
CM_ SG_ 2649702903 RampRateIncrement8 "<rw:1:1>  <InterfaceItem:interfaceItem_9da437a4_f75d_4d18_9e62_f7d159eaef5e:table_items_getMeta:table_items_setMeta:>  <uuid:9da437a4-f75d-4d18-9e62-f7d159eaef5e>";
CM_ SG_ 2649702903 Meta1082 "<rw:1:1>  <uuid:3bd185b1-eaeb-4893-afa4-e985c553853f>";
CM_ SG_ 2649702903 ReadParam_status1082 "<rw:1:1>  <uuid:a1904f40-bb8e-47a9-aa08-6dedc474e23a>";
CM_ SG_ 2649702903 NumActivePoints25 "Index of active curve. 0=no active curve. <rw:1:1>  <InterfaceItem:interfaceItem_eaae9695_ae5f_4652_add1_13a3d9465af1:table_items_getMeta:table_items_setMeta:>  <uuid:eaae9695-ae5f-4652-add1-13a3d9465af1>";
CM_ SG_ 2649702903 Meta1083 "<rw:1:1>  <uuid:3bd185b1-eaeb-4893-afa4-e985c553853f>";
CM_ SG_ 2649702903 ReadParam_status1083 "<rw:1:1>  <uuid:a1904f40-bb8e-47a9-aa08-6dedc474e23a>";
CM_ SG_ 2649702903 _0150 "<rw:1:1>  <InterfaceItem:interfaceItem_3bfa154c_b168_4d9f_abf6_a28b8e0d62f9:table_items_getMeta:table_items_setMeta:>  <uuid:3bfa154c-b168-4d9f-abf6-a28b8e0d62f9>";
CM_ SG_ 2649702903 _0250 "<rw:1:1>  <InterfaceItem:interfaceItem_d156bec4_a2d1_40db_8760_d7006d051bc4:table_items_getMeta:table_items_setMeta:>  <uuid:d156bec4-a2d1-40db-8760-d7006d051bc4>";
CM_ SG_ 2649702903 _0350 "<rw:1:1>  <InterfaceItem:interfaceItem_aea577a5_ff70_4d08_b964_0371bb253eb9:table_items_getMeta:table_items_setMeta:>  <uuid:aea577a5-ff70-4d08-b964-0371bb253eb9>";
CM_ SG_ 2649702903 Meta1084 "<rw:1:1>  <uuid:3bd185b1-eaeb-4893-afa4-e985c553853f>";
CM_ SG_ 2649702903 ReadParam_status1084 "<rw:1:1>  <uuid:a1904f40-bb8e-47a9-aa08-6dedc474e23a>";
CM_ SG_ 2649702903 _0450 "<rw:1:1>  <InterfaceItem:interfaceItem_0d3a476a_ff51_4ad9_9a79_ed2d2eb806fb:table_items_getMeta:table_items_setMeta:>  <uuid:0d3a476a-ff51-4ad9-9a79-ed2d2eb806fb>";
CM_ SG_ 2649702903 _0550 "<rw:1:1>  <InterfaceItem:interfaceItem_40ed00e6_81f8_42d8_928a_666685746676:table_items_getMeta:table_items_setMeta:>  <uuid:40ed00e6-81f8-42d8-928a-666685746676>";
CM_ SG_ 2649702903 _0650 "<rw:1:1>  <InterfaceItem:interfaceItem_ba8ade1b_701a_4e00_9f3d_22cecb9ef8cf:table_items_getMeta:table_items_setMeta:>  <uuid:ba8ade1b-701a-4e00-9f3d-22cecb9ef8cf>";
CM_ SG_ 2649702903 Meta1085 "<rw:1:1>  <uuid:3bd185b1-eaeb-4893-afa4-e985c553853f>";
CM_ SG_ 2649702903 ReadParam_status1085 "<rw:1:1>  <uuid:a1904f40-bb8e-47a9-aa08-6dedc474e23a>";
CM_ SG_ 2649702903 _0750 "<rw:1:1>  <InterfaceItem:interfaceItem_5c2dd6f1_1aca_4799_815e_a1aa4bd74d64:table_items_getMeta:table_items_setMeta:>  <uuid:5c2dd6f1-1aca-4799-815e-a1aa4bd74d64>";
CM_ SG_ 2649702903 _0850 "<rw:1:1>  <InterfaceItem:interfaceItem_042a84f7_5867_46a1_8eb3_f202ad7a7837:table_items_getMeta:table_items_setMeta:>  <uuid:042a84f7-5867-46a1-8eb3-f202ad7a7837>";
CM_ SG_ 2649702903 _0950 "<rw:1:1>  <InterfaceItem:interfaceItem_e5523d70_1238_4393_9348_888b3a92c2a0:table_items_getMeta:table_items_setMeta:>  <uuid:e5523d70-1238-4393-9348-888b3a92c2a0>";
CM_ SG_ 2649702903 Meta1086 "<rw:1:1>  <uuid:3bd185b1-eaeb-4893-afa4-e985c553853f>";
CM_ SG_ 2649702903 ReadParam_status1086 "<rw:1:1>  <uuid:a1904f40-bb8e-47a9-aa08-6dedc474e23a>";
CM_ SG_ 2649702903 _1050 "<rw:1:1>  <InterfaceItem:interfaceItem_3bc969dc_68eb_4ffd_a01a_fa09063f58b5:table_items_getMeta:table_items_setMeta:>  <uuid:3bc969dc-68eb-4ffd-a01a-fa09063f58b5>";
CM_ SG_ 2649702903 _1150 "<rw:1:1>  <InterfaceItem:interfaceItem_65f969db_d46c_4466_b635_d68495571717:table_items_getMeta:table_items_setMeta:>  <uuid:65f969db-d46c-4466-b635-d68495571717>";
CM_ SG_ 2649702903 _1250 "<rw:1:1>  <InterfaceItem:interfaceItem_e3bbc1b3_18b1_4139_ba6a_9f108da0604f:table_items_getMeta:table_items_setMeta:>  <uuid:e3bbc1b3-18b1-4139-ba6a-9f108da0604f>";
CM_ SG_ 2649702903 Meta1087 "<rw:1:1>  <uuid:3bd185b1-eaeb-4893-afa4-e985c553853f>";
CM_ SG_ 2649702903 ReadParam_status1087 "<rw:1:1>  <uuid:a1904f40-bb8e-47a9-aa08-6dedc474e23a>";
CM_ SG_ 2649702903 _1350 "<rw:1:1>  <InterfaceItem:interfaceItem_5d88681f_51a8_4d10_847d_b1d283ac89b4:table_items_getMeta:table_items_setMeta:>  <uuid:5d88681f-51a8-4d10-847d-b1d283ac89b4>";
CM_ SG_ 2649702903 _1450 "<rw:1:1>  <InterfaceItem:interfaceItem_2e3573c9_9ba7_4f05_ad72_0dfa6b9aa27d:table_items_getMeta:table_items_setMeta:>  <uuid:2e3573c9-9ba7-4f05-ad72-0dfa6b9aa27d>";
CM_ SG_ 2649702903 _1550 "<rw:1:1>  <InterfaceItem:interfaceItem_6dfc9332_4e52_49cc_856f_0e2274202e63:table_items_getMeta:table_items_setMeta:>  <uuid:6dfc9332-4e52-49cc-856f-0e2274202e63>";
CM_ SG_ 2649702903 Meta1088 "<rw:1:1>  <uuid:3bd185b1-eaeb-4893-afa4-e985c553853f>";
CM_ SG_ 2649702903 ReadParam_status1088 "<rw:1:1>  <uuid:a1904f40-bb8e-47a9-aa08-6dedc474e23a>";
CM_ SG_ 2649702903 _1650 "<rw:1:1>  <InterfaceItem:interfaceItem_8b997357_626e_46a4_baa1_af252e97f90d:table_items_getMeta:table_items_setMeta:>  <uuid:8b997357-626e-46a4-baa1-af252e97f90d>";
CM_ SG_ 2649702903 _1750 "<rw:1:1>  <InterfaceItem:interfaceItem_a19b0da1_1804_4c94_bd5c_95045805698b:table_items_getMeta:table_items_setMeta:>  <uuid:a19b0da1-1804-4c94-bd5c-95045805698b>";
CM_ SG_ 2649702903 _1850 "<rw:1:1>  <InterfaceItem:interfaceItem_b852cc8c_1a06_4efb_9148_425fa1262e22:table_items_getMeta:table_items_setMeta:>  <uuid:b852cc8c-1a06-4efb-9148-425fa1262e22>";
CM_ SG_ 2649702903 Meta1089 "<rw:1:1>  <uuid:3bd185b1-eaeb-4893-afa4-e985c553853f>";
CM_ SG_ 2649702903 ReadParam_status1089 "<rw:1:1>  <uuid:a1904f40-bb8e-47a9-aa08-6dedc474e23a>";
CM_ SG_ 2649702903 _1950 "<rw:1:1>  <InterfaceItem:interfaceItem_fa932d4a_a52d_4fda_bab3_31710572585c:table_items_getMeta:table_items_setMeta:>  <uuid:fa932d4a-a52d-4fda-bab3-31710572585c>";
CM_ SG_ 2649702903 _2050 "<rw:1:1>  <InterfaceItem:interfaceItem_ca75d339_51fa_4d7f_992d_59b1e70bb2b9:table_items_getMeta:table_items_setMeta:>  <uuid:ca75d339-51fa-4d7f-992d-59b1e70bb2b9>";
CM_ SG_ 2649702903 Meta1090 "<rw:1:1>  <uuid:3bd185b1-eaeb-4893-afa4-e985c553853f>";
CM_ SG_ 2649702903 ReadParam_status1090 "<rw:1:1>  <uuid:a1904f40-bb8e-47a9-aa08-6dedc474e23a>";
CM_ SG_ 2649702903 _0151 "<rw:1:1>  <InterfaceItem:interfaceItem_ce4e8f88_dff0_45a7_abdd_ddbedf3da959:table_items_getMeta:table_items_setMeta:>  <uuid:ce4e8f88-dff0-45a7-abdd-ddbedf3da959>";
CM_ SG_ 2649702903 _0251 "<rw:1:1>  <InterfaceItem:interfaceItem_c1e2c118_c297_4a02_9cbb_4d5b81a23b6b:table_items_getMeta:table_items_setMeta:>  <uuid:c1e2c118-c297-4a02-9cbb-4d5b81a23b6b>";
CM_ SG_ 2649702903 _0351 "<rw:1:1>  <InterfaceItem:interfaceItem_5a94541d_7d3c_4012_8078_b8570e2083dd:table_items_getMeta:table_items_setMeta:>  <uuid:5a94541d-7d3c-4012-8078-b8570e2083dd>";
CM_ SG_ 2649702903 Meta1091 "<rw:1:1>  <uuid:3bd185b1-eaeb-4893-afa4-e985c553853f>";
CM_ SG_ 2649702903 ReadParam_status1091 "<rw:1:1>  <uuid:a1904f40-bb8e-47a9-aa08-6dedc474e23a>";
CM_ SG_ 2649702903 _0451 "<rw:1:1>  <InterfaceItem:interfaceItem_28239aa8_685b_4b0c_a65e_3600359cca92:table_items_getMeta:table_items_setMeta:>  <uuid:28239aa8-685b-4b0c-a65e-3600359cca92>";
CM_ SG_ 2649702903 _0551 "<rw:1:1>  <InterfaceItem:interfaceItem_8f0a4c6e_91f0_4708_ab94_85180ea0b78c:table_items_getMeta:table_items_setMeta:>  <uuid:8f0a4c6e-91f0-4708-ab94-85180ea0b78c>";
CM_ SG_ 2649702903 _0651 "<rw:1:1>  <InterfaceItem:interfaceItem_ac2005bb_b2ff_4932_92ba_fb9c08f526b1:table_items_getMeta:table_items_setMeta:>  <uuid:ac2005bb-b2ff-4932-92ba-fb9c08f526b1>";
CM_ SG_ 2649702903 Meta1092 "<rw:1:1>  <uuid:3bd185b1-eaeb-4893-afa4-e985c553853f>";
CM_ SG_ 2649702903 ReadParam_status1092 "<rw:1:1>  <uuid:a1904f40-bb8e-47a9-aa08-6dedc474e23a>";
CM_ SG_ 2649702903 _0751 "<rw:1:1>  <InterfaceItem:interfaceItem_7bd10def_50cb_4957_a87c_ee22d3605f83:table_items_getMeta:table_items_setMeta:>  <uuid:7bd10def-50cb-4957-a87c-ee22d3605f83>";
CM_ SG_ 2649702903 _0851 "<rw:1:1>  <InterfaceItem:interfaceItem_4609d42a_1b39_4f9f_a41c_2dc6926d24f1:table_items_getMeta:table_items_setMeta:>  <uuid:4609d42a-1b39-4f9f-a41c-2dc6926d24f1>";
CM_ SG_ 2649702903 _0951 "<rw:1:1>  <InterfaceItem:interfaceItem_ed361641_8295_4a1e_820b_641fde36ba4f:table_items_getMeta:table_items_setMeta:>  <uuid:ed361641-8295-4a1e-820b-641fde36ba4f>";
CM_ SG_ 2649702903 Meta1093 "<rw:1:1>  <uuid:3bd185b1-eaeb-4893-afa4-e985c553853f>";
CM_ SG_ 2649702903 ReadParam_status1093 "<rw:1:1>  <uuid:a1904f40-bb8e-47a9-aa08-6dedc474e23a>";
CM_ SG_ 2649702903 _1051 "<rw:1:1>  <InterfaceItem:interfaceItem_b4193d6d_e887_4e83_be62_585a4c7dd5cb:table_items_getMeta:table_items_setMeta:>  <uuid:b4193d6d-e887-4e83-be62-585a4c7dd5cb>";
CM_ SG_ 2649702903 _1151 "<rw:1:1>  <InterfaceItem:interfaceItem_eda9ae16_e06d_42e6_bf59_4041e930b98c:table_items_getMeta:table_items_setMeta:>  <uuid:eda9ae16-e06d-42e6-bf59-4041e930b98c>";
CM_ SG_ 2649702903 _1251 "<rw:1:1>  <InterfaceItem:interfaceItem_075ee998_2c3c_4457_885e_e7722baab2e1:table_items_getMeta:table_items_setMeta:>  <uuid:075ee998-2c3c-4457-885e-e7722baab2e1>";
CM_ SG_ 2649702903 Meta1094 "<rw:1:1>  <uuid:3bd185b1-eaeb-4893-afa4-e985c553853f>";
CM_ SG_ 2649702903 ReadParam_status1094 "<rw:1:1>  <uuid:a1904f40-bb8e-47a9-aa08-6dedc474e23a>";
CM_ SG_ 2649702903 _1351 "<rw:1:1>  <InterfaceItem:interfaceItem_992a5b65_1876_466d_93d0_5f2da06b9a61:table_items_getMeta:table_items_setMeta:>  <uuid:992a5b65-1876-466d-93d0-5f2da06b9a61>";
CM_ SG_ 2649702903 _1451 "<rw:1:1>  <InterfaceItem:interfaceItem_c1696683_f657_41ec_84cc_387ebb2363f0:table_items_getMeta:table_items_setMeta:>  <uuid:c1696683-f657-41ec-84cc-387ebb2363f0>";
CM_ SG_ 2649702903 _1551 "<rw:1:1>  <InterfaceItem:interfaceItem_29d7c91c_0510_489b_80c1_c5d9b41fc3db:table_items_getMeta:table_items_setMeta:>  <uuid:29d7c91c-0510-489b-80c1-c5d9b41fc3db>";
CM_ SG_ 2649702903 Meta1095 "<rw:1:1>  <uuid:3bd185b1-eaeb-4893-afa4-e985c553853f>";
CM_ SG_ 2649702903 ReadParam_status1095 "<rw:1:1>  <uuid:a1904f40-bb8e-47a9-aa08-6dedc474e23a>";
CM_ SG_ 2649702903 _1651 "<rw:1:1>  <InterfaceItem:interfaceItem_f66000cd_42ca_4a2e_959b_e2e5d5c435cd:table_items_getMeta:table_items_setMeta:>  <uuid:f66000cd-42ca-4a2e-959b-e2e5d5c435cd>";
CM_ SG_ 2649702903 _1751 "<rw:1:1>  <InterfaceItem:interfaceItem_e7f597ce_acb4_49c1_a09f_33d6915fd85c:table_items_getMeta:table_items_setMeta:>  <uuid:e7f597ce-acb4-49c1-a09f-33d6915fd85c>";
CM_ SG_ 2649702903 _1851 "<rw:1:1>  <InterfaceItem:interfaceItem_b7a62ede_90a8_49e4_8e3e_14f276f88201:table_items_getMeta:table_items_setMeta:>  <uuid:b7a62ede-90a8-49e4-8e3e-14f276f88201>";
CM_ SG_ 2649702903 Meta1096 "<rw:1:1>  <uuid:3bd185b1-eaeb-4893-afa4-e985c553853f>";
CM_ SG_ 2649702903 ReadParam_status1096 "<rw:1:1>  <uuid:a1904f40-bb8e-47a9-aa08-6dedc474e23a>";
CM_ SG_ 2649702903 _1951 "<rw:1:1>  <InterfaceItem:interfaceItem_e9ad13b6_1217_4fa6_932d_944eb7b0600a:table_items_getMeta:table_items_setMeta:>  <uuid:e9ad13b6-1217-4fa6-932d-944eb7b0600a>";
CM_ SG_ 2649702903 _2051 "<rw:1:1>  <InterfaceItem:interfaceItem_182feb20_d5cb_4841_8014_03ed19b8eb8a:table_items_getMeta:table_items_setMeta:>  <uuid:182feb20-d5cb-4841-8014-03ed19b8eb8a>";
CM_ SG_ 2649702903 Meta1097 "<rw:1:1>  <uuid:3bd185b1-eaeb-4893-afa4-e985c553853f>";
CM_ SG_ 2649702903 ReadParam_status1097 "<rw:1:1>  <uuid:a1904f40-bb8e-47a9-aa08-6dedc474e23a>";
CM_ SG_ 2649702903 RampRateDecrement9 "<rw:1:1>  <InterfaceItem:interfaceItem_96cbfe89_6b26_4f26_94f9_ff6c5bc4392b:table_items_getMeta:table_items_setMeta:>  <uuid:96cbfe89-6b26-4f26-94f9-ff6c5bc4392b>";
CM_ SG_ 2649702903 RampRateIncrement9 "<rw:1:1>  <InterfaceItem:interfaceItem_ed23a30d_64b0_47ff_b0e6_0b7daa2d278a:table_items_getMeta:table_items_setMeta:>  <uuid:ed23a30d-64b0-47ff-b0e6-0b7daa2d278a>";
CM_ SG_ 2649702903 Meta1098 "<rw:1:1>  <uuid:3bd185b1-eaeb-4893-afa4-e985c553853f>";
CM_ SG_ 2649702903 ReadParam_status1098 "<rw:1:1>  <uuid:a1904f40-bb8e-47a9-aa08-6dedc474e23a>";
CM_ SG_ 2649702903 phiAbs3 "<rw:1:1>  <InterfaceItem:interfaceItem_39f81b02_441d_44ee_ab3f_7cef5170732c:items_getMeta:items_setMeta:>  <uuid:39f81b02-441d-44ee-ab3f-7cef5170732c>";
CM_ SG_ 2649702903 Meta1099 "<rw:1:1>  <uuid:3bd185b1-eaeb-4893-afa4-e985c553853f>";
CM_ SG_ 2649702903 ReadParam_status1099 "<rw:1:1>  <uuid:a1904f40-bb8e-47a9-aa08-6dedc474e23a>";
CM_ SG_ 2649702903 phiAbs4 "<rw:1:1>  <InterfaceItem:interfaceItem_45c6663d_7487_4d52_ac8d_e1c8b9095849:items_getMeta:items_setMeta:>  <uuid:45c6663d-7487-4d52-ac8d-e1c8b9095849>";
CM_ SG_ 2649702903 Meta1100 "<rw:1:1>  <uuid:3bd185b1-eaeb-4893-afa4-e985c553853f>";
CM_ SG_ 2649702903 ReadParam_status1100 "<rw:1:1>  <uuid:a1904f40-bb8e-47a9-aa08-6dedc474e23a>";
CM_ SG_ 2649702903 phiAbs5 "<rw:1:1>  <InterfaceItem:interfaceItem_37fe5d03_0c09_4c31_9988_6997a7d5cd69:items_getMeta:items_setMeta:>  <uuid:37fe5d03-0c09-4c31-9988-6997a7d5cd69>";
CM_ SG_ 2649702903 Meta1101 "<rw:1:1>  <uuid:3bd185b1-eaeb-4893-afa4-e985c553853f>";
CM_ SG_ 2649702903 ReadParam_status1101 "<rw:1:1>  <uuid:a1904f40-bb8e-47a9-aa08-6dedc474e23a>";
CM_ SG_ 2649702903 Trigger "<rw:1:1>  <InterfaceItem:interfaceItem_b11f0088_e855_4f12_9f68_a486ab6dba6b:items_getMeta:items_setMeta:>  <uuid:b11f0088-e855-4f12-9f68-a486ab6dba6b>";
CM_ SG_ 2649702903 allowWPhaseOV "<rw:1:1>  <InterfaceItem:interfaceItem_6456e9a9_1c04_4187_b267_edd6444c2652:items_getMeta:items_setMeta:>  <uuid:6456e9a9-1c04-4187-b267-edd6444c2652>";
CM_ SG_ 2649702903 Delay "<rw:1:1>  <InterfaceItem:interfaceItem_d0ed1407_6281_4b9a_a879_4b0d945a1065:items_getMeta:items_setMeta:>  <uuid:d0ed1407-6281-4b9a-a879-4b0d945a1065>";
CM_ SG_ 2649702903 Duration "<rw:1:1>  <InterfaceItem:interfaceItem_61e69470_da69_4447_9c20_bd000ab9b791:items_getMeta:items_setMeta:>  <uuid:61e69470-da69-4447-9c20-bd000ab9b791>";
CM_ SG_ 2649702903 Meta1102 "<rw:1:1>  <uuid:3bd185b1-eaeb-4893-afa4-e985c553853f>";
CM_ SG_ 2649702903 ReadParam_status1102 "<rw:1:1>  <uuid:a1904f40-bb8e-47a9-aa08-6dedc474e23a>";
CM_ SG_ 2649702903 Enable8 "Enables HzWattLimit <rw:1:1>  <InterfaceItem:interfaceItem_acad3a47_74e2_4459_98e1_457eded4c019:items_getMeta:items_setMeta:>  <uuid:acad3a47-74e2-4459-98e1-457eded4c019>";
CM_ SG_ 2649702903 fFiltTau "Input frequency filter time constant <rw:1:1>  <InterfaceItem:interfaceItem_621a49d2_a396_4f2c_a43e_4a8e1102472e:items_getMeta:items_setMeta:>  <uuid:621a49d2-a396-4f2c-a43e-4a8e1102472e>";
CM_ SG_ 2649702903 Meta1103 "<rw:1:1>  <uuid:3bd185b1-eaeb-4893-afa4-e985c553853f>";
CM_ SG_ 2649702903 ReadParam_status1103 "<rw:1:1>  <uuid:a1904f40-bb8e-47a9-aa08-6dedc474e23a>";
CM_ SG_ 2649702903 db_OF "Single-sided deadband for high-frequency disturbances <rw:1:1>  <InterfaceItem:interfaceItem_8bec7ce4_3e24_4b86_a444_6a9359d94176:items_getMeta:items_setMeta:>  <uuid:8bec7ce4-3e24-4b86-a444-6a9359d94176>";
CM_ SG_ 2649702903 db_UF "Single-sided deadband for low-frequency disturbances <rw:1:1>  <InterfaceItem:interfaceItem_3a23bd66_6790_4443_b1c3_d79649feb723:items_getMeta:items_setMeta:>  <uuid:3a23bd66-6790-4443-b1c3-d79649feb723>";
CM_ SG_ 2649702903 Meta1104 "<rw:1:1>  <uuid:3bd185b1-eaeb-4893-afa4-e985c553853f>";
CM_ SG_ 2649702903 ReadParam_status1104 "<rw:1:1>  <uuid:a1904f40-bb8e-47a9-aa08-6dedc474e23a>";
CM_ SG_ 2649702903 droop_OF "Frequency change corresponding to 1 p.u. power output change in high-frequency disturbances <rw:1:1>  <InterfaceItem:interfaceItem_a0c0731c_2f1d_4116_9e0a_024f48957521:items_getMeta:items_setMeta:>  <uuid:a0c0731c-2f1d-4116-9e0a-024f48957521>";
CM_ SG_ 2649702903 droop_UF "Frequency change corresponding to 1 p.u. power output change in low-frequency disturbances <rw:1:1>  <InterfaceItem:interfaceItem_1c0b9491_8dc1_4e43_abaa_18d2b42f4d09:items_getMeta:items_setMeta:>  <uuid:1c0b9491-8dc1-4e43-abaa-18d2b42f4d09>";
CM_ SG_ 2649702903 Meta1105 "<rw:1:1>  <uuid:3bd185b1-eaeb-4893-afa4-e985c553853f>";
CM_ SG_ 2649702903 ReadParam_status1105 "<rw:1:1>  <uuid:a1904f40-bb8e-47a9-aa08-6dedc474e23a>";
CM_ SG_ 2649702903 LogDataEnable "Enables/Disables log data functions. <rw:1:1>  <InterfaceItem:interfaceItem_fa5f13a9_247c_4833_b5bd_05ddfde59687:items_getMeta:items_setMeta:>  <uuid:fa5f13a9-247c-4833-b5bd-05ddfde59687>";
CM_ SG_ 2649702903 Meta1106 "<rw:1:1>  <uuid:3bd185b1-eaeb-4893-afa4-e985c553853f>";
CM_ SG_ 2649702903 ReadParam_status1106 "<rw:1:1>  <uuid:a1904f40-bb8e-47a9-aa08-6dedc474e23a>";
CM_ SG_ 2649702903 RefMode "Selects voltage reference mode for volt-var <rw:1:1>  <InterfaceItem:interfaceItem_637517fa_5141_4b0a_ad9f_3145c0110b6d:items_getMeta:items_setMeta:>  <uuid:637517fa-5141-4b0a-ad9f-3145c0110b6d>";
CM_ SG_ 2649702903 AutoVrefFilterTimeConst "Time constant for filtering autonomous volt-var reference voltage <rw:1:1>  <InterfaceItem:interfaceItem_220cce59_a640_4285_84a1_9898c65ad587:items_getMeta:items_setMeta:>  <uuid:220cce59-a640-4285-84a1-9898c65ad587>";
CM_ SG_ 2649702903 FixedVref "Fixed reference voltage for volt-var <rw:1:1>  <InterfaceItem:interfaceItem_610521ba_e61c_4391_95cd_09d480ab1913:items_getMeta:items_setMeta:>  <uuid:610521ba-e61c-4391-95cd-09d480ab1913>";
CM_ SG_ 2649702903 Meta1107 "<rw:1:1>  <uuid:3bd185b1-eaeb-4893-afa4-e985c553853f>";
CM_ SG_ 2649702903 ReadParam_status1107 "<rw:1:1>  <uuid:a1904f40-bb8e-47a9-aa08-6dedc474e23a>";
CM_ SG_ 2649702903 kneePower1 "Upper knee power for VoltWatt limit curve <rw:1:1>  <InterfaceItem:interfaceItem_65aaf226_79ec_4333_bf7f_bbaf1e1f739f:items_getMeta:items_setMeta:>  <uuid:65aaf226-79ec-4333-bf7f-bbaf1e1f739f>";
CM_ SG_ 2649702903 kneePower2 "Lower knee power for VoltWatt limit curve <rw:1:1>  <InterfaceItem:interfaceItem_635ae703_8f05_42ac_add6_062dff63e11c:items_getMeta:items_setMeta:>  <uuid:635ae703-8f05-42ac-add6-062dff63e11c>";
CM_ SG_ 2649702903 Meta1108 "<rw:1:1>  <uuid:3bd185b1-eaeb-4893-afa4-e985c553853f>";
CM_ SG_ 2649702903 ReadParam_status1108 "<rw:1:1>  <uuid:a1904f40-bb8e-47a9-aa08-6dedc474e23a>";
CM_ SG_ 2649702903 PtoP_gain "Active power reference to active power offset gain <rw:1:1>  <InterfaceItem:interfaceItem_b81cb213_8011_4c21_ad80_a8c2a7905a02:items_getMeta:items_setMeta:>  <uuid:b81cb213-8011-4c21-ad80-a8c2a7905a02>";
CM_ SG_ 2649702903 PtoQ_gain "Active power reference to reactive power offset gain <rw:1:1>  <InterfaceItem:interfaceItem_54725e6e_c358_4518_b9f1_dff71ed29bff:items_getMeta:items_setMeta:>  <uuid:54725e6e-c358-4518-b9f1-dff71ed29bff>";
CM_ SG_ 2649702903 Meta1109 "<rw:1:1>  <uuid:3bd185b1-eaeb-4893-afa4-e985c553853f>";
CM_ SG_ 2649702903 ReadParam_status1109 "<rw:1:1>  <uuid:a1904f40-bb8e-47a9-aa08-6dedc474e23a>";
CM_ SG_ 2649702903 QtoP_gain "Reactive power reference to active power offset gain <rw:1:1>  <InterfaceItem:interfaceItem_e55013a9_1d58_4ecd_978c_375d8ed840b2:items_getMeta:items_setMeta:>  <uuid:e55013a9-1d58-4ecd-978c-375d8ed840b2>";
CM_ SG_ 2649702903 QtoQ_gain "Reactive power reference to reactive power offset gain <rw:1:1>  <InterfaceItem:interfaceItem_2a38ccef_4842_49b8_b18f_d973c5a2882b:items_getMeta:items_setMeta:>  <uuid:2a38ccef-4842-49b8-b18f-d973c5a2882b>";
CM_ SG_ 2649702903 Meta1110 "<rw:1:1>  <uuid:3bd185b1-eaeb-4893-afa4-e985c553853f>";
CM_ SG_ 2649702903 ReadParam_status1110 "<rw:1:1>  <uuid:a1904f40-bb8e-47a9-aa08-6dedc474e23a>";
CM_ SG_ 2649702903 Pneg_Qpos0 "P offset with negative P and positive Q ref <rw:1:1>  <InterfaceItem:interfaceItem_29f831e7_b232_4d35_9011_97a4e273df01:items_getMeta:items_setMeta:>  <uuid:29f831e7-b232-4d35-9011-97a4e273df01>";
CM_ SG_ 2649702903 Pneg_Q00 "P offset with negative P and zero Q ref <rw:1:1>  <InterfaceItem:interfaceItem_e180cf2f_7d24_41b0_a64d_d09ceb39b60a:items_getMeta:items_setMeta:>  <uuid:e180cf2f-7d24-41b0-a64d-d09ceb39b60a>";
CM_ SG_ 2649702903 Pneg_Qneg0 "P offset with negative P and negative Q ref <rw:1:1>  <InterfaceItem:interfaceItem_c9a94897_83c7_4bd8_8b22_819ac7b47301:items_getMeta:items_setMeta:>  <uuid:c9a94897-83c7-4bd8-8b22-819ac7b47301>";
CM_ SG_ 2649702903 Meta1111 "<rw:1:1>  <uuid:3bd185b1-eaeb-4893-afa4-e985c553853f>";
CM_ SG_ 2649702903 ReadParam_status1111 "<rw:1:1>  <uuid:a1904f40-bb8e-47a9-aa08-6dedc474e23a>";
CM_ SG_ 2649702903 P0_Qpos0 "P offset with zero P and positive Q ref <rw:1:1>  <InterfaceItem:interfaceItem_663c4f8f_5d5b_46ec_b2cb_c0bb1614fdd7:items_getMeta:items_setMeta:>  <uuid:663c4f8f-5d5b-46ec-b2cb-c0bb1614fdd7>";
CM_ SG_ 2649702903 P0_Qneg0 "P offset with zero P and negative Q ref <rw:1:1>  <InterfaceItem:interfaceItem_ba3a70a8_ee25_4841_ae9f_3335b59cdcba:items_getMeta:items_setMeta:>  <uuid:ba3a70a8-ee25-4841-ae9f-3335b59cdcba>";
CM_ SG_ 2649702903 MeaspointPref "Active power reference at measurement point for power offset compensation <rw:1:1>  <InterfaceItem:interfaceItem_4f42e61d_4445_47cd_a991_8d9132bb3c23:items_getMeta:items_setMeta:>  <uuid:4f42e61d-4445-47cd-a991-8d9132bb3c23>";
CM_ SG_ 2649702903 Meta1112 "<rw:1:1>  <uuid:3bd185b1-eaeb-4893-afa4-e985c553853f>";
CM_ SG_ 2649702903 ReadParam_status1112 "<rw:1:1>  <uuid:a1904f40-bb8e-47a9-aa08-6dedc474e23a>";
CM_ SG_ 2649702903 Ppos_Qpos0 "P offset with positive P and positive Q ref <rw:1:1>  <InterfaceItem:interfaceItem_f8666e1a_b4bf_4d21_914b_92ee1e079852:items_getMeta:items_setMeta:>  <uuid:f8666e1a-b4bf-4d21-914b-92ee1e079852>";
CM_ SG_ 2649702903 Ppos_Q00 "P offset with positive P and zero Q ref <rw:1:1>  <InterfaceItem:interfaceItem_e53217c7_ec7d_43e2_ae9a_0c443cf0cad3:items_getMeta:items_setMeta:>  <uuid:e53217c7-ec7d-43e2-ae9a-0c443cf0cad3>";
CM_ SG_ 2649702903 Ppos_Qneg0 "P offset with positive P and negative Q ref <rw:1:1>  <InterfaceItem:interfaceItem_c4e7037c_14fd_4946_bb1b_7201dbe0a117:items_getMeta:items_setMeta:>  <uuid:c4e7037c-14fd-4946-bb1b-7201dbe0a117>";
CM_ SG_ 2649702903 Meta1113 "<rw:1:1>  <uuid:3bd185b1-eaeb-4893-afa4-e985c553853f>";
CM_ SG_ 2649702903 ReadParam_status1113 "<rw:1:1>  <uuid:a1904f40-bb8e-47a9-aa08-6dedc474e23a>";
CM_ SG_ 2649702903 Pneg_Qpos1 "Q offset with negative P and positive Q ref <rw:1:1>  <InterfaceItem:interfaceItem_fcb0c5ad_24c7_4efc_b83d_b625a5c58201:items_getMeta:items_setMeta:>  <uuid:fcb0c5ad-24c7-4efc-b83d-b625a5c58201>";
CM_ SG_ 2649702903 Pneg_Q01 "Q offset with negative P and zero Q ref <rw:1:1>  <InterfaceItem:interfaceItem_764fa2ee_07a5_4972_9004_edf06ebd1e12:items_getMeta:items_setMeta:>  <uuid:764fa2ee-07a5-4972-9004-edf06ebd1e12>";
CM_ SG_ 2649702903 Pneg_Qneg1 "Q offset with negative P and negative Q ref <rw:1:1>  <InterfaceItem:interfaceItem_826f62a1_e972_4c17_83fe_12e6d285ebff:items_getMeta:items_setMeta:>  <uuid:826f62a1-e972-4c17-83fe-12e6d285ebff>";
CM_ SG_ 2649702903 Meta1114 "<rw:1:1>  <uuid:3bd185b1-eaeb-4893-afa4-e985c553853f>";
CM_ SG_ 2649702903 ReadParam_status1114 "<rw:1:1>  <uuid:a1904f40-bb8e-47a9-aa08-6dedc474e23a>";
CM_ SG_ 2649702903 P0_Qpos1 "Q offset with zero P and positive Q ref <rw:1:1>  <InterfaceItem:interfaceItem_cf3a70a0_5f28_46f9_ba34_bdf28d28edb7:items_getMeta:items_setMeta:>  <uuid:cf3a70a0-5f28-46f9-ba34-bdf28d28edb7>";
CM_ SG_ 2649702903 P0_Qneg1 "Q offset with zero P and negative Q ref <rw:1:1>  <InterfaceItem:interfaceItem_138a84d1_19cb_4da5_994b_57687018759e:items_getMeta:items_setMeta:>  <uuid:138a84d1-19cb-4da5-994b-57687018759e>";
CM_ SG_ 2649702903 MeaspointQref "Reactive power reference at measurement point for power offset compensation <rw:1:1>  <InterfaceItem:interfaceItem_88aeecc7_9e96_4477_9bad_5595f5b62685:items_getMeta:items_setMeta:>  <uuid:88aeecc7-9e96-4477-9bad-5595f5b62685>";
CM_ SG_ 2649702903 Meta1115 "<rw:1:1>  <uuid:3bd185b1-eaeb-4893-afa4-e985c553853f>";
CM_ SG_ 2649702903 ReadParam_status1115 "<rw:1:1>  <uuid:a1904f40-bb8e-47a9-aa08-6dedc474e23a>";
CM_ SG_ 2649702903 Ppos_Qpos1 "Q offset with positive P and positive Q ref <rw:1:1>  <InterfaceItem:interfaceItem_9f428c36_20c3_4ec2_a030_b17239c9a71f:items_getMeta:items_setMeta:>  <uuid:9f428c36-20c3-4ec2-a030-b17239c9a71f>";
CM_ SG_ 2649702903 Ppos_Q01 "Q offset with positive P and zero Q ref <rw:1:1>  <InterfaceItem:interfaceItem_89a71a78_438a_458f_8b99_8793aa157b26:items_getMeta:items_setMeta:>  <uuid:89a71a78-438a-458f-8b99-8793aa157b26>";
CM_ SG_ 2649702903 Ppos_Qneg1 "Q offset with positive P and negative Q ref <rw:1:1>  <InterfaceItem:interfaceItem_c2d51dce_fc36_4b79_be7d_83a391078111:items_getMeta:items_setMeta:>  <uuid:c2d51dce-fc36-4b79-be7d-83a391078111>";
CM_ SG_ 2582594039 CommandCounter0 "<rw:1:1>  <uuid:2d4eeab6-daf0-4976-8fde-4f521bc92093>";
CM_ SG_ 2582594039 CommandReturnCode0 "<rw:1:1>  <uuid:32b59f16-b138-4952-bd1e-839ed179b7f9>";
CM_ SG_ 2582594039 CommandCounter1 "<rw:1:1>  <uuid:5179aa67-893e-45aa-8a57-af2fbc339c15>";
CM_ SG_ 2582594039 CommandReturnCode1 "<rw:1:1>  <uuid:41f83720-7beb-4f22-932f-d1fc8f2bd3b8>";
CM_ SG_ 2582594039 CommandCounter2 "<rw:1:1>  <uuid:69f29f67-156d-4627-9347-8b07fc99a559>";
CM_ SG_ 2582594039 CommandReturnCode2 "<rw:1:1>  <uuid:928eb49e-e46c-4e82-9ed2-ba79c0f6f865>";
CM_ SG_ 2582594039 CommandCounter3 "<rw:1:1>  <uuid:6d003617-e530-4104-a8c3-16e75dfc6e99>";
CM_ SG_ 2582594039 CommandReturnCode3 "<rw:1:1>  <uuid:8c67696d-ed80-4842-aa25-040d4b12f5e8>";
CM_ SG_ 2582594039 Byte0 "<rw:1:1>  <uuid:042a9b43-eb2b-43e1-bd5a-ba7bf6939623>";
CM_ SG_ 2582594039 Byte1 "<rw:1:1>  <uuid:68f4bca1-4d3d-482c-b846-a2688cecd112>";
CM_ SG_ 2582594039 Byte2 "<rw:1:1>  <uuid:80258417-94c8-41af-ac81-04840c21dff9>";
CM_ SG_ 2582594039 Byte3 "<rw:1:1>  <uuid:0b52a6e4-7b40-4970-b46e-b9b16ab49f37>";
CM_ SG_ 2582594039 Byte4 "<rw:1:1>  <uuid:4212f1b4-d832-4d67-94e4-c1a9a9669da9>";
CM_ SG_ 2582594039 CommandCounter4 "<rw:1:1>  <uuid:1b686af6-7c1c-4f62-abe1-fa47126646e0>";
CM_ SG_ 2582594039 CommandReturnCode4 "<rw:1:1>  <uuid:119afa2c-2c3f-4897-ba2a-43050a970008>";
CM_ SG_ 2566902007 CurrentU "Measured L1 phase current. <rw:1:0>  <uuid:35eaa236-76d4-48bb-b7ca-ba3231d47531>";
CM_ SG_ 2566902007 CurrentV "Measured L2 phase current. <rw:1:0>  <uuid:96c44a7e-f303-4fa6-90b6-245705eabbde>";
CM_ SG_ 2566902007 CurrentW "Measured L3 phase current. <rw:1:0>  <uuid:5cb32f56-29f0-4b33-8a2f-94674b31b7a4>";
CM_ SG_ 2566902263 VoltageU "Measured L1 phase voltage <rw:1:1>  <uuid:99a617c4-41d0-4f8e-8eb4-ac67c639ca64>";
CM_ SG_ 2566902263 VoltageV "Measured L2 phase voltage <rw:1:1>  <uuid:4e8310da-898b-4741-ac0f-ffeee4cca810>";
CM_ SG_ 2566902263 VoltageW "Measured L3 phase voltage <rw:1:1>  <uuid:60567112-2d4d-47f4-b273-9b2114c07966>";
CM_ SG_ 2566902519 VoltageU "Measured remote L1 phase voltage <rw:1:0>  <uuid:0f85eb1a-ce3c-45a2-9d90-6b2394be556a>";
CM_ SG_ 2566902519 VoltageV "Measured remote L2 phase voltage <rw:1:0>  <uuid:c8fdc04e-cc5c-411c-b1c2-d689b0a400bb>";
CM_ SG_ 2566902519 VoltageW "Measured remote L3 phase voltage <rw:1:0>  <uuid:e14ed400-6e50-4164-bfe7-5b651198bead>";
CM_ SG_ 2634006775 NetworkVoltage "Measured remote line voltage. <rw:1:1>  <uuid:4f9eace9-b5a3-4f10-bfdf-65a4c1d868ca>";
CM_ SG_ 2634006775 NetworkFrequency "Measured remote frequency. <rw:1:1>  <uuid:dc66c876-d3fe-4552-987c-816ef14deb66>";
CM_ SG_ 2634006775 PhaseSequence "Remote phase sequence.  When L1 phase angle leads L2 phase angle, rotation is considered positive. <rw:1:1>  <uuid:86d64f8d-606b-484f-9631-7d9abe145aff>";
CM_ SG_ 2634006775 VoltageDetected "Flag indicating if voltage is detected on remote L1, L2 or L3. <rw:1:1>  <uuid:119658ac-3e03-467f-b33c-387afb7d2a2b>";
CM_ SG_ 2634006775 NetworkInSpec "Indicates whether remote AC supply voltage and frequency are within nominal ranges. <rw:1:1>  <uuid:359e8c21-9d55-44ae-90ef-a32aeb5006f6>";
CM_ SG_ 2365573879 RealPower_measured "Actual real power. <rw:1:1>  <uuid:2fa14544-7846-407b-bc80-3d27489ac167>";
CM_ SG_ 2365573879 ReactivePower_measured "Actual reactive power. <rw:1:1>  <uuid:53b4feba-ccdd-4e67-bdfd-4e538718389f>";
CM_ SG_ 2365573879 ApparentPower_measured "Actual apparent power. <rw:1:1>  <uuid:74d699b5-72d5-44bf-95c8-a8bd89f03326>";
CM_ SG_ 2566898935 RealPower_echo "Echoed real power command. <rw:1:1>  <uuid:cfd0460d-93f7-4f82-af89-2a0b0e6bd034>";
CM_ SG_ 2566898935 ReactivePower_echo "Echoed reactive power command. <rw:1:1>  <uuid:21ed44cd-57fc-419a-a842-25c3dd2d7ffd>";
CM_ SG_ 2365572087 WarningClr_echo "Echos the state of the WarningClear command within the CommandModeControl message. <rw:1:1>  <uuid:fbc0c33f-6193-4178-91ae-039b00d353da>";
CM_ SG_ 2365572087 IslandReconnect_echo "Echo IslandReconnect of CommandModeControl. <rw:1:1>  <uuid:36d701f4-17a2-45c1-ae46-b338f61839f5>";
CM_ SG_ 2365572087 ProtBusSequence "Actual protected bus connection sequence (state). <rw:1:1>  <uuid:7def0ab2-897f-4ff5-a7b9-955ac7a9751f>";
CM_ SG_ 2365572087 FaultClr_echo "Echos the state of the FaultClear command within the CommandModeControl message. <rw:1:1>  <uuid:d84e5184-696d-487c-8850-cc904a7c018f>";
CM_ SG_ 2365572087 Enable_echo "Echos the state of the Enable command within the CommandModeControl message. <rw:1:1>  <uuid:adc939ca-4101-4681-9151-8606ab0ec533>";
CM_ SG_ 2365572087 State "Active control mode. <rw:1:1>  <uuid:6392782a-b886-45a0-9642-dd4f47cd2a59>";
CM_ SG_ 2365572087 PowerCircuitEnabled "Indicates operational status of the power stage. <rw:1:1>  <uuid:3cb5a918-b33f-4cac-a3ff-409153d42f89>";
CM_ SG_ 2365572087 PowerAvailDC "Indicates that DC bus voltage is within operating range. <rw:1:1>  <uuid:2bc57a13-6538-4d4c-8147-451516a09131>";
CM_ SG_ 2365572087 Warning "Indicates that one or more warnings are active <rw:1:1>  <uuid:0798a69d-2f7c-4cd2-8347-23b2a1d8c546>";
CM_ SG_ 2365572087 HardwareEnable "Status of the hardware enable. <rw:1:1>  <uuid:ba3a6fc4-06e1-4182-8c30-23c8b5de7c1c>";
CM_ SG_ 2365572087 K2DCRunPermissive "K2 DC Run relay status. <rw:1:1>  <uuid:3599bdae-0cd9-4461-ab73-932320e9be8d>";
CM_ SG_ 2365572087 K1PrechargePermissive "K1 precharge relay status. <rw:1:1>  <uuid:f05ebffa-a4e8-456b-81db-5fd7d3447029>";
CM_ SG_ 2365572087 MX2Permissive "MX2 relay status <rw:1:1>  <uuid:8e3afb7b-5fb8-40e3-b2f0-8bf771a7280d>";
CM_ SG_ 2365572087 MX1Permissive "MX1 relay status <rw:1:1>  <uuid:d42b3b40-4c38-47d4-b36c-9f98e5f20295>";
CM_ SG_ 2365572087 DI4 "<rw:1:1>  <uuid:a16c3206-dc01-441b-813f-c776d45f049c>";
CM_ SG_ 2365572087 DI3 "<rw:1:1>  <uuid:01e742ba-9ce9-4abf-9356-b9e724df239a>";
CM_ SG_ 2365572087 DI2 "<rw:1:1>  <uuid:3c36d774-d640-48e4-bd53-8dd5988b8cc0>";
CM_ SG_ 2365572087 DI1 "<rw:1:1>  <uuid:51cf15fb-d535-488f-9208-eb67cce4fa5a>";
CM_ SG_ 2365572087 MessageValidPowerCMD "Indicates the validity of the CommandPower message. <rw:1:1>  <uuid:1f5295bc-ce3c-4148-8ecf-7a2923c91769>";
CM_ SG_ 2365572087 MessageValidModeControl "Indicates the validity of the CommandModeControl message.  Message must be received at least once per second and parameter data within range to be considered valid. <rw:1:1>  <uuid:8afe65c1-e840-4476-bc92-3431d5042428>";
CM_ SG_ 2365572087 MessageValidDcControl "Indicates the validity of the CommandDcControl message. <rw:1:1>  <uuid:6d966883-e8be-416e-b7e0-000264cceefb>";
CM_ SG_ 2365572087 MessageValidCurrentCMD "Indicates the validity of the CommandCurrent message. <rw:1:1>  <uuid:50a40a03-41b9-4c73-b96f-90c1b11689d3>";
CM_ SG_ 2365572087 PumpFault "<rw:1:1>  <uuid:8150ab0f-f346-4b27-b0fd-67d7da911bbd>";
CM_ SG_ 2365572087 PumpRun "<rw:1:1>  <uuid:b67f3f20-3e87-4e7d-a20d-7122f2afa158>";
CM_ SG_ 2566893815 FanSpeed "Cooling fan speed (aircooled units only) <rw:1:0>  <uuid:9efaa0b7-be14-4af3-8a16-c257ed47f233>";
CM_ SG_ 2365571831 NetworkVoltage "Measured RMS line voltage. <rw:1:0>  <uuid:17b25f6e-e743-4607-a259-1c7e56621f7a>";
CM_ SG_ 2365571831 NetworkFrequency "Measured frequency. <rw:1:0>  <uuid:078c2a7c-1cd3-4734-a31c-ae9b034d2368>";
CM_ SG_ 2365571831 PhaseSequence "Phase sequence.  When L1 phase angle leads L2 phase angle, rotation is considered positive. <rw:1:1>  <uuid:2edc0df3-b31b-40b1-aa94-cd52f3055dfa>";
CM_ SG_ 2365571831 VoltageDetected "Flag indicating if voltage is detected on L1, L2 or L3. <rw:1:1>  <uuid:b66a1664-6cbc-4753-aa6e-d29c242a6939>";
CM_ SG_ 2365571831 NetworkInSpec "Indicates whether AC supply voltage and frequency are within nominal ranges. <rw:1:1>  <uuid:847d637d-d288-42ba-b15a-f7441c26fabe>";
CM_ SG_ 2634008567 DcVoltageHi "Measured DC-link/high-side voltage. <rw:1:0>  <uuid:a6928ae2-13f2-4e1e-98e9-06fb9c4a62a5>";
CM_ SG_ 2634008567 DcCurrentHi "Estimated DC-link/high-side current. <rw:1:0>  <uuid:049d3739-7bbb-481c-967a-6d59b68c4925>";
CM_ SG_ 2634008567 DcVoltageLo "Measured or estimated DC-input/low-side voltage. <rw:1:0>  <uuid:ba8251b1-9fdd-44f1-86e0-a39e99236c17>";
CM_ SG_ 2634008567 DcCurrentLo "Estimated DC-input/low-side current. <rw:1:0>  <uuid:aa21f1bb-05dc-4464-9b62-a86407201903>";
CM_ SG_ 2634008823 CurrentRefHi_VoltageCtl "<rw:1:0>  <uuid:684521c1-beca-4de2-9f28-60a527a201a4>";
CM_ SG_ 2634008823 CurrentRefLo_CurrentCtl "<rw:1:0>  <uuid:747fafa5-238b-48d0-b67f-681e2883e4dc>";
CM_ SG_ 2634008823 CurrentRefLo_MPPT "<rw:1:0>  <uuid:8eb11b17-94cc-4f43-b1dd-a2eeb8e77081>";
CM_ SG_ 2634009335 DcMidpointOffset "<rw:1:0>  <uuid:55c57634-397a-4fb7-b567-ad9720fac6a6>";
CM_ SG_ 2634009335 DcMidpointRipple "<rw:1:0>  <uuid:e0079eab-c36d-42d9-bb48-7a93b4c09aed>";
CM_ SG_ 2634009847 RealCurrent_echo "Commanded real current while in grid following mode - positive real current is defined as power being put into the ac network. <rw:1:1>  <uuid:fb6507c1-c90e-455f-8187-41a530c5a347>";
CM_ SG_ 2634009847 ReactiveCurrent_echo "Commanded reactive current while in grid following mode - positive reactive current is defined as the converter having a lagging power factor. <rw:1:1>  <uuid:b06eb2b4-4852-4a95-87d7-96a5ad6c87d2>";
CM_ SG_ 2365571575 CurrentReal "Measured real current. <rw:1:0>  <uuid:9e0c1363-3baa-4ecd-873e-f360ca18ae29>";
CM_ SG_ 2365571575 CurrentReactive "Measured reactive current. <rw:1:0>  <uuid:85356065-2757-413e-b549-a6bda3b9fd6d>";
CM_ SG_ 2365571575 CurrentApparent "Measured RMS phase current. <rw:1:0>  <uuid:6754168c-757a-432d-bd08-3d36412cbc0c>";
CM_ SG_ 2566902775 VoltageUV "Measured L1 To L2 RMS voltage <rw:1:1>  <uuid:57a4e7a9-4ce5-4236-9dfd-b19c4b22a787>";
CM_ SG_ 2566902775 VoltageVW "Measured L2 To L3 RMS voltage <rw:1:1>  <uuid:6c26d8ef-131f-41c4-acb5-0fa68262434d>";
CM_ SG_ 2566902775 VoltageWU "Measured L3 To L1 RMS voltage <rw:1:1>  <uuid:2c8ad59d-5243-4cb6-ae95-74df0296759f>";
CM_ SG_ 2566903031 VoltageUV "Measured remote L1 To L2 RMS voltage <rw:1:0>  <uuid:19d984d3-1f11-42ca-a1aa-9205e96410f5>";
CM_ SG_ 2566903031 VoltageVW "Measured remote L2 To L3 RMS voltage <rw:1:0>  <uuid:fa6d47a9-89ae-4645-91d1-bb892ba6f529>";
CM_ SG_ 2566903031 VoltageWU "Measured remote L3 To L1 RMS voltage <rw:1:0>  <uuid:f6395275-e6e4-4079-aff1-91674344f494>";
CM_ SG_ 2566903287 dcVoltageLimit_echo "<rw:1:1>  <uuid:8dd81e3f-df14-45d2-888a-5772a68e900c>";
CM_ SG_ 2566894071 tInternal "Internal ambient temperature <rw:1:0>  <uuid:2213d65c-5326-47d6-a247-546393e9b117>";
CM_ SG_ 2566894071 tInlet "Coolant inlet temperature <rw:1:0>  <uuid:fd76413f-af6f-49e0-a49a-316232644ae5>";
CM_ SG_ 2566894071 tBridgeA "Bridge A measured temperature <rw:1:0>  <uuid:bd0a4e2f-f7b5-42de-a64f-9d79fc7b2294>";
CM_ SG_ 2566894071 tBridgeB "Bridge B measured temperature <rw:1:0>  <uuid:dd42319a-b63a-4937-83be-4a3168a6c582>";
CM_ SG_ 2566894327 TPvj_A "<rw:1:1>  <uuid:15026bc2-bf75-4793-b069-7870ea9925fc>";
CM_ SG_ 2566894327 TPvj_B "<rw:1:1>  <uuid:7ef52c45-4461-40cd-a009-79fcd714bd4c>";
CM_ SG_ 2566894327 TPvj_C "<rw:1:1>  <uuid:1b55b29c-754e-47c4-afc4-1f7a4b94461e>";
CM_ SG_ 2566894327 TPvj_D "<rw:1:1>  <uuid:bc6ba829-0f01-48b1-a6db-578990e75c7d>";
CM_ SG_ 2566894583 TPvj_E "<rw:1:1>  <uuid:ae34196e-a509-4ec0-b56a-e92132e03fab>";
CM_ SG_ 2566894583 TPvj_F "<rw:1:1>  <uuid:5cd1ceac-9588-454a-b8f8-f3987e4cc576>";
CM_ SG_ 2566894583 Tvj_max "<rw:1:1>  <uuid:afeec0bc-39c2-4308-9423-c77ecb0b8043>";
CM_ SG_ 2566894583 Tsense "<rw:1:1>  <uuid:5c3990e1-79e9-4ca8-bea1-130a5cfb5c0f>";
CM_ SG_ 2566894839 Pl_tot "<rw:1:1>  <uuid:526ce313-562b-4103-aa3a-4f3de9e9b91c>";
CM_ SG_ 2566895095 CurrentPS "Measured PS current <rw:1:0>  <uuid:72fcca6c-4b9f-4aa7-80c6-36225e5b53d9>";
CM_ SG_ 2566895095 CurrentNS "Measured NS current <rw:1:0>  <uuid:5563ff7e-db04-4b31-9272-2af975460274>";
CM_ SG_ 2566895095 LineVoltagePS "Measured PS voltage <rw:1:0>  <uuid:5c75b586-16a0-48b0-9c5b-6fee4a4c925a>";
CM_ SG_ 2566895095 LineVoltageNS "Measured NS voltage <rw:1:0>  <uuid:2a6c186c-2679-4a62-8b9a-8832bb2dfdec>";
CM_ SG_ 2566895351 CurrentRealPS "Measured real component of PS current <rw:1:0>  <uuid:d796577f-24bc-4485-b943-d43365f876fe>";
CM_ SG_ 2566895351 CurrentReactivePS "Measured reactive component of PS current <rw:1:0>  <uuid:566c0325-1c74-49e1-9fee-8343924eff7d>";
CM_ SG_ 2566895351 CurrentRealNS "Measured real component of NS current <rw:1:0>  <uuid:cb96f6a0-1ff8-4251-8e36-c792c12173ba>";
CM_ SG_ 2566895351 CurrentReactiveNS "Measured reactive component of NS current <rw:1:0>  <uuid:31ef7e33-9a93-4d12-9d58-e9c35752ea81>";
CM_ SG_ 2566895607 Power "Echoed mppt real power command for dcdc <rw:1:0>  <uuid:877a1a57-6e05-41f7-a4f1-14df57f05263>";

BA_DEF_ BO_ "GenMsgCycleTime" INT 0 65535;
BA_DEF_ BO_ "Receivable" STRING;
BA_DEF_ BO_ "Sendable" STRING;
BA_DEF_ SG_ "DisplayDecimalPlaces" INT 0 65535;
BA_DEF_ SG_ "GenSigStartValue" FLOAT 0 100000000000;
BA_DEF_ SG_ "HexadecimalOutput" STRING;
BA_DEF_ SG_ "LongName" STRING;
BA_DEF_ SG_ "SystemSignalLongSymbol" STRING;
BA_ "Receivable" BO_ 2582594039 "True";
BA_ "Sendable" BO_ 2582594039 "True";
BA_ "GenMsgCycleTime" BO_ 2566902007 100;
BA_ "Receivable" BO_ 2566902007 "True";
BA_ "Sendable" BO_ 2566902007 "True";
BA_ "GenMsgCycleTime" BO_ 2566902263 100;
BA_ "Receivable" BO_ 2566902263 "True";
BA_ "Sendable" BO_ 2566902263 "True";
BA_ "GenMsgCycleTime" BO_ 2566902519 100;
BA_ "Receivable" BO_ 2566902519 "True";
BA_ "Sendable" BO_ 2566902519 "True";
BA_ "GenMsgCycleTime" BO_ 2634006775 100;
BA_ "Receivable" BO_ 2634006775 "True";
BA_ "Sendable" BO_ 2634006775 "True";
BA_ "GenMsgCycleTime" BO_ 2365573879 100;
BA_ "Receivable" BO_ 2365573879 "True";
BA_ "Sendable" BO_ 2365573879 "True";
BA_ "GenMsgCycleTime" BO_ 2566898935 100;
BA_ "Receivable" BO_ 2566898935 "True";
BA_ "Sendable" BO_ 2566898935 "True";
BA_ "GenMsgCycleTime" BO_ 2365572087 10;
BA_ "Receivable" BO_ 2365572087 "True";
BA_ "Sendable" BO_ 2365572087 "True";
BA_ "GenMsgCycleTime" BO_ 2566893815 100;
BA_ "Receivable" BO_ 2566893815 "True";
BA_ "Sendable" BO_ 2566893815 "True";
BA_ "GenMsgCycleTime" BO_ 2365571831 100;
BA_ "Receivable" BO_ 2365571831 "True";
BA_ "Sendable" BO_ 2365571831 "True";
BA_ "GenMsgCycleTime" BO_ 2634008567 100;
BA_ "Receivable" BO_ 2634008567 "True";
BA_ "Sendable" BO_ 2634008567 "True";
BA_ "GenMsgCycleTime" BO_ 2634008823 100;
BA_ "Receivable" BO_ 2634008823 "True";
BA_ "Sendable" BO_ 2634008823 "True";
BA_ "GenMsgCycleTime" BO_ 2634009335 100;
BA_ "Receivable" BO_ 2634009335 "True";
BA_ "Sendable" BO_ 2634009335 "True";
BA_ "GenMsgCycleTime" BO_ 2634009847 100;
BA_ "Receivable" BO_ 2634009847 "True";
BA_ "Sendable" BO_ 2634009847 "True";
BA_ "GenMsgCycleTime" BO_ 2365571575 100;
BA_ "Receivable" BO_ 2365571575 "True";
BA_ "Sendable" BO_ 2365571575 "True";
BA_ "GenMsgCycleTime" BO_ 2566902775 100;
BA_ "Receivable" BO_ 2566902775 "True";
BA_ "Sendable" BO_ 2566902775 "True";
BA_ "GenMsgCycleTime" BO_ 2566903031 100;
BA_ "Receivable" BO_ 2566903031 "True";
BA_ "Sendable" BO_ 2566903031 "True";
BA_ "GenMsgCycleTime" BO_ 2566903287 100;
BA_ "Receivable" BO_ 2566903287 "True";
BA_ "Sendable" BO_ 2566903287 "True";
BA_ "GenMsgCycleTime" BO_ 2566894071 1000;
BA_ "Receivable" BO_ 2566894071 "True";
BA_ "Sendable" BO_ 2566894071 "True";
BA_ "GenMsgCycleTime" BO_ 2566894327 1000;
BA_ "Receivable" BO_ 2566894327 "True";
BA_ "Sendable" BO_ 2566894327 "True";
BA_ "GenMsgCycleTime" BO_ 2566894583 1000;
BA_ "Receivable" BO_ 2566894583 "True";
BA_ "Sendable" BO_ 2566894583 "True";
BA_ "GenMsgCycleTime" BO_ 2566894839 1000;
BA_ "Receivable" BO_ 2566894839 "True";
BA_ "Sendable" BO_ 2566894839 "True";
BA_ "GenMsgCycleTime" BO_ 2566895095 100;
BA_ "Receivable" BO_ 2566895095 "True";
BA_ "Sendable" BO_ 2566895095 "True";
BA_ "GenMsgCycleTime" BO_ 2566895351 100;
BA_ "Receivable" BO_ 2566895351 "True";
BA_ "Sendable" BO_ 2566895351 "True";
BA_ "GenMsgCycleTime" BO_ 2566895607 100;
BA_ "Receivable" BO_ 2566895607 "True";
BA_ "Sendable" BO_ 2566895607 "True";
BA_ "LongName" SG_ 2649702903 Meta1028 "Meta";
BA_ "LongName" SG_ 2649702903 ReadParam_status1028 "ReadParam_status";
BA_ "LongName" SG_ 2649702903 TempInvCurrent "Temporary Inverter Current";
BA_ "LongName" SG_ 2649702903 Meta1029 "Meta";
BA_ "LongName" SG_ 2649702903 ReadParam_status1029 "ReadParam_status";
BA_ "LongName" SG_ 2649702903 Mx1CycleLimit "Mx1 Cycle Limit";
BA_ "LongName" SG_ 2649702903 Meta1030 "Meta";
BA_ "LongName" SG_ 2649702903 ReadParam_status1030 "ReadParam_status";
BA_ "LongName" SG_ 2649702903 Mx2CyclesLimit "Mx2 Cycles Limit";
BA_ "LongName" SG_ 2649702903 Meta1031 "Meta";
BA_ "LongName" SG_ 2649702903 ReadParam_status1031 "ReadParam_status";
BA_ "LongName" SG_ 2649702903 K1CyclesLimit "K1 Cycles Limit";
BA_ "LongName" SG_ 2649702903 Meta1032 "Meta";
BA_ "LongName" SG_ 2649702903 ReadParam_status1032 "ReadParam_status";
BA_ "LongName" SG_ 2649702903 K2CyclesLimit "K2 Cycles Limit";
BA_ "LongName" SG_ 2649702903 Meta1033 "Meta";
BA_ "LongName" SG_ 2649702903 ReadParam_status1033 "ReadParam_status";
BA_ "LongName" SG_ 2649702903 MX1CycleCount "MX1 Cycle Count";
BA_ "LongName" SG_ 2649702903 Meta1034 "Meta";
BA_ "LongName" SG_ 2649702903 ReadParam_status1034 "ReadParam_status";
BA_ "LongName" SG_ 2649702903 MX2CycleCount "MX2 Cycle Count";
BA_ "LongName" SG_ 2649702903 Meta1035 "Meta";
BA_ "LongName" SG_ 2649702903 ReadParam_status1035 "ReadParam_status";
BA_ "LongName" SG_ 2649702903 K1CycleCount "K1 Cycle Count";
BA_ "LongName" SG_ 2649702903 Meta1036 "Meta";
BA_ "LongName" SG_ 2649702903 ReadParam_status1036 "ReadParam_status";
BA_ "LongName" SG_ 2649702903 K2CycleCount "K2 Cycle Count";
BA_ "LongName" SG_ 2649702903 Meta1037 "Meta";
BA_ "LongName" SG_ 2649702903 ReadParam_status1037 "ReadParam_status";
BA_ "LongName" SG_ 2649702903 MX1DIIndex "MX1 DI Index";
BA_ "LongName" SG_ 2649702903 MX2DIIndex "MX2 DI Index";
BA_ "LongName" SG_ 2649702903 K1DIIndex "K1 DI Index";
BA_ "LongName" SG_ 2649702903 K2DIIndex "K2 DI Index";
BA_ "LongName" SG_ 2649702903 Meta1038 "Meta";
BA_ "LongName" SG_ 2649702903 ReadParam_status1038 "ReadParam_status";
BA_ "LongName" SG_ 2649702903 DO5Command "DO5Command";
BA_ "LongName" SG_ 2649702903 DO5Controller "DO5Controller";
BA_ "LongName" SG_ 2649702903 InvertDI6 "InvertDI6";
BA_ "LongName" SG_ 2649702903 InvertDI7 "InvertDI7";
BA_ "LongName" SG_ 2649702903 InvertDI8 "InvertDI8";
BA_ "LongName" SG_ 2649702903 InvertDI9 "InvertDI9";
BA_ "LongName" SG_ 2649702903 InvertDO5 "InvertDO5";
BA_ "LongName" SG_ 2649702903 Meta1039 "Meta";
BA_ "LongName" SG_ 2649702903 ReadParam_status1039 "ReadParam_status";
BA_ "LongName" SG_ 2649702903 ExternalInhibitFault "External Inhibit Fault";
BA_ "LongName" SG_ 2649702903 ExternalInhibitState "External Inhibit State";
BA_ "LongName" SG_ 2649702903 Meta1040 "Meta";
BA_ "LongName" SG_ 2649702903 ReadParam_status1040 "ReadParam_status";
BA_ "LongName" SG_ 2649702903 enable3 "enable";
BA_ "DisplayDecimalPlaces" SG_ 2649702903 forceTime 1;
BA_ "GenSigStartValue" SG_ 2649702903 forceTime 2.0;
BA_ "LongName" SG_ 2649702903 forceTime "force enable time";
BA_ "DisplayDecimalPlaces" SG_ 2649702903 waitTime 1;
BA_ "GenSigStartValue" SG_ 2649702903 waitTime 4.0;
BA_ "LongName" SG_ 2649702903 waitTime "wait time";
BA_ "LongName" SG_ 2649702903 Meta1041 "Meta";
BA_ "LongName" SG_ 2649702903 ReadParam_status1041 "ReadParam_status";
BA_ "DisplayDecimalPlaces" SG_ 2649702903 inhibitTime 1;
BA_ "GenSigStartValue" SG_ 2649702903 inhibitTime 2000.0;
BA_ "LongName" SG_ 2649702903 inhibitTime "inhibit time";
BA_ "LongName" SG_ 2649702903 enableAutoSync "enable auto synchronize";
BA_ "DisplayDecimalPlaces" SG_ 2649702903 autoSyncTime 1;
BA_ "LongName" SG_ 2649702903 autoSyncTime "auto sync time";
BA_ "LongName" SG_ 2649702903 Meta1042 "Meta";
BA_ "LongName" SG_ 2649702903 ReadParam_status1042 "ReadParam_status";
BA_ "DisplayDecimalPlaces" SG_ 2649702903 FilterTau 3;
BA_ "GenSigStartValue" SG_ 2649702903 FilterTau 10;
BA_ "LongName" SG_ 2649702903 FilterTau "FilterTau";
BA_ "LongName" SG_ 2649702903 Meta1043 "Meta";
BA_ "LongName" SG_ 2649702903 ReadParam_status1043 "ReadParam_status";
BA_ "LongName" SG_ 2649702903 ActiveInterface "Active Interface";
BA_ "LongName" SG_ 2649702903 Meta1044 "Meta";
BA_ "LongName" SG_ 2649702903 ReadParam_status1044 "ReadParam_status";
BA_ "DisplayDecimalPlaces" SG_ 2649702903 MODBUSTimeout 2;
BA_ "GenSigStartValue" SG_ 2649702903 MODBUSTimeout 15.00;
BA_ "LongName" SG_ 2649702903 MODBUSTimeout "MODBUS Timeout";
BA_ "LongName" SG_ 2649702903 Meta1045 "Meta";
BA_ "LongName" SG_ 2649702903 ReadParam_status1045 "ReadParam_status";
BA_ "DisplayDecimalPlaces" SG_ 2649702903 stopIRamp 1;
BA_ "GenSigStartValue" SG_ 2649702903 stopIRamp 600.0;
BA_ "LongName" SG_ 2649702903 stopIRamp "stopIRamp";
BA_ "LongName" SG_ 2649702903 Meta1046 "Meta";
BA_ "LongName" SG_ 2649702903 ReadParam_status1046 "ReadParam_status";
BA_ "DisplayDecimalPlaces" SG_ 2649702903 propGain 3;
BA_ "GenSigStartValue" SG_ 2649702903 propGain 0.01;
BA_ "LongName" SG_ 2649702903 propGain "propGain";
BA_ "DisplayDecimalPlaces" SG_ 2649702903 intGain 3;
BA_ "GenSigStartValue" SG_ 2649702903 intGain 0.2;
BA_ "LongName" SG_ 2649702903 intGain "intGain";
BA_ "DisplayDecimalPlaces" SG_ 2649702903 antiWupGain 1;
BA_ "GenSigStartValue" SG_ 2649702903 antiWupGain 1.0;
BA_ "LongName" SG_ 2649702903 antiWupGain "antiWupGain";
BA_ "LongName" SG_ 2649702903 Meta1047 "Meta";
BA_ "LongName" SG_ 2649702903 ReadParam_status1047 "ReadParam_status";
BA_ "DisplayDecimalPlaces" SG_ 2649702903 vMeasFilt_Tc 3;
BA_ "GenSigStartValue" SG_ 2649702903 vMeasFilt_Tc 0.02;
BA_ "LongName" SG_ 2649702903 vMeasFilt_Tc "vMeasFilt_Tc";
BA_ "DisplayDecimalPlaces" SG_ 2649702903 vRefFilt_Tc 3;
BA_ "GenSigStartValue" SG_ 2649702903 vRefFilt_Tc 0.2;
BA_ "LongName" SG_ 2649702903 vRefFilt_Tc "vRefFilt_Tc";
BA_ "LongName" SG_ 2649702903 Meta1048 "Meta";
BA_ "LongName" SG_ 2649702903 ReadParam_status1048 "ReadParam_status";
BA_ "DisplayDecimalPlaces" SG_ 2649702903 slope0 1;
BA_ "GenSigStartValue" SG_ 2649702903 slope0 15.0;
BA_ "LongName" SG_ 2649702903 slope0 "slope";
BA_ "DisplayDecimalPlaces" SG_ 2649702903 deadband0 1;
BA_ "GenSigStartValue" SG_ 2649702903 deadband0 10.0;
BA_ "LongName" SG_ 2649702903 deadband0 "deadband";
BA_ "DisplayDecimalPlaces" SG_ 2649702903 limit1 1;
BA_ "LongName" SG_ 2649702903 limit1 "limit";
BA_ "LongName" SG_ 2649702903 Meta1049 "Meta";
BA_ "LongName" SG_ 2649702903 ReadParam_status1049 "ReadParam_status";
BA_ "DisplayDecimalPlaces" SG_ 2649702903 fMeasFilt_Tc 3;
BA_ "GenSigStartValue" SG_ 2649702903 fMeasFilt_Tc 0.02;
BA_ "LongName" SG_ 2649702903 fMeasFilt_Tc "fMeasFilt_Tc";
BA_ "DisplayDecimalPlaces" SG_ 2649702903 fRefFilt_Tc 3;
BA_ "GenSigStartValue" SG_ 2649702903 fRefFilt_Tc 0.2;
BA_ "LongName" SG_ 2649702903 fRefFilt_Tc "fRefFilt_Tc";
BA_ "LongName" SG_ 2649702903 Meta1050 "Meta";
BA_ "LongName" SG_ 2649702903 ReadParam_status1050 "ReadParam_status";
BA_ "DisplayDecimalPlaces" SG_ 2649702903 slope1 1;
BA_ "GenSigStartValue" SG_ 2649702903 slope1 100.0;
BA_ "LongName" SG_ 2649702903 slope1 "slope";
BA_ "DisplayDecimalPlaces" SG_ 2649702903 deadband1 3;
BA_ "GenSigStartValue" SG_ 2649702903 deadband1 0.5;
BA_ "LongName" SG_ 2649702903 deadband1 "deadband";
BA_ "DisplayDecimalPlaces" SG_ 2649702903 limit2 1;
BA_ "LongName" SG_ 2649702903 limit2 "limit";
BA_ "LongName" SG_ 2649702903 Meta1051 "Meta";
BA_ "LongName" SG_ 2649702903 ReadParam_status1051 "ReadParam_status";
BA_ "DisplayDecimalPlaces" SG_ 2649702903 fMeasDerFilt_Tc 3;
BA_ "GenSigStartValue" SG_ 2649702903 fMeasDerFilt_Tc 0.02;
BA_ "LongName" SG_ 2649702903 fMeasDerFilt_Tc "fMeasDerFilt_Tc";
BA_ "LongName" SG_ 2649702903 Meta1052 "Meta";
BA_ "LongName" SG_ 2649702903 ReadParam_status1052 "ReadParam_status";
BA_ "DisplayDecimalPlaces" SG_ 2649702903 gain 2;
BA_ "LongName" SG_ 2649702903 gain "gain";
BA_ "DisplayDecimalPlaces" SG_ 2649702903 deadband2 1;
BA_ "GenSigStartValue" SG_ 2649702903 deadband2 5.0;
BA_ "LongName" SG_ 2649702903 deadband2 "deadband";
BA_ "LongName" SG_ 2649702903 Meta1053 "Meta";
BA_ "LongName" SG_ 2649702903 ReadParam_status1053 "ReadParam_status";
BA_ "GenSigStartValue" SG_ 2649702903 VI_comp_enable 1;
BA_ "LongName" SG_ 2649702903 VI_comp_enable "VI_comp_enable";
BA_ "DisplayDecimalPlaces" SG_ 2649702903 blackStartVRamp 1;
BA_ "LongName" SG_ 2649702903 blackStartVRamp "blackStartVRamp";
BA_ "LongName" SG_ 2649702903 Meta1054 "Meta";
BA_ "LongName" SG_ 2649702903 ReadParam_status1054 "ReadParam_status";
BA_ "DisplayDecimalPlaces" SG_ 2649702903 vLimMax 1;
BA_ "LongName" SG_ 2649702903 vLimMax "vLimMax";
BA_ "DisplayDecimalPlaces" SG_ 2649702903 vLimMin 1;
BA_ "LongName" SG_ 2649702903 vLimMin "vLimMin";
BA_ "LongName" SG_ 2649702903 Meta1055 "Meta";
BA_ "LongName" SG_ 2649702903 ReadParam_status1055 "ReadParam_status";
BA_ "DisplayDecimalPlaces" SG_ 2649702903 fLimMax 2;
BA_ "GenSigStartValue" SG_ 2649702903 fLimMax 85.0;
BA_ "LongName" SG_ 2649702903 fLimMax "fLimMax";
BA_ "DisplayDecimalPlaces" SG_ 2649702903 fLimMin 2;
BA_ "LongName" SG_ 2649702903 fLimMin "fLimMin";
BA_ "LongName" SG_ 2649702903 Meta1056 "Meta";
BA_ "LongName" SG_ 2649702903 ReadParam_status1056 "ReadParam_status";
BA_ "DisplayDecimalPlaces" SG_ 2649702903 vDroop 2;
BA_ "GenSigStartValue" SG_ 2649702903 vDroop 5.0;
BA_ "LongName" SG_ 2649702903 vDroop "vDroop";
BA_ "DisplayDecimalPlaces" SG_ 2649702903 fDroop 2;
BA_ "GenSigStartValue" SG_ 2649702903 fDroop 1.0;
BA_ "LongName" SG_ 2649702903 fDroop "fDroop";
BA_ "LongName" SG_ 2649702903 Meta1057 "Meta";
BA_ "LongName" SG_ 2649702903 ReadParam_status1057 "ReadParam_status";
BA_ "DisplayDecimalPlaces" SG_ 2649702903 vDeadband 1;
BA_ "LongName" SG_ 2649702903 vDeadband "vDeadband";
BA_ "DisplayDecimalPlaces" SG_ 2649702903 fDeadband 3;
BA_ "LongName" SG_ 2649702903 fDeadband "fDeadband";
BA_ "LongName" SG_ 2649702903 Meta1058 "Meta";
BA_ "LongName" SG_ 2649702903 ReadParam_status1058 "ReadParam_status";
BA_ "DisplayDecimalPlaces" SG_ 2649702903 avr_propGain 1;
BA_ "GenSigStartValue" SG_ 2649702903 avr_propGain 20.0;
BA_ "LongName" SG_ 2649702903 avr_propGain "avr_propGain";
BA_ "DisplayDecimalPlaces" SG_ 2649702903 avr_intGain 3;
BA_ "GenSigStartValue" SG_ 2649702903 avr_intGain 0.7;
BA_ "LongName" SG_ 2649702903 avr_intGain "avr_intGain";
BA_ "DisplayDecimalPlaces" SG_ 2649702903 avr_antiWupGain 1;
BA_ "GenSigStartValue" SG_ 2649702903 avr_antiWupGain 50.000;
BA_ "LongName" SG_ 2649702903 avr_antiWupGain "avr_antiWupGain";
BA_ "LongName" SG_ 2649702903 Meta1059 "Meta";
BA_ "LongName" SG_ 2649702903 ReadParam_status1059 "ReadParam_status";
BA_ "DisplayDecimalPlaces" SG_ 2649702903 gov_propGain 1;
BA_ "GenSigStartValue" SG_ 2649702903 gov_propGain 60.0;
BA_ "LongName" SG_ 2649702903 gov_propGain "gov_propGain";
BA_ "DisplayDecimalPlaces" SG_ 2649702903 gov_intGain 3;
BA_ "GenSigStartValue" SG_ 2649702903 gov_intGain 0.5;
BA_ "LongName" SG_ 2649702903 gov_intGain "gov_intGain";
BA_ "DisplayDecimalPlaces" SG_ 2649702903 gov_antiWupGain 1;
BA_ "GenSigStartValue" SG_ 2649702903 gov_antiWupGain 5000.000;
BA_ "LongName" SG_ 2649702903 gov_antiWupGain "gov_antiWupGain";
BA_ "LongName" SG_ 2649702903 Meta1060 "Meta";
BA_ "LongName" SG_ 2649702903 ReadParam_status1060 "ReadParam_status";
BA_ "DisplayDecimalPlaces" SG_ 2649702903 var_propGain 3;
BA_ "LongName" SG_ 2649702903 var_propGain "var_propGain";
BA_ "DisplayDecimalPlaces" SG_ 2649702903 var_intGain 3;
BA_ "GenSigStartValue" SG_ 2649702903 var_intGain 0.5;
BA_ "LongName" SG_ 2649702903 var_intGain "var_intGain";
BA_ "DisplayDecimalPlaces" SG_ 2649702903 var_antiWupGain 1;
BA_ "GenSigStartValue" SG_ 2649702903 var_antiWupGain 5000.000;
BA_ "LongName" SG_ 2649702903 var_antiWupGain "var_antiWupGain";
BA_ "LongName" SG_ 2649702903 Meta1061 "Meta";
BA_ "LongName" SG_ 2649702903 ReadParam_status1061 "ReadParam_status";
BA_ "DisplayDecimalPlaces" SG_ 2649702903 vin_damp 3;
BA_ "GenSigStartValue" SG_ 2649702903 vin_damp 0.001;
BA_ "LongName" SG_ 2649702903 vin_damp "vin_damp";
BA_ "DisplayDecimalPlaces" SG_ 2649702903 vin_H_sec 3;
BA_ "GenSigStartValue" SG_ 2649702903 vin_H_sec 2.5;
BA_ "LongName" SG_ 2649702903 vin_H_sec "vin_H_sec";
BA_ "DisplayDecimalPlaces" SG_ 2649702903 vin_antiWupGain 1;
BA_ "GenSigStartValue" SG_ 2649702903 vin_antiWupGain 5000.000;
BA_ "LongName" SG_ 2649702903 vin_antiWupGain "vin_antiWupGain";
BA_ "LongName" SG_ 2649702903 Meta1062 "Meta";
BA_ "LongName" SG_ 2649702903 ReadParam_status1062 "ReadParam_status";
BA_ "DisplayDecimalPlaces" SG_ 2649702903 block_vErr_pct 2;
BA_ "GenSigStartValue" SG_ 2649702903 block_vErr_pct 25.000;
BA_ "LongName" SG_ 2649702903 block_vErr_pct "block_vErr_pct";
BA_ "DisplayDecimalPlaces" SG_ 2649702903 block_qErr_pct 2;
BA_ "GenSigStartValue" SG_ 2649702903 block_qErr_pct 10.000;
BA_ "LongName" SG_ 2649702903 block_qErr_pct "block_qErr_pct";
BA_ "DisplayDecimalPlaces" SG_ 2649702903 block_onDelay_ms 1;
BA_ "GenSigStartValue" SG_ 2649702903 block_onDelay_ms 30.000;
BA_ "LongName" SG_ 2649702903 block_onDelay_ms "block_onDelay_ms";
BA_ "LongName" SG_ 2649702903 Meta1063 "Meta";
BA_ "LongName" SG_ 2649702903 ReadParam_status1063 "ReadParam_status";
BA_ "DisplayDecimalPlaces" SG_ 2649702903 ramp_power0 1;
BA_ "GenSigStartValue" SG_ 2649702903 ramp_power0 500.0;
BA_ "LongName" SG_ 2649702903 ramp_power0 "ramp_power";
BA_ "DisplayDecimalPlaces" SG_ 2649702903 ramp_time0 3;
BA_ "GenSigStartValue" SG_ 2649702903 ramp_time0 0.5;
BA_ "LongName" SG_ 2649702903 ramp_time0 "ramp_time";
BA_ "LongName" SG_ 2649702903 Meta1064 "Meta";
BA_ "LongName" SG_ 2649702903 ReadParam_status1064 "ReadParam_status";
BA_ "DisplayDecimalPlaces" SG_ 2649702903 ramp_power1 1;
BA_ "GenSigStartValue" SG_ 2649702903 ramp_power1 500.0;
BA_ "LongName" SG_ 2649702903 ramp_power1 "ramp_power";
BA_ "DisplayDecimalPlaces" SG_ 2649702903 ramp_time1 3;
BA_ "GenSigStartValue" SG_ 2649702903 ramp_time1 0.5;
BA_ "LongName" SG_ 2649702903 ramp_time1 "ramp_time";
BA_ "LongName" SG_ 2649702903 Meta1065 "Meta";
BA_ "LongName" SG_ 2649702903 ReadParam_status1065 "ReadParam_status";
BA_ "DisplayDecimalPlaces" SG_ 2649702903 vFilterTrPa 3;
BA_ "GenSigStartValue" SG_ 2649702903 vFilterTrPa 0.01;
BA_ "LongName" SG_ 2649702903 vFilterTrPa "vFilterTrPa";
BA_ "LongName" SG_ 2649702903 Meta1066 "Meta";
BA_ "LongName" SG_ 2649702903 ReadParam_status1066 "ReadParam_status";
BA_ "LongName" SG_ 2649702903 NumActivePoints24 "NumActivePoints";
BA_ "LongName" SG_ 2649702903 Meta1067 "Meta";
BA_ "LongName" SG_ 2649702903 ReadParam_status1067 "ReadParam_status";
BA_ "DisplayDecimalPlaces" SG_ 2649702903 _0148 1;
BA_ "LongName" SG_ 2649702903 _0148 "_01";
BA_ "DisplayDecimalPlaces" SG_ 2649702903 _0248 1;
BA_ "LongName" SG_ 2649702903 _0248 "_02";
BA_ "DisplayDecimalPlaces" SG_ 2649702903 _0348 1;
BA_ "LongName" SG_ 2649702903 _0348 "_03";
BA_ "LongName" SG_ 2649702903 Meta1068 "Meta";
BA_ "LongName" SG_ 2649702903 ReadParam_status1068 "ReadParam_status";
BA_ "DisplayDecimalPlaces" SG_ 2649702903 _0448 1;
BA_ "LongName" SG_ 2649702903 _0448 "_04";
BA_ "DisplayDecimalPlaces" SG_ 2649702903 _0548 1;
BA_ "LongName" SG_ 2649702903 _0548 "_05";
BA_ "DisplayDecimalPlaces" SG_ 2649702903 _0648 1;
BA_ "LongName" SG_ 2649702903 _0648 "_06";
BA_ "LongName" SG_ 2649702903 Meta1069 "Meta";
BA_ "LongName" SG_ 2649702903 ReadParam_status1069 "ReadParam_status";
BA_ "DisplayDecimalPlaces" SG_ 2649702903 _0748 1;
BA_ "LongName" SG_ 2649702903 _0748 "_07";
BA_ "DisplayDecimalPlaces" SG_ 2649702903 _0848 1;
BA_ "LongName" SG_ 2649702903 _0848 "_08";
BA_ "DisplayDecimalPlaces" SG_ 2649702903 _0948 1;
BA_ "LongName" SG_ 2649702903 _0948 "_09";
BA_ "LongName" SG_ 2649702903 Meta1070 "Meta";
BA_ "LongName" SG_ 2649702903 ReadParam_status1070 "ReadParam_status";
BA_ "DisplayDecimalPlaces" SG_ 2649702903 _1048 1;
BA_ "LongName" SG_ 2649702903 _1048 "_10";
BA_ "DisplayDecimalPlaces" SG_ 2649702903 _1148 1;
BA_ "LongName" SG_ 2649702903 _1148 "_11";
BA_ "DisplayDecimalPlaces" SG_ 2649702903 _1248 1;
BA_ "LongName" SG_ 2649702903 _1248 "_12";
BA_ "LongName" SG_ 2649702903 Meta1071 "Meta";
BA_ "LongName" SG_ 2649702903 ReadParam_status1071 "ReadParam_status";
BA_ "DisplayDecimalPlaces" SG_ 2649702903 _1348 1;
BA_ "LongName" SG_ 2649702903 _1348 "_13";
BA_ "DisplayDecimalPlaces" SG_ 2649702903 _1448 1;
BA_ "LongName" SG_ 2649702903 _1448 "_14";
BA_ "DisplayDecimalPlaces" SG_ 2649702903 _1548 1;
BA_ "LongName" SG_ 2649702903 _1548 "_15";
BA_ "LongName" SG_ 2649702903 Meta1072 "Meta";
BA_ "LongName" SG_ 2649702903 ReadParam_status1072 "ReadParam_status";
BA_ "DisplayDecimalPlaces" SG_ 2649702903 _1648 1;
BA_ "LongName" SG_ 2649702903 _1648 "_16";
BA_ "DisplayDecimalPlaces" SG_ 2649702903 _1748 1;
BA_ "LongName" SG_ 2649702903 _1748 "_17";
BA_ "DisplayDecimalPlaces" SG_ 2649702903 _1848 1;
BA_ "LongName" SG_ 2649702903 _1848 "_18";
BA_ "LongName" SG_ 2649702903 Meta1073 "Meta";
BA_ "LongName" SG_ 2649702903 ReadParam_status1073 "ReadParam_status";
BA_ "DisplayDecimalPlaces" SG_ 2649702903 _1948 1;
BA_ "LongName" SG_ 2649702903 _1948 "_19";
BA_ "DisplayDecimalPlaces" SG_ 2649702903 _2048 1;
BA_ "LongName" SG_ 2649702903 _2048 "_20";
BA_ "LongName" SG_ 2649702903 Meta1074 "Meta";
BA_ "LongName" SG_ 2649702903 ReadParam_status1074 "ReadParam_status";
BA_ "DisplayDecimalPlaces" SG_ 2649702903 _0149 1;
BA_ "LongName" SG_ 2649702903 _0149 "_01";
BA_ "DisplayDecimalPlaces" SG_ 2649702903 _0249 1;
BA_ "LongName" SG_ 2649702903 _0249 "_02";
BA_ "DisplayDecimalPlaces" SG_ 2649702903 _0349 1;
BA_ "LongName" SG_ 2649702903 _0349 "_03";
BA_ "LongName" SG_ 2649702903 Meta1075 "Meta";
BA_ "LongName" SG_ 2649702903 ReadParam_status1075 "ReadParam_status";
BA_ "DisplayDecimalPlaces" SG_ 2649702903 _0449 1;
BA_ "LongName" SG_ 2649702903 _0449 "_04";
BA_ "DisplayDecimalPlaces" SG_ 2649702903 _0549 1;
BA_ "LongName" SG_ 2649702903 _0549 "_05";
BA_ "DisplayDecimalPlaces" SG_ 2649702903 _0649 1;
BA_ "LongName" SG_ 2649702903 _0649 "_06";
BA_ "LongName" SG_ 2649702903 Meta1076 "Meta";
BA_ "LongName" SG_ 2649702903 ReadParam_status1076 "ReadParam_status";
BA_ "DisplayDecimalPlaces" SG_ 2649702903 _0749 1;
BA_ "LongName" SG_ 2649702903 _0749 "_07";
BA_ "DisplayDecimalPlaces" SG_ 2649702903 _0849 1;
BA_ "LongName" SG_ 2649702903 _0849 "_08";
BA_ "DisplayDecimalPlaces" SG_ 2649702903 _0949 1;
BA_ "LongName" SG_ 2649702903 _0949 "_09";
BA_ "LongName" SG_ 2649702903 Meta1077 "Meta";
BA_ "LongName" SG_ 2649702903 ReadParam_status1077 "ReadParam_status";
BA_ "DisplayDecimalPlaces" SG_ 2649702903 _1049 1;
BA_ "LongName" SG_ 2649702903 _1049 "_10";
BA_ "DisplayDecimalPlaces" SG_ 2649702903 _1149 1;
BA_ "LongName" SG_ 2649702903 _1149 "_11";
BA_ "DisplayDecimalPlaces" SG_ 2649702903 _1249 1;
BA_ "LongName" SG_ 2649702903 _1249 "_12";
BA_ "LongName" SG_ 2649702903 Meta1078 "Meta";
BA_ "LongName" SG_ 2649702903 ReadParam_status1078 "ReadParam_status";
BA_ "DisplayDecimalPlaces" SG_ 2649702903 _1349 1;
BA_ "LongName" SG_ 2649702903 _1349 "_13";
BA_ "DisplayDecimalPlaces" SG_ 2649702903 _1449 1;
BA_ "LongName" SG_ 2649702903 _1449 "_14";
BA_ "DisplayDecimalPlaces" SG_ 2649702903 _1549 1;
BA_ "LongName" SG_ 2649702903 _1549 "_15";
BA_ "LongName" SG_ 2649702903 Meta1079 "Meta";
BA_ "LongName" SG_ 2649702903 ReadParam_status1079 "ReadParam_status";
BA_ "DisplayDecimalPlaces" SG_ 2649702903 _1649 1;
BA_ "LongName" SG_ 2649702903 _1649 "_16";
BA_ "DisplayDecimalPlaces" SG_ 2649702903 _1749 1;
BA_ "LongName" SG_ 2649702903 _1749 "_17";
BA_ "DisplayDecimalPlaces" SG_ 2649702903 _1849 1;
BA_ "LongName" SG_ 2649702903 _1849 "_18";
BA_ "LongName" SG_ 2649702903 Meta1080 "Meta";
BA_ "LongName" SG_ 2649702903 ReadParam_status1080 "ReadParam_status";
BA_ "DisplayDecimalPlaces" SG_ 2649702903 _1949 1;
BA_ "LongName" SG_ 2649702903 _1949 "_19";
BA_ "DisplayDecimalPlaces" SG_ 2649702903 _2049 1;
BA_ "LongName" SG_ 2649702903 _2049 "_20";
BA_ "LongName" SG_ 2649702903 Meta1081 "Meta";
BA_ "LongName" SG_ 2649702903 ReadParam_status1081 "ReadParam_status";
BA_ "LongName" SG_ 2649702903 RampRateDecrement8 "RampRateDecrement";
BA_ "LongName" SG_ 2649702903 RampRateIncrement8 "RampRateIncrement";
BA_ "LongName" SG_ 2649702903 Meta1082 "Meta";
BA_ "LongName" SG_ 2649702903 ReadParam_status1082 "ReadParam_status";
BA_ "LongName" SG_ 2649702903 NumActivePoints25 "NumActivePoints";
BA_ "LongName" SG_ 2649702903 Meta1083 "Meta";
BA_ "LongName" SG_ 2649702903 ReadParam_status1083 "ReadParam_status";
BA_ "DisplayDecimalPlaces" SG_ 2649702903 _0150 1;
BA_ "LongName" SG_ 2649702903 _0150 "_01";
BA_ "DisplayDecimalPlaces" SG_ 2649702903 _0250 1;
BA_ "LongName" SG_ 2649702903 _0250 "_02";
BA_ "DisplayDecimalPlaces" SG_ 2649702903 _0350 1;
BA_ "LongName" SG_ 2649702903 _0350 "_03";
BA_ "LongName" SG_ 2649702903 Meta1084 "Meta";
BA_ "LongName" SG_ 2649702903 ReadParam_status1084 "ReadParam_status";
BA_ "DisplayDecimalPlaces" SG_ 2649702903 _0450 1;
BA_ "LongName" SG_ 2649702903 _0450 "_04";
BA_ "DisplayDecimalPlaces" SG_ 2649702903 _0550 1;
BA_ "LongName" SG_ 2649702903 _0550 "_05";
BA_ "DisplayDecimalPlaces" SG_ 2649702903 _0650 1;
BA_ "LongName" SG_ 2649702903 _0650 "_06";
BA_ "LongName" SG_ 2649702903 Meta1085 "Meta";
BA_ "LongName" SG_ 2649702903 ReadParam_status1085 "ReadParam_status";
BA_ "DisplayDecimalPlaces" SG_ 2649702903 _0750 1;
BA_ "LongName" SG_ 2649702903 _0750 "_07";
BA_ "DisplayDecimalPlaces" SG_ 2649702903 _0850 1;
BA_ "LongName" SG_ 2649702903 _0850 "_08";
BA_ "DisplayDecimalPlaces" SG_ 2649702903 _0950 1;
BA_ "LongName" SG_ 2649702903 _0950 "_09";
BA_ "LongName" SG_ 2649702903 Meta1086 "Meta";
BA_ "LongName" SG_ 2649702903 ReadParam_status1086 "ReadParam_status";
BA_ "DisplayDecimalPlaces" SG_ 2649702903 _1050 1;
BA_ "LongName" SG_ 2649702903 _1050 "_10";
BA_ "DisplayDecimalPlaces" SG_ 2649702903 _1150 1;
BA_ "LongName" SG_ 2649702903 _1150 "_11";
BA_ "DisplayDecimalPlaces" SG_ 2649702903 _1250 1;
BA_ "LongName" SG_ 2649702903 _1250 "_12";
BA_ "LongName" SG_ 2649702903 Meta1087 "Meta";
BA_ "LongName" SG_ 2649702903 ReadParam_status1087 "ReadParam_status";
BA_ "DisplayDecimalPlaces" SG_ 2649702903 _1350 1;
BA_ "LongName" SG_ 2649702903 _1350 "_13";
BA_ "DisplayDecimalPlaces" SG_ 2649702903 _1450 1;
BA_ "LongName" SG_ 2649702903 _1450 "_14";
BA_ "DisplayDecimalPlaces" SG_ 2649702903 _1550 1;
BA_ "LongName" SG_ 2649702903 _1550 "_15";
BA_ "LongName" SG_ 2649702903 Meta1088 "Meta";
BA_ "LongName" SG_ 2649702903 ReadParam_status1088 "ReadParam_status";
BA_ "DisplayDecimalPlaces" SG_ 2649702903 _1650 1;
BA_ "LongName" SG_ 2649702903 _1650 "_16";
BA_ "DisplayDecimalPlaces" SG_ 2649702903 _1750 1;
BA_ "LongName" SG_ 2649702903 _1750 "_17";
BA_ "DisplayDecimalPlaces" SG_ 2649702903 _1850 1;
BA_ "LongName" SG_ 2649702903 _1850 "_18";
BA_ "LongName" SG_ 2649702903 Meta1089 "Meta";
BA_ "LongName" SG_ 2649702903 ReadParam_status1089 "ReadParam_status";
BA_ "DisplayDecimalPlaces" SG_ 2649702903 _1950 1;
BA_ "LongName" SG_ 2649702903 _1950 "_19";
BA_ "DisplayDecimalPlaces" SG_ 2649702903 _2050 1;
BA_ "LongName" SG_ 2649702903 _2050 "_20";
BA_ "LongName" SG_ 2649702903 Meta1090 "Meta";
BA_ "LongName" SG_ 2649702903 ReadParam_status1090 "ReadParam_status";
BA_ "DisplayDecimalPlaces" SG_ 2649702903 _0151 1;
BA_ "LongName" SG_ 2649702903 _0151 "_01";
BA_ "DisplayDecimalPlaces" SG_ 2649702903 _0251 1;
BA_ "LongName" SG_ 2649702903 _0251 "_02";
BA_ "DisplayDecimalPlaces" SG_ 2649702903 _0351 1;
BA_ "LongName" SG_ 2649702903 _0351 "_03";
BA_ "LongName" SG_ 2649702903 Meta1091 "Meta";
BA_ "LongName" SG_ 2649702903 ReadParam_status1091 "ReadParam_status";
BA_ "DisplayDecimalPlaces" SG_ 2649702903 _0451 1;
BA_ "LongName" SG_ 2649702903 _0451 "_04";
BA_ "DisplayDecimalPlaces" SG_ 2649702903 _0551 1;
BA_ "LongName" SG_ 2649702903 _0551 "_05";
BA_ "DisplayDecimalPlaces" SG_ 2649702903 _0651 1;
BA_ "LongName" SG_ 2649702903 _0651 "_06";
BA_ "LongName" SG_ 2649702903 Meta1092 "Meta";
BA_ "LongName" SG_ 2649702903 ReadParam_status1092 "ReadParam_status";
BA_ "DisplayDecimalPlaces" SG_ 2649702903 _0751 1;
BA_ "LongName" SG_ 2649702903 _0751 "_07";
BA_ "DisplayDecimalPlaces" SG_ 2649702903 _0851 1;
BA_ "LongName" SG_ 2649702903 _0851 "_08";
BA_ "DisplayDecimalPlaces" SG_ 2649702903 _0951 1;
BA_ "LongName" SG_ 2649702903 _0951 "_09";
BA_ "LongName" SG_ 2649702903 Meta1093 "Meta";
BA_ "LongName" SG_ 2649702903 ReadParam_status1093 "ReadParam_status";
BA_ "DisplayDecimalPlaces" SG_ 2649702903 _1051 1;
BA_ "LongName" SG_ 2649702903 _1051 "_10";
BA_ "DisplayDecimalPlaces" SG_ 2649702903 _1151 1;
BA_ "LongName" SG_ 2649702903 _1151 "_11";
BA_ "DisplayDecimalPlaces" SG_ 2649702903 _1251 1;
BA_ "LongName" SG_ 2649702903 _1251 "_12";
BA_ "LongName" SG_ 2649702903 Meta1094 "Meta";
BA_ "LongName" SG_ 2649702903 ReadParam_status1094 "ReadParam_status";
BA_ "DisplayDecimalPlaces" SG_ 2649702903 _1351 1;
BA_ "LongName" SG_ 2649702903 _1351 "_13";
BA_ "DisplayDecimalPlaces" SG_ 2649702903 _1451 1;
BA_ "LongName" SG_ 2649702903 _1451 "_14";
BA_ "DisplayDecimalPlaces" SG_ 2649702903 _1551 1;
BA_ "LongName" SG_ 2649702903 _1551 "_15";
BA_ "LongName" SG_ 2649702903 Meta1095 "Meta";
BA_ "LongName" SG_ 2649702903 ReadParam_status1095 "ReadParam_status";
BA_ "DisplayDecimalPlaces" SG_ 2649702903 _1651 1;
BA_ "LongName" SG_ 2649702903 _1651 "_16";
BA_ "DisplayDecimalPlaces" SG_ 2649702903 _1751 1;
BA_ "LongName" SG_ 2649702903 _1751 "_17";
BA_ "DisplayDecimalPlaces" SG_ 2649702903 _1851 1;
BA_ "LongName" SG_ 2649702903 _1851 "_18";
BA_ "LongName" SG_ 2649702903 Meta1096 "Meta";
BA_ "LongName" SG_ 2649702903 ReadParam_status1096 "ReadParam_status";
BA_ "DisplayDecimalPlaces" SG_ 2649702903 _1951 1;
BA_ "LongName" SG_ 2649702903 _1951 "_19";
BA_ "DisplayDecimalPlaces" SG_ 2649702903 _2051 1;
BA_ "LongName" SG_ 2649702903 _2051 "_20";
BA_ "LongName" SG_ 2649702903 Meta1097 "Meta";
BA_ "LongName" SG_ 2649702903 ReadParam_status1097 "ReadParam_status";
BA_ "LongName" SG_ 2649702903 RampRateDecrement9 "RampRateDecrement";
BA_ "LongName" SG_ 2649702903 RampRateIncrement9 "RampRateIncrement";
BA_ "LongName" SG_ 2649702903 Meta1098 "Meta";
BA_ "LongName" SG_ 2649702903 ReadParam_status1098 "ReadParam_status";
BA_ "DisplayDecimalPlaces" SG_ 2649702903 phiAbs3 2;
BA_ "LongName" SG_ 2649702903 phiAbs3 "SimAcNetworkPhaseTrigSourceU : phiAbs";
BA_ "LongName" SG_ 2649702903 Meta1099 "Meta";
BA_ "LongName" SG_ 2649702903 ReadParam_status1099 "ReadParam_status";
BA_ "DisplayDecimalPlaces" SG_ 2649702903 phiAbs4 2;
BA_ "GenSigStartValue" SG_ 2649702903 phiAbs4 120;
BA_ "LongName" SG_ 2649702903 phiAbs4 "SimAcNetworkPhaseTrigSourceV : phiAbs";
BA_ "LongName" SG_ 2649702903 Meta1100 "Meta";
BA_ "LongName" SG_ 2649702903 ReadParam_status1100 "ReadParam_status";
BA_ "DisplayDecimalPlaces" SG_ 2649702903 phiAbs5 2;
BA_ "GenSigStartValue" SG_ 2649702903 phiAbs5 240;
BA_ "LongName" SG_ 2649702903 phiAbs5 "SimAcNetworkPhaseTrigSourceW : phiAbs";
BA_ "LongName" SG_ 2649702903 Meta1101 "Meta";
BA_ "LongName" SG_ 2649702903 ReadParam_status1101 "ReadParam_status";
BA_ "LongName" SG_ 2649702903 Trigger "SimAcNetworkTrigger : TriggerPhases";
BA_ "GenSigStartValue" SG_ 2649702903 allowWPhaseOV 1;
BA_ "LongName" SG_ 2649702903 allowWPhaseOV "SimAcNetworkTrigger : allowWPhaseOV";
BA_ "LongName" SG_ 2649702903 Delay "SimAcNetworkTrigger : Delay";
BA_ "LongName" SG_ 2649702903 Duration "SimAcNetworkTrigger : Duration";
BA_ "LongName" SG_ 2649702903 Meta1102 "Meta";
BA_ "LongName" SG_ 2649702903 ReadParam_status1102 "ReadParam_status";
BA_ "LongName" SG_ 2649702903 Enable8 "HzWattLimitEnable";
BA_ "DisplayDecimalPlaces" SG_ 2649702903 fFiltTau 2;
BA_ "GenSigStartValue" SG_ 2649702903 fFiltTau 5;
BA_ "LongName" SG_ 2649702903 fFiltTau "fFiltTau";
BA_ "LongName" SG_ 2649702903 Meta1103 "Meta";
BA_ "LongName" SG_ 2649702903 ReadParam_status1103 "ReadParam_status";
BA_ "DisplayDecimalPlaces" SG_ 2649702903 db_OF 3;
BA_ "GenSigStartValue" SG_ 2649702903 db_OF 0.036;
BA_ "LongName" SG_ 2649702903 db_OF "db_OF";
BA_ "DisplayDecimalPlaces" SG_ 2649702903 db_UF 3;
BA_ "GenSigStartValue" SG_ 2649702903 db_UF 0.036;
BA_ "LongName" SG_ 2649702903 db_UF "db_UF";
BA_ "LongName" SG_ 2649702903 Meta1104 "Meta";
BA_ "LongName" SG_ 2649702903 ReadParam_status1104 "ReadParam_status";
BA_ "DisplayDecimalPlaces" SG_ 2649702903 droop_OF 2;
BA_ "GenSigStartValue" SG_ 2649702903 droop_OF 0.05;
BA_ "LongName" SG_ 2649702903 droop_OF "droop_OF";
BA_ "DisplayDecimalPlaces" SG_ 2649702903 droop_UF 2;
BA_ "GenSigStartValue" SG_ 2649702903 droop_UF 0.05;
BA_ "LongName" SG_ 2649702903 droop_UF "droop_UF";
BA_ "LongName" SG_ 2649702903 Meta1105 "Meta";
BA_ "LongName" SG_ 2649702903 ReadParam_status1105 "ReadParam_status";
BA_ "LongName" SG_ 2649702903 LogDataEnable "LogDataEnable";
BA_ "LongName" SG_ 2649702903 Meta1106 "Meta";
BA_ "LongName" SG_ 2649702903 ReadParam_status1106 "ReadParam_status";
BA_ "LongName" SG_ 2649702903 RefMode "Reference mode";
BA_ "GenSigStartValue" SG_ 2649702903 AutoVrefFilterTimeConst 300.0;
BA_ "LongName" SG_ 2649702903 AutoVrefFilterTimeConst "Auto Vref Filter Time Const";
BA_ "GenSigStartValue" SG_ 2649702903 FixedVref 100;
BA_ "LongName" SG_ 2649702903 FixedVref "Fixed Vref";
BA_ "LongName" SG_ 2649702903 Meta1107 "Meta";
BA_ "LongName" SG_ 2649702903 ReadParam_status1107 "ReadParam_status";
BA_ "GenSigStartValue" SG_ 2649702903 kneePower1 100;
BA_ "LongName" SG_ 2649702903 kneePower1 "Knee Power 1";
BA_ "GenSigStartValue" SG_ 2649702903 kneePower2 -100;
BA_ "LongName" SG_ 2649702903 kneePower2 "Knee Power 2";
BA_ "LongName" SG_ 2649702903 Meta1108 "Meta";
BA_ "LongName" SG_ 2649702903 ReadParam_status1108 "ReadParam_status";
BA_ "DisplayDecimalPlaces" SG_ 2649702903 PtoP_gain 3;
BA_ "LongName" SG_ 2649702903 PtoP_gain "PtoP_gain";
BA_ "DisplayDecimalPlaces" SG_ 2649702903 PtoQ_gain 3;
BA_ "LongName" SG_ 2649702903 PtoQ_gain "PtoQ_gain";
BA_ "LongName" SG_ 2649702903 Meta1109 "Meta";
BA_ "LongName" SG_ 2649702903 ReadParam_status1109 "ReadParam_status";
BA_ "DisplayDecimalPlaces" SG_ 2649702903 QtoP_gain 3;
BA_ "LongName" SG_ 2649702903 QtoP_gain "QtoP_gain";
BA_ "DisplayDecimalPlaces" SG_ 2649702903 QtoQ_gain 3;
BA_ "LongName" SG_ 2649702903 QtoQ_gain "QtoQ_gain";
BA_ "LongName" SG_ 2649702903 Meta1110 "Meta";
BA_ "LongName" SG_ 2649702903 ReadParam_status1110 "ReadParam_status";
BA_ "DisplayDecimalPlaces" SG_ 2649702903 Pneg_Qpos0 1;
BA_ "LongName" SG_ 2649702903 Pneg_Qpos0 "Pneg_Qpos";
BA_ "DisplayDecimalPlaces" SG_ 2649702903 Pneg_Q00 1;
BA_ "LongName" SG_ 2649702903 Pneg_Q00 "Pneg_Q0";
BA_ "DisplayDecimalPlaces" SG_ 2649702903 Pneg_Qneg0 1;
BA_ "LongName" SG_ 2649702903 Pneg_Qneg0 "Pneg_Qneg";
BA_ "LongName" SG_ 2649702903 Meta1111 "Meta";
BA_ "LongName" SG_ 2649702903 ReadParam_status1111 "ReadParam_status";
BA_ "DisplayDecimalPlaces" SG_ 2649702903 P0_Qpos0 1;
BA_ "LongName" SG_ 2649702903 P0_Qpos0 "P0_Qpos";
BA_ "DisplayDecimalPlaces" SG_ 2649702903 P0_Qneg0 1;
BA_ "LongName" SG_ 2649702903 P0_Qneg0 "P0_Qneg";
BA_ "DisplayDecimalPlaces" SG_ 2649702903 MeaspointPref 1;
BA_ "GenSigStartValue" SG_ 2649702903 MeaspointPref 150;
BA_ "LongName" SG_ 2649702903 MeaspointPref "MeaspointPref";
BA_ "LongName" SG_ 2649702903 Meta1112 "Meta";
BA_ "LongName" SG_ 2649702903 ReadParam_status1112 "ReadParam_status";
BA_ "DisplayDecimalPlaces" SG_ 2649702903 Ppos_Qpos0 1;
BA_ "LongName" SG_ 2649702903 Ppos_Qpos0 "Ppos_Qpos";
BA_ "DisplayDecimalPlaces" SG_ 2649702903 Ppos_Q00 1;
BA_ "LongName" SG_ 2649702903 Ppos_Q00 "Ppos_Q0";
BA_ "DisplayDecimalPlaces" SG_ 2649702903 Ppos_Qneg0 1;
BA_ "LongName" SG_ 2649702903 Ppos_Qneg0 "Ppos_Qneg";
BA_ "LongName" SG_ 2649702903 Meta1113 "Meta";
BA_ "LongName" SG_ 2649702903 ReadParam_status1113 "ReadParam_status";
BA_ "DisplayDecimalPlaces" SG_ 2649702903 Pneg_Qpos1 1;
BA_ "LongName" SG_ 2649702903 Pneg_Qpos1 "Pneg_Qpos";
BA_ "DisplayDecimalPlaces" SG_ 2649702903 Pneg_Q01 1;
BA_ "LongName" SG_ 2649702903 Pneg_Q01 "Pneg_Q0";
BA_ "DisplayDecimalPlaces" SG_ 2649702903 Pneg_Qneg1 1;
BA_ "LongName" SG_ 2649702903 Pneg_Qneg1 "Pneg_Qneg";
BA_ "LongName" SG_ 2649702903 Meta1114 "Meta";
BA_ "LongName" SG_ 2649702903 ReadParam_status1114 "ReadParam_status";
BA_ "DisplayDecimalPlaces" SG_ 2649702903 P0_Qpos1 1;
BA_ "LongName" SG_ 2649702903 P0_Qpos1 "P0_Qpos";
BA_ "DisplayDecimalPlaces" SG_ 2649702903 P0_Qneg1 1;
BA_ "LongName" SG_ 2649702903 P0_Qneg1 "P0_Qneg";
BA_ "DisplayDecimalPlaces" SG_ 2649702903 MeaspointQref 1;
BA_ "GenSigStartValue" SG_ 2649702903 MeaspointQref 150;
BA_ "LongName" SG_ 2649702903 MeaspointQref "MeaspointQref";
BA_ "LongName" SG_ 2649702903 Meta1115 "Meta";
BA_ "LongName" SG_ 2649702903 ReadParam_status1115 "ReadParam_status";
BA_ "DisplayDecimalPlaces" SG_ 2649702903 Ppos_Qpos1 1;
BA_ "LongName" SG_ 2649702903 Ppos_Qpos1 "Ppos_Qpos";
BA_ "DisplayDecimalPlaces" SG_ 2649702903 Ppos_Q01 1;
BA_ "LongName" SG_ 2649702903 Ppos_Q01 "Ppos_Q0";
BA_ "DisplayDecimalPlaces" SG_ 2649702903 Ppos_Qneg1 1;
BA_ "LongName" SG_ 2649702903 Ppos_Qneg1 "Ppos_Qneg";
BA_ "LongName" SG_ 2582594039 CommandCounter0 "Raw : CommandCounter";
BA_ "LongName" SG_ 2582594039 CommandReturnCode0 "Raw : CommandReturnCode";
BA_ "LongName" SG_ 2582594039 CommandCounter1 "Connect : CommandCounter";
BA_ "LongName" SG_ 2582594039 CommandReturnCode1 "Connect : CommandReturnCode";
BA_ "LongName" SG_ 2582594039 CommandCounter2 "SetMTA : CommandCounter";
BA_ "LongName" SG_ 2582594039 CommandReturnCode2 "SetMTA : CommandReturnCode";
BA_ "LongName" SG_ 2582594039 CommandCounter3 "Upload : CommandCounter";
BA_ "LongName" SG_ 2582594039 CommandReturnCode3 "Upload : CommandReturnCode";
BA_ "LongName" SG_ 2582594039 Byte0 "Byte0";
BA_ "LongName" SG_ 2582594039 Byte1 "Byte1";
BA_ "LongName" SG_ 2582594039 Byte2 "Byte2";
BA_ "LongName" SG_ 2582594039 Byte3 "Byte3";
BA_ "LongName" SG_ 2582594039 Byte4 "Byte4";
BA_ "LongName" SG_ 2582594039 CommandCounter4 "Disconnect : CommandCounter";
BA_ "LongName" SG_ 2582594039 CommandReturnCode4 "Disconnect : CommandReturnCode";
BA_ "LongName" SG_ 2566902007 CurrentU "L1";
BA_ "LongName" SG_ 2566902007 CurrentV "L2";
BA_ "LongName" SG_ 2566902007 CurrentW "L3";
BA_ "LongName" SG_ 2566902263 VoltageU "L1";
BA_ "LongName" SG_ 2566902263 VoltageV "L2";
BA_ "LongName" SG_ 2566902263 VoltageW "L3";
BA_ "LongName" SG_ 2566902519 VoltageU "L1";
BA_ "LongName" SG_ 2566902519 VoltageV "L2";
BA_ "LongName" SG_ 2566902519 VoltageW "L3";
BA_ "LongName" SG_ 2634006775 NetworkVoltage "Remote V";
BA_ "LongName" SG_ 2634006775 NetworkFrequency "Remote Hz";
BA_ "LongName" SG_ 2634006775 PhaseSequence "Remote Sequence";
BA_ "LongName" SG_ 2634006775 VoltageDetected "Remote Voltage Detected";
BA_ "LongName" SG_ 2634006775 NetworkInSpec "Remote Voltage Nominal";
BA_ "LongName" SG_ 2365573879 RealPower_measured "Real Power";
BA_ "LongName" SG_ 2365573879 ReactivePower_measured "Reactive Power";
BA_ "LongName" SG_ 2365573879 ApparentPower_measured "Apparent Power";
BA_ "LongName" SG_ 2566898935 RealPower_echo "Real Power";
BA_ "LongName" SG_ 2566898935 ReactivePower_echo "Reactive Power";
BA_ "LongName" SG_ 2365572087 WarningClr_echo "Warning Clear";
BA_ "LongName" SG_ 2365572087 IslandReconnect_echo "Island Reconnect";
BA_ "LongName" SG_ 2365572087 ProtBusSequence "Protected Bus Status";
BA_ "LongName" SG_ 2365572087 FaultClr_echo "Fault Clear";
BA_ "LongName" SG_ 2365572087 Enable_echo "Enable";
BA_ "LongName" SG_ 2365572087 State "State";
BA_ "LongName" SG_ 2365572087 PowerCircuitEnabled "Power Circuit Enabled";
BA_ "LongName" SG_ 2365572087 PowerAvailDC "DC Nominal";
BA_ "LongName" SG_ 2365572087 Warning "Warning Active";
BA_ "LongName" SG_ 2365572087 HardwareEnable "Hardware Enable";
BA_ "LongName" SG_ 2365572087 K2DCRunPermissive "K2 Permissive";
BA_ "LongName" SG_ 2365572087 K1PrechargePermissive "K1 Permissive";
BA_ "LongName" SG_ 2365572087 MX2Permissive "MX2 Permissive";
BA_ "LongName" SG_ 2365572087 MX1Permissive "MX1 Permissive";
BA_ "LongName" SG_ 2365572087 DI4 "DI4";
BA_ "LongName" SG_ 2365572087 DI3 "DI3";
BA_ "LongName" SG_ 2365572087 DI2 "DI2";
BA_ "LongName" SG_ 2365572087 DI1 "DI1";
BA_ "LongName" SG_ 2365572087 MessageValidPowerCMD "Power Message Valid";
BA_ "LongName" SG_ 2365572087 MessageValidModeControl "Mode Message Valid";
BA_ "LongName" SG_ 2365572087 MessageValidDcControl "DC Control Message Valid";
BA_ "LongName" SG_ 2365572087 MessageValidCurrentCMD "I Cmd Message Valid";
BA_ "LongName" SG_ 2365572087 PumpFault "Pump Faulted Status";
BA_ "LongName" SG_ 2365572087 PumpRun "Pump Running Status";
BA_ "LongName" SG_ 2566893815 FanSpeed "FanSpeed";
BA_ "LongName" SG_ 2365571831 NetworkVoltage "Line Voltage";
BA_ "LongName" SG_ 2365571831 NetworkFrequency "AC Frequency";
BA_ "LongName" SG_ 2365571831 PhaseSequence "Local Sequence";
BA_ "LongName" SG_ 2365571831 VoltageDetected "Voltage Detected";
BA_ "LongName" SG_ 2365571831 NetworkInSpec "Voltage Nominal";
BA_ "LongName" SG_ 2634008567 DcVoltageHi "DC Link Voltage";
BA_ "LongName" SG_ 2634008567 DcCurrentHi "DC Link Current";
BA_ "LongName" SG_ 2634008567 DcVoltageLo "DC Input Voltage";
BA_ "LongName" SG_ 2634008567 DcCurrentLo "DC Input Current";
BA_ "LongName" SG_ 2634008823 CurrentRefHi_VoltageCtl "Voltage Control Current Reference";
BA_ "LongName" SG_ 2634008823 CurrentRefLo_CurrentCtl "Input Current Reference";
BA_ "LongName" SG_ 2634008823 CurrentRefLo_MPPT "MPPT Current Reference";
BA_ "LongName" SG_ 2634009335 DcMidpointOffset "DcMidpointOffset";
BA_ "LongName" SG_ 2634009335 DcMidpointRipple "DcMidpointRipple";
BA_ "LongName" SG_ 2634009847 RealCurrent_echo "Real Current";
BA_ "LongName" SG_ 2634009847 ReactiveCurrent_echo "Reactive Current";
BA_ "LongName" SG_ 2365571575 CurrentReal "Real Current";
BA_ "LongName" SG_ 2365571575 CurrentReactive "Reactive Current";
BA_ "LongName" SG_ 2365571575 CurrentApparent "Apparent Current";
BA_ "LongName" SG_ 2566902775 VoltageUV "L1-L2";
BA_ "LongName" SG_ 2566902775 VoltageVW "L2-L3";
BA_ "LongName" SG_ 2566902775 VoltageWU "L3-L1";
BA_ "LongName" SG_ 2566903031 VoltageUV "L1-L2";
BA_ "LongName" SG_ 2566903031 VoltageVW "L2-L3";
BA_ "LongName" SG_ 2566903031 VoltageWU "L3-L1";
BA_ "LongName" SG_ 2566903287 dcVoltageLimit_echo "dcVoltageLimit_echo";
BA_ "DisplayDecimalPlaces" SG_ 2566894071 tInternal 1;
BA_ "LongName" SG_ 2566894071 tInternal "tInternal";
BA_ "DisplayDecimalPlaces" SG_ 2566894071 tInlet 1;
BA_ "LongName" SG_ 2566894071 tInlet "tInlet";
BA_ "DisplayDecimalPlaces" SG_ 2566894071 tBridgeA 1;
BA_ "LongName" SG_ 2566894071 tBridgeA "tBridgeA";
BA_ "DisplayDecimalPlaces" SG_ 2566894071 tBridgeB 1;
BA_ "LongName" SG_ 2566894071 tBridgeB "tBridgeB";
BA_ "DisplayDecimalPlaces" SG_ 2566894327 TPvj_A 1;
BA_ "LongName" SG_ 2566894327 TPvj_A "TPvj_A";
BA_ "DisplayDecimalPlaces" SG_ 2566894327 TPvj_B 1;
BA_ "LongName" SG_ 2566894327 TPvj_B "TPvj_B";
BA_ "DisplayDecimalPlaces" SG_ 2566894327 TPvj_C 1;
BA_ "LongName" SG_ 2566894327 TPvj_C "TPvj_C";
BA_ "DisplayDecimalPlaces" SG_ 2566894327 TPvj_D 1;
BA_ "LongName" SG_ 2566894327 TPvj_D "TPvj_D";
BA_ "DisplayDecimalPlaces" SG_ 2566894583 TPvj_E 1;
BA_ "LongName" SG_ 2566894583 TPvj_E "TPvj_E";
BA_ "DisplayDecimalPlaces" SG_ 2566894583 TPvj_F 1;
BA_ "LongName" SG_ 2566894583 TPvj_F "TPvj_F";
BA_ "DisplayDecimalPlaces" SG_ 2566894583 Tvj_max 1;
BA_ "LongName" SG_ 2566894583 Tvj_max "Tvj_max";
BA_ "DisplayDecimalPlaces" SG_ 2566894583 Tsense 1;
BA_ "LongName" SG_ 2566894583 Tsense "Tsense";
BA_ "DisplayDecimalPlaces" SG_ 2566894839 Pl_tot 0;
BA_ "LongName" SG_ 2566894839 Pl_tot "Pl_tot";
BA_ "LongName" SG_ 2566895095 CurrentPS "PS Current";
BA_ "LongName" SG_ 2566895095 CurrentNS "NS Current";
BA_ "LongName" SG_ 2566895095 LineVoltagePS "PS Line Voltage";
BA_ "LongName" SG_ 2566895095 LineVoltageNS "NS Line Voltage";
BA_ "LongName" SG_ 2566895351 CurrentRealPS "Real Current PS";
BA_ "LongName" SG_ 2566895351 CurrentReactivePS "Reactive Current PS";
BA_ "LongName" SG_ 2566895351 CurrentRealNS "Real Current NS";
BA_ "LongName" SG_ 2566895351 CurrentReactiveNS "Reactive Current NS";
BA_ "LongName" SG_ 2566895607 Power "Power";
VAL_ 2649702903 Meta1028 0 "Value" 1 "UserDefault" 2 "FactoryDefault" 3 "Minimum" 4 "Maximum";
VAL_ 2649702903 ReadParam_status1028 0 "Write" 1 "Read" 2 "Error" 3 "N/A";
VAL_ 2649702903 Meta1029 0 "Value" 1 "UserDefault" 2 "FactoryDefault" 3 "Minimum" 4 "Maximum";
VAL_ 2649702903 ReadParam_status1029 0 "Write" 1 "Read" 2 "Error" 3 "N/A";
VAL_ 2649702903 Meta1030 0 "Value" 1 "UserDefault" 2 "FactoryDefault" 3 "Minimum" 4 "Maximum";
VAL_ 2649702903 ReadParam_status1030 0 "Write" 1 "Read" 2 "Error" 3 "N/A";
VAL_ 2649702903 Meta1031 0 "Value" 1 "UserDefault" 2 "FactoryDefault" 3 "Minimum" 4 "Maximum";
VAL_ 2649702903 ReadParam_status1031 0 "Write" 1 "Read" 2 "Error" 3 "N/A";
VAL_ 2649702903 Meta1032 0 "Value" 1 "UserDefault" 2 "FactoryDefault" 3 "Minimum" 4 "Maximum";
VAL_ 2649702903 ReadParam_status1032 0 "Write" 1 "Read" 2 "Error" 3 "N/A";
VAL_ 2649702903 Meta1033 0 "Value" 1 "UserDefault" 2 "FactoryDefault" 3 "Minimum" 4 "Maximum";
VAL_ 2649702903 ReadParam_status1033 0 "Write" 1 "Read" 2 "Error" 3 "N/A";
VAL_ 2649702903 Meta1034 0 "Value" 1 "UserDefault" 2 "FactoryDefault" 3 "Minimum" 4 "Maximum";
VAL_ 2649702903 ReadParam_status1034 0 "Write" 1 "Read" 2 "Error" 3 "N/A";
VAL_ 2649702903 Meta1035 0 "Value" 1 "UserDefault" 2 "FactoryDefault" 3 "Minimum" 4 "Maximum";
VAL_ 2649702903 ReadParam_status1035 0 "Write" 1 "Read" 2 "Error" 3 "N/A";
VAL_ 2649702903 Meta1036 0 "Value" 1 "UserDefault" 2 "FactoryDefault" 3 "Minimum" 4 "Maximum";
VAL_ 2649702903 ReadParam_status1036 0 "Write" 1 "Read" 2 "Error" 3 "N/A";
VAL_ 2649702903 Meta1037 0 "Value" 1 "UserDefault" 2 "FactoryDefault" 3 "Minimum" 4 "Maximum";
VAL_ 2649702903 ReadParam_status1037 0 "Write" 1 "Read" 2 "Error" 3 "N/A";
VAL_ 2649702903 Meta1038 0 "Value" 1 "UserDefault" 2 "FactoryDefault" 3 "Minimum" 4 "Maximum";
VAL_ 2649702903 ReadParam_status1038 0 "Write" 1 "Read" 2 "Error" 3 "N/A";
VAL_ 2649702903 DO5Command 0 "off" 1 "on" 2 "Error" 3 "N/A";
VAL_ 2649702903 DO5Controller 0 "Application" 1 "CAN";
VAL_ 2649702903 InvertDI6 0 "Normal" 1 "Inverted" 2 "Error" 3 "N/A";
VAL_ 2649702903 InvertDI7 0 "Normal" 1 "Inverted" 2 "Error" 3 "N/A";
VAL_ 2649702903 InvertDI8 0 "Normal" 1 "Inverted" 2 "Error" 3 "N/A";
VAL_ 2649702903 InvertDI9 0 "Normal" 1 "Inverted" 2 "Error" 3 "N/A";
VAL_ 2649702903 InvertDO5 0 "Normal" 1 "Inverted" 2 "Error" 3 "N/A";
VAL_ 2649702903 Meta1039 0 "Value" 1 "UserDefault" 2 "FactoryDefault" 3 "Minimum" 4 "Maximum";
VAL_ 2649702903 ReadParam_status1039 0 "Write" 1 "Read" 2 "Error" 3 "N/A";
VAL_ 2649702903 ExternalInhibitFault 0 "Normal" 1 "Fault Active" 2 "Error" 3 "N/A";
VAL_ 2649702903 ExternalInhibitState 0 "EI_NOT_ENABLED" 1 "EI_SYNC_FORCE" 2 "EI_SYNC_COUNT_DOWN" 3 "EI_SYNC_WAIT" 4 "EI_SYNCHRONIZED" 5 "EI_SYNC_LOST" 6 "EI_SYNC_INHIBIT";
VAL_ 2649702903 Meta1040 0 "Value" 1 "UserDefault" 2 "FactoryDefault" 3 "Minimum" 4 "Maximum";
VAL_ 2649702903 ReadParam_status1040 0 "Write" 1 "Read" 2 "Error" 3 "N/A";
VAL_ 2649702903 enable3 0 "Disable" 1 "Enable" 2 "Error" 3 "N/A";
VAL_ 2649702903 Meta1041 0 "Value" 1 "UserDefault" 2 "FactoryDefault" 3 "Minimum" 4 "Maximum";
VAL_ 2649702903 ReadParam_status1041 0 "Write" 1 "Read" 2 "Error" 3 "N/A";
VAL_ 2649702903 enableAutoSync 0 "Disable" 1 "Enable" 2 "Error" 3 "N/A";
VAL_ 2649702903 Meta1042 0 "Value" 1 "UserDefault" 2 "FactoryDefault" 3 "Minimum" 4 "Maximum";
VAL_ 2649702903 ReadParam_status1042 0 "Write" 1 "Read" 2 "Error" 3 "N/A";
VAL_ 2649702903 Meta1043 0 "Value" 1 "UserDefault" 2 "FactoryDefault" 3 "Minimum" 4 "Maximum";
VAL_ 2649702903 ReadParam_status1043 0 "Write" 1 "Read" 2 "Error" 3 "N/A";
VAL_ 2649702903 ActiveInterface 0 "SUNSPEC1" 1 "SUNSPEC2";
VAL_ 2649702903 Meta1044 0 "Value" 1 "UserDefault" 2 "FactoryDefault" 3 "Minimum" 4 "Maximum";
VAL_ 2649702903 ReadParam_status1044 0 "Write" 1 "Read" 2 "Error" 3 "N/A";
VAL_ 2649702903 Meta1045 0 "Value" 1 "UserDefault" 2 "FactoryDefault" 3 "Minimum" 4 "Maximum";
VAL_ 2649702903 ReadParam_status1045 0 "Write" 1 "Read" 2 "Error" 3 "N/A";
VAL_ 2649702903 Meta1046 0 "Value" 1 "UserDefault" 2 "FactoryDefault" 3 "Minimum" 4 "Maximum";
VAL_ 2649702903 ReadParam_status1046 0 "Write" 1 "Read" 2 "Error" 3 "N/A";
VAL_ 2649702903 Meta1047 0 "Value" 1 "UserDefault" 2 "FactoryDefault" 3 "Minimum" 4 "Maximum";
VAL_ 2649702903 ReadParam_status1047 0 "Write" 1 "Read" 2 "Error" 3 "N/A";
VAL_ 2649702903 Meta1048 0 "Value" 1 "UserDefault" 2 "FactoryDefault" 3 "Minimum" 4 "Maximum";
VAL_ 2649702903 ReadParam_status1048 0 "Write" 1 "Read" 2 "Error" 3 "N/A";
VAL_ 2649702903 Meta1049 0 "Value" 1 "UserDefault" 2 "FactoryDefault" 3 "Minimum" 4 "Maximum";
VAL_ 2649702903 ReadParam_status1049 0 "Write" 1 "Read" 2 "Error" 3 "N/A";
VAL_ 2649702903 Meta1050 0 "Value" 1 "UserDefault" 2 "FactoryDefault" 3 "Minimum" 4 "Maximum";
VAL_ 2649702903 ReadParam_status1050 0 "Write" 1 "Read" 2 "Error" 3 "N/A";
VAL_ 2649702903 Meta1051 0 "Value" 1 "UserDefault" 2 "FactoryDefault" 3 "Minimum" 4 "Maximum";
VAL_ 2649702903 ReadParam_status1051 0 "Write" 1 "Read" 2 "Error" 3 "N/A";
VAL_ 2649702903 Meta1052 0 "Value" 1 "UserDefault" 2 "FactoryDefault" 3 "Minimum" 4 "Maximum";
VAL_ 2649702903 ReadParam_status1052 0 "Write" 1 "Read" 2 "Error" 3 "N/A";
VAL_ 2649702903 Meta1053 0 "Value" 1 "UserDefault" 2 "FactoryDefault" 3 "Minimum" 4 "Maximum";
VAL_ 2649702903 ReadParam_status1053 0 "Write" 1 "Read" 2 "Error" 3 "N/A";
VAL_ 2649702903 Meta1054 0 "Value" 1 "UserDefault" 2 "FactoryDefault" 3 "Minimum" 4 "Maximum";
VAL_ 2649702903 ReadParam_status1054 0 "Write" 1 "Read" 2 "Error" 3 "N/A";
VAL_ 2649702903 Meta1055 0 "Value" 1 "UserDefault" 2 "FactoryDefault" 3 "Minimum" 4 "Maximum";
VAL_ 2649702903 ReadParam_status1055 0 "Write" 1 "Read" 2 "Error" 3 "N/A";
VAL_ 2649702903 Meta1056 0 "Value" 1 "UserDefault" 2 "FactoryDefault" 3 "Minimum" 4 "Maximum";
VAL_ 2649702903 ReadParam_status1056 0 "Write" 1 "Read" 2 "Error" 3 "N/A";
VAL_ 2649702903 Meta1057 0 "Value" 1 "UserDefault" 2 "FactoryDefault" 3 "Minimum" 4 "Maximum";
VAL_ 2649702903 ReadParam_status1057 0 "Write" 1 "Read" 2 "Error" 3 "N/A";
VAL_ 2649702903 Meta1058 0 "Value" 1 "UserDefault" 2 "FactoryDefault" 3 "Minimum" 4 "Maximum";
VAL_ 2649702903 ReadParam_status1058 0 "Write" 1 "Read" 2 "Error" 3 "N/A";
VAL_ 2649702903 Meta1059 0 "Value" 1 "UserDefault" 2 "FactoryDefault" 3 "Minimum" 4 "Maximum";
VAL_ 2649702903 ReadParam_status1059 0 "Write" 1 "Read" 2 "Error" 3 "N/A";
VAL_ 2649702903 Meta1060 0 "Value" 1 "UserDefault" 2 "FactoryDefault" 3 "Minimum" 4 "Maximum";
VAL_ 2649702903 ReadParam_status1060 0 "Write" 1 "Read" 2 "Error" 3 "N/A";
VAL_ 2649702903 Meta1061 0 "Value" 1 "UserDefault" 2 "FactoryDefault" 3 "Minimum" 4 "Maximum";
VAL_ 2649702903 ReadParam_status1061 0 "Write" 1 "Read" 2 "Error" 3 "N/A";
VAL_ 2649702903 Meta1062 0 "Value" 1 "UserDefault" 2 "FactoryDefault" 3 "Minimum" 4 "Maximum";
VAL_ 2649702903 ReadParam_status1062 0 "Write" 1 "Read" 2 "Error" 3 "N/A";
VAL_ 2649702903 Meta1063 0 "Value" 1 "UserDefault" 2 "FactoryDefault" 3 "Minimum" 4 "Maximum";
VAL_ 2649702903 ReadParam_status1063 0 "Write" 1 "Read" 2 "Error" 3 "N/A";
VAL_ 2649702903 Meta1064 0 "Value" 1 "UserDefault" 2 "FactoryDefault" 3 "Minimum" 4 "Maximum";
VAL_ 2649702903 ReadParam_status1064 0 "Write" 1 "Read" 2 "Error" 3 "N/A";
VAL_ 2649702903 Meta1065 0 "Value" 1 "UserDefault" 2 "FactoryDefault" 3 "Minimum" 4 "Maximum";
VAL_ 2649702903 ReadParam_status1065 0 "Write" 1 "Read" 2 "Error" 3 "N/A";
VAL_ 2649702903 Meta1066 0 "Value" 1 "UserDefault" 2 "FactoryDefault" 3 "Minimum" 4 "Maximum";
VAL_ 2649702903 ReadParam_status1066 0 "Write" 1 "Read" 2 "Error" 3 "N/A";
VAL_ 2649702903 Meta1067 0 "Value" 1 "UserDefault" 2 "FactoryDefault" 3 "Minimum" 4 "Maximum";
VAL_ 2649702903 ReadParam_status1067 0 "Write" 1 "Read" 2 "Error" 3 "N/A";
VAL_ 2649702903 Meta1068 0 "Value" 1 "UserDefault" 2 "FactoryDefault" 3 "Minimum" 4 "Maximum";
VAL_ 2649702903 ReadParam_status1068 0 "Write" 1 "Read" 2 "Error" 3 "N/A";
VAL_ 2649702903 Meta1069 0 "Value" 1 "UserDefault" 2 "FactoryDefault" 3 "Minimum" 4 "Maximum";
VAL_ 2649702903 ReadParam_status1069 0 "Write" 1 "Read" 2 "Error" 3 "N/A";
VAL_ 2649702903 Meta1070 0 "Value" 1 "UserDefault" 2 "FactoryDefault" 3 "Minimum" 4 "Maximum";
VAL_ 2649702903 ReadParam_status1070 0 "Write" 1 "Read" 2 "Error" 3 "N/A";
VAL_ 2649702903 Meta1071 0 "Value" 1 "UserDefault" 2 "FactoryDefault" 3 "Minimum" 4 "Maximum";
VAL_ 2649702903 ReadParam_status1071 0 "Write" 1 "Read" 2 "Error" 3 "N/A";
VAL_ 2649702903 Meta1072 0 "Value" 1 "UserDefault" 2 "FactoryDefault" 3 "Minimum" 4 "Maximum";
VAL_ 2649702903 ReadParam_status1072 0 "Write" 1 "Read" 2 "Error" 3 "N/A";
VAL_ 2649702903 Meta1073 0 "Value" 1 "UserDefault" 2 "FactoryDefault" 3 "Minimum" 4 "Maximum";
VAL_ 2649702903 ReadParam_status1073 0 "Write" 1 "Read" 2 "Error" 3 "N/A";
VAL_ 2649702903 Meta1074 0 "Value" 1 "UserDefault" 2 "FactoryDefault" 3 "Minimum" 4 "Maximum";
VAL_ 2649702903 ReadParam_status1074 0 "Write" 1 "Read" 2 "Error" 3 "N/A";
VAL_ 2649702903 Meta1075 0 "Value" 1 "UserDefault" 2 "FactoryDefault" 3 "Minimum" 4 "Maximum";
VAL_ 2649702903 ReadParam_status1075 0 "Write" 1 "Read" 2 "Error" 3 "N/A";
VAL_ 2649702903 Meta1076 0 "Value" 1 "UserDefault" 2 "FactoryDefault" 3 "Minimum" 4 "Maximum";
VAL_ 2649702903 ReadParam_status1076 0 "Write" 1 "Read" 2 "Error" 3 "N/A";
VAL_ 2649702903 Meta1077 0 "Value" 1 "UserDefault" 2 "FactoryDefault" 3 "Minimum" 4 "Maximum";
VAL_ 2649702903 ReadParam_status1077 0 "Write" 1 "Read" 2 "Error" 3 "N/A";
VAL_ 2649702903 Meta1078 0 "Value" 1 "UserDefault" 2 "FactoryDefault" 3 "Minimum" 4 "Maximum";
VAL_ 2649702903 ReadParam_status1078 0 "Write" 1 "Read" 2 "Error" 3 "N/A";
VAL_ 2649702903 Meta1079 0 "Value" 1 "UserDefault" 2 "FactoryDefault" 3 "Minimum" 4 "Maximum";
VAL_ 2649702903 ReadParam_status1079 0 "Write" 1 "Read" 2 "Error" 3 "N/A";
VAL_ 2649702903 Meta1080 0 "Value" 1 "UserDefault" 2 "FactoryDefault" 3 "Minimum" 4 "Maximum";
VAL_ 2649702903 ReadParam_status1080 0 "Write" 1 "Read" 2 "Error" 3 "N/A";
VAL_ 2649702903 Meta1081 0 "Value" 1 "UserDefault" 2 "FactoryDefault" 3 "Minimum" 4 "Maximum";
VAL_ 2649702903 ReadParam_status1081 0 "Write" 1 "Read" 2 "Error" 3 "N/A";
VAL_ 2649702903 Meta1082 0 "Value" 1 "UserDefault" 2 "FactoryDefault" 3 "Minimum" 4 "Maximum";
VAL_ 2649702903 ReadParam_status1082 0 "Write" 1 "Read" 2 "Error" 3 "N/A";
VAL_ 2649702903 Meta1083 0 "Value" 1 "UserDefault" 2 "FactoryDefault" 3 "Minimum" 4 "Maximum";
VAL_ 2649702903 ReadParam_status1083 0 "Write" 1 "Read" 2 "Error" 3 "N/A";
VAL_ 2649702903 Meta1084 0 "Value" 1 "UserDefault" 2 "FactoryDefault" 3 "Minimum" 4 "Maximum";
VAL_ 2649702903 ReadParam_status1084 0 "Write" 1 "Read" 2 "Error" 3 "N/A";
VAL_ 2649702903 Meta1085 0 "Value" 1 "UserDefault" 2 "FactoryDefault" 3 "Minimum" 4 "Maximum";
VAL_ 2649702903 ReadParam_status1085 0 "Write" 1 "Read" 2 "Error" 3 "N/A";
VAL_ 2649702903 Meta1086 0 "Value" 1 "UserDefault" 2 "FactoryDefault" 3 "Minimum" 4 "Maximum";
VAL_ 2649702903 ReadParam_status1086 0 "Write" 1 "Read" 2 "Error" 3 "N/A";
VAL_ 2649702903 Meta1087 0 "Value" 1 "UserDefault" 2 "FactoryDefault" 3 "Minimum" 4 "Maximum";
VAL_ 2649702903 ReadParam_status1087 0 "Write" 1 "Read" 2 "Error" 3 "N/A";
VAL_ 2649702903 Meta1088 0 "Value" 1 "UserDefault" 2 "FactoryDefault" 3 "Minimum" 4 "Maximum";
VAL_ 2649702903 ReadParam_status1088 0 "Write" 1 "Read" 2 "Error" 3 "N/A";
VAL_ 2649702903 Meta1089 0 "Value" 1 "UserDefault" 2 "FactoryDefault" 3 "Minimum" 4 "Maximum";
VAL_ 2649702903 ReadParam_status1089 0 "Write" 1 "Read" 2 "Error" 3 "N/A";
VAL_ 2649702903 Meta1090 0 "Value" 1 "UserDefault" 2 "FactoryDefault" 3 "Minimum" 4 "Maximum";
VAL_ 2649702903 ReadParam_status1090 0 "Write" 1 "Read" 2 "Error" 3 "N/A";
VAL_ 2649702903 Meta1091 0 "Value" 1 "UserDefault" 2 "FactoryDefault" 3 "Minimum" 4 "Maximum";
VAL_ 2649702903 ReadParam_status1091 0 "Write" 1 "Read" 2 "Error" 3 "N/A";
VAL_ 2649702903 Meta1092 0 "Value" 1 "UserDefault" 2 "FactoryDefault" 3 "Minimum" 4 "Maximum";
VAL_ 2649702903 ReadParam_status1092 0 "Write" 1 "Read" 2 "Error" 3 "N/A";
VAL_ 2649702903 Meta1093 0 "Value" 1 "UserDefault" 2 "FactoryDefault" 3 "Minimum" 4 "Maximum";
VAL_ 2649702903 ReadParam_status1093 0 "Write" 1 "Read" 2 "Error" 3 "N/A";
VAL_ 2649702903 Meta1094 0 "Value" 1 "UserDefault" 2 "FactoryDefault" 3 "Minimum" 4 "Maximum";
VAL_ 2649702903 ReadParam_status1094 0 "Write" 1 "Read" 2 "Error" 3 "N/A";
VAL_ 2649702903 Meta1095 0 "Value" 1 "UserDefault" 2 "FactoryDefault" 3 "Minimum" 4 "Maximum";
VAL_ 2649702903 ReadParam_status1095 0 "Write" 1 "Read" 2 "Error" 3 "N/A";
VAL_ 2649702903 Meta1096 0 "Value" 1 "UserDefault" 2 "FactoryDefault" 3 "Minimum" 4 "Maximum";
VAL_ 2649702903 ReadParam_status1096 0 "Write" 1 "Read" 2 "Error" 3 "N/A";
VAL_ 2649702903 Meta1097 0 "Value" 1 "UserDefault" 2 "FactoryDefault" 3 "Minimum" 4 "Maximum";
VAL_ 2649702903 ReadParam_status1097 0 "Write" 1 "Read" 2 "Error" 3 "N/A";
VAL_ 2649702903 Meta1098 0 "Value" 1 "UserDefault" 2 "FactoryDefault" 3 "Minimum" 4 "Maximum";
VAL_ 2649702903 ReadParam_status1098 0 "Write" 1 "Read" 2 "Error" 3 "N/A";
VAL_ 2649702903 Meta1099 0 "Value" 1 "UserDefault" 2 "FactoryDefault" 3 "Minimum" 4 "Maximum";
VAL_ 2649702903 ReadParam_status1099 0 "Write" 1 "Read" 2 "Error" 3 "N/A";
VAL_ 2649702903 Meta1100 0 "Value" 1 "UserDefault" 2 "FactoryDefault" 3 "Minimum" 4 "Maximum";
VAL_ 2649702903 ReadParam_status1100 0 "Write" 1 "Read" 2 "Error" 3 "N/A";
VAL_ 2649702903 Meta1101 0 "Value" 1 "UserDefault" 2 "FactoryDefault" 3 "Minimum" 4 "Maximum";
VAL_ 2649702903 ReadParam_status1101 0 "Write" 1 "Read" 2 "Error" 3 "N/A";
VAL_ 2649702903 Trigger 0 "Disable" 1 "Enable" 2 "Error" 3 "N/A";
VAL_ 2649702903 allowWPhaseOV 0 "No" 1 "Yes" 2 "Error" 3 "N/A";
VAL_ 2649702903 Meta1102 0 "Value" 1 "UserDefault" 2 "FactoryDefault" 3 "Minimum" 4 "Maximum";
VAL_ 2649702903 ReadParam_status1102 0 "Write" 1 "Read" 2 "Error" 3 "N/A";
VAL_ 2649702903 Enable8 0 "Disable" 1 "Enable" 2 "Error" 3 "N/A";
VAL_ 2649702903 Meta1103 0 "Value" 1 "UserDefault" 2 "FactoryDefault" 3 "Minimum" 4 "Maximum";
VAL_ 2649702903 ReadParam_status1103 0 "Write" 1 "Read" 2 "Error" 3 "N/A";
VAL_ 2649702903 Meta1104 0 "Value" 1 "UserDefault" 2 "FactoryDefault" 3 "Minimum" 4 "Maximum";
VAL_ 2649702903 ReadParam_status1104 0 "Write" 1 "Read" 2 "Error" 3 "N/A";
VAL_ 2649702903 Meta1105 0 "Value" 1 "UserDefault" 2 "FactoryDefault" 3 "Minimum" 4 "Maximum";
VAL_ 2649702903 ReadParam_status1105 0 "Write" 1 "Read" 2 "Error" 3 "N/A";
VAL_ 2649702903 LogDataEnable 0 "Disable" 1 "Enable" 2 "Error" 3 "N/A";
VAL_ 2649702903 Meta1106 0 "Value" 1 "UserDefault" 2 "FactoryDefault" 3 "Minimum" 4 "Maximum";
VAL_ 2649702903 ReadParam_status1106 0 "Write" 1 "Read" 2 "Error" 3 "N/A";
VAL_ 2649702903 RefMode 0 "Fixed" 1 "Autonomous";
VAL_ 2649702903 Meta1107 0 "Value" 1 "UserDefault" 2 "FactoryDefault" 3 "Minimum" 4 "Maximum";
VAL_ 2649702903 ReadParam_status1107 0 "Write" 1 "Read" 2 "Error" 3 "N/A";
VAL_ 2649702903 Meta1108 0 "Value" 1 "UserDefault" 2 "FactoryDefault" 3 "Minimum" 4 "Maximum";
VAL_ 2649702903 ReadParam_status1108 0 "Write" 1 "Read" 2 "Error" 3 "N/A";
VAL_ 2649702903 Meta1109 0 "Value" 1 "UserDefault" 2 "FactoryDefault" 3 "Minimum" 4 "Maximum";
VAL_ 2649702903 ReadParam_status1109 0 "Write" 1 "Read" 2 "Error" 3 "N/A";
VAL_ 2649702903 Meta1110 0 "Value" 1 "UserDefault" 2 "FactoryDefault" 3 "Minimum" 4 "Maximum";
VAL_ 2649702903 ReadParam_status1110 0 "Write" 1 "Read" 2 "Error" 3 "N/A";
VAL_ 2649702903 Meta1111 0 "Value" 1 "UserDefault" 2 "FactoryDefault" 3 "Minimum" 4 "Maximum";
VAL_ 2649702903 ReadParam_status1111 0 "Write" 1 "Read" 2 "Error" 3 "N/A";
VAL_ 2649702903 Meta1112 0 "Value" 1 "UserDefault" 2 "FactoryDefault" 3 "Minimum" 4 "Maximum";
VAL_ 2649702903 ReadParam_status1112 0 "Write" 1 "Read" 2 "Error" 3 "N/A";
VAL_ 2649702903 Meta1113 0 "Value" 1 "UserDefault" 2 "FactoryDefault" 3 "Minimum" 4 "Maximum";
VAL_ 2649702903 ReadParam_status1113 0 "Write" 1 "Read" 2 "Error" 3 "N/A";
VAL_ 2649702903 Meta1114 0 "Value" 1 "UserDefault" 2 "FactoryDefault" 3 "Minimum" 4 "Maximum";
VAL_ 2649702903 ReadParam_status1114 0 "Write" 1 "Read" 2 "Error" 3 "N/A";
VAL_ 2649702903 Meta1115 0 "Value" 1 "UserDefault" 2 "FactoryDefault" 3 "Minimum" 4 "Maximum";
VAL_ 2649702903 ReadParam_status1115 0 "Write" 1 "Read" 2 "Error" 3 "N/A";
VAL_ 2582594039 CCPResponse_MUX 0 "Raw" 1 "Connect" 2 "SetMTA" 4 "Upload" 7 "Disconnect";
VAL_ 2634006775 PhaseSequence 0 "Negative" 1 "Positive" 2 "Invalid" 3 "N/A";
VAL_ 2634006775 VoltageDetected 0 "No_Voltage" 1 "Voltage_Detected" 2 "Error" 3 "N/A";
VAL_ 2634006775 NetworkInSpec 0 "None" 1 "Available" 2 "Error" 3 "N/A";
VAL_ 2365572087 WarningClr_echo 0 "Normal" 1 "Clear Warnings" 2 "Error" 3 "N/A";
VAL_ 2365572087 IslandReconnect_echo 0 "Normal" 1 "Reconnect" 2 "Error" 3 "N/A";
VAL_ 2365572087 ProtBusSequence 0 "Disconnecting" 1 "Disconnected" 2 "Synchronizing" 3 "Synchronized" 4 "Connecting" 5 "Connected" 6 "N/A";
VAL_ 2365572087 FaultClr_echo 0 "Normal" 1 "Clear Faults" 2 "Error" 3 "N/A";
VAL_ 2365572087 Enable_echo 0 "Disable" 1 "Enable" 2 "Error" 3 "N/A";
VAL_ 2365572087 State 0 "Power On Reset" 1 "Ready" 2 "Following" 3 "Fault" 4 "Forming" 5 "Reconnect Delay" 6 "N/A" 7 "Grid Lost" 8 "Charging" 9 "Ride-Through" 10 "Cessation" 11 "Transitioning" 12 "Inhibited" 13 "Connect Delay" 14 "N/A" 15 "N/A";
VAL_ 2365572087 PowerCircuitEnabled 0 "Disable" 1 "Enable" 2 "Error" 3 "N/A";
VAL_ 2365572087 PowerAvailDC 0 "None" 1 "Available" 2 "Error" 3 "N/A";
VAL_ 2365572087 Warning 0 "Normal" 1 "Warning Active" 2 "Error" 3 "N/A";
VAL_ 2365572087 HardwareEnable 0 "Not Active" 1 "Active" 2 "Error" 3 "N/A";
VAL_ 2365572087 K2DCRunPermissive 0 "Open" 1 "Closed" 2 "Error" 3 "N/A";
VAL_ 2365572087 K1PrechargePermissive 0 "Open" 1 "Closed" 2 "Error" 3 "N/A";
VAL_ 2365572087 MX2Permissive 0 "Open" 1 "Closed" 2 "Error" 3 "N/A";
VAL_ 2365572087 MX1Permissive 0 "Open" 1 "Closed" 2 "Error" 3 "N/A";
VAL_ 2365572087 DI4 0 "off" 1 "on" 2 "Error" 3 "N/A";
VAL_ 2365572087 DI3 0 "off" 1 "on" 2 "Error" 3 "N/A";
VAL_ 2365572087 DI2 0 "off" 1 "on" 2 "Error" 3 "N/A";
VAL_ 2365572087 DI1 0 "off" 1 "on" 2 "Error" 3 "N/A";
VAL_ 2365572087 MessageValidPowerCMD 0 "Invalid" 1 "Valid" 2 "Error" 3 "N/A";
VAL_ 2365572087 MessageValidModeControl 0 "Invalid" 1 "Valid" 2 "Error" 3 "N/A";
VAL_ 2365572087 MessageValidDcControl 0 "Invalid" 1 "Valid" 2 "Error" 3 "N/A";
VAL_ 2365572087 MessageValidCurrentCMD 0 "Invalid" 1 "Valid" 2 "Error" 3 "N/A";
VAL_ 2365572087 PumpFault 0 "Not Active" 1 "Active" 2 "Error" 3 "N/A";
VAL_ 2365572087 PumpRun 0 "Not Active" 1 "Active" 2 "Error" 3 "N/A";
VAL_ 2365571831 PhaseSequence 0 "Negative" 1 "Positive" 2 "Invalid" 3 "N/A";
VAL_ 2365571831 VoltageDetected 0 "No_Voltage" 1 "Voltage_Detected" 2 "Error" 3 "N/A";
VAL_ 2365571831 NetworkInSpec 0 "None" 1 "Available" 2 "Error" 3 "N/A";
